VERSION ""

NS_ :

BS_:

BU_: EMS EAS

BO_ 2566764542 DM25: 13 Vector__XXX
 SG_ OccurenceCount1 : 32|7@1+ (1,0) [0|126] "" Vector__XXX
 SG_ SPNConversionMethod1 : 39|1@1+ (1,0) [0|1] "" Vector__XXX
 SG_ FailureModeIdentifier1 : 24|5@1+ (1,0) [0|0] "" Vector__XXX
 SG_ SPN1 : 8|16@1+ (1,0) [0|65536] "" Vector__XXX
 SG_ ExpandedFreezeFrameLength : 0|8@1+ (1,0) [0|255] "byte" Vector__XXX
 SG_ SPN1High : 29|3@1+ (1,0) [0|7] "" Vector__XXX

BO_ 2566764286 DM24: 12 Vector__XXX
 SG_ SPNSupported1High : 21|3@1+ (1,0) [0|7] "" Vector__XXX
 SG_ SPNSupportTypeSTR3 : 82|1@1+ (1,0) [0|1] "" Vector__XXX
 SG_ SPNSupportTypeSTR2 : 50|1@1+ (1,0) [0|1] "" Vector__XXX
 SG_ SPNSupportTypeEFF3 : 80|1@1+ (1,0) [0|1] "" Vector__XXX
 SG_ SPNSupportTypeEFF2 : 48|1@1+ (1,0) [0|1] "" Vector__XXX
 SG_ SPNSupportTypeDS3 : 81|1@1+ (1,0) [0|1] "" Vector__XXX
 SG_ SPNSupportTypeDS2 : 49|1@1+ (1,0) [0|1] "" Vector__XXX
 SG_ SPNSupported3High : 85|3@1+ (1,0) [0|7] "" Vector__XXX
 SG_ SPNSupported2High : 53|3@1+ (1,0) [0|7] "" Vector__XXX
 SG_ SPNSupported3 : 64|16@1+ (1,0) [0|65535] "" Vector__XXX
 SG_ SPNSupported2 : 32|16@1+ (1,0) [0|65535] "" Vector__XXX
 SG_ SPNDataLength3 : 88|8@1+ (1,0) [0|240] "" Vector__XXX
 SG_ SPNSupportTypeSTR1 : 18|1@1+ (1,0) [0|1] "" Vector__XXX
 SG_ SPNSupportTypeDS1 : 17|1@1+ (1,0) [0|1] "" Vector__XXX
 SG_ SPNSupportTypeEFF1 : 16|1@1+ (1,0) [0|1] "" Vector__XXX
 SG_ SPNDataLength2 : 56|8@1+ (1,0) [0|240] "" Vector__XXX
 SG_ SPNDataLength1 : 24|8@1+ (1,0) [0|240] "" Vector__XXX
 SG_ SPNSupported1 : 0|16@1+ (1,0) [0|65535] "" Vector__XXX

BO_ 2555576062 DM23: 22 Vector__XXX
 SG_ FlashRedStopLamp : 12|2@1+ (1,0) [0|3] "" Vector__XXX
 SG_ FlashProtectLamp : 8|2@1+ (1,0) [0|3] "" Vector__XXX
 SG_ FlashMalfuncIndicatorLamp : 14|2@1+ (1,0) [0|3] "" Vector__XXX
 SG_ SPN5 : 144|16@1+ (1,0) [0|65536] "" Vector__XXX
 SG_ SPN4 : 112|16@1+ (1,0) [0|65536] "" Vector__XXX
 SG_ SPN3 : 80|16@1+ (1,0) [0|65536] "" Vector__XXX
 SG_ SPN2 : 48|16@1+ (1,0) [0|65536] "" Vector__XXX
 SG_ FlashAmberWarningLamp : 10|2@1+ (1,0) [0|3] "" Vector__XXX
 SG_ FailureModeIdentifier5 : 160|5@1+ (1,0) [0|0] "" Vector__XXX
 SG_ FailureModeIdentifier4 : 128|5@1+ (1,0) [0|0] "" Vector__XXX
 SG_ OccurenceCount1 : 40|7@1+ (1,0) [0|126] "" Vector__XXX
 SG_ SPNConversionMethod1 : 47|1@1+ (1,0) [0|1] "" Vector__XXX
 SG_ FailureModeIdentifier1 : 32|5@1+ (1,0) [0|0] "" Vector__XXX
 SG_ SPN1 : 16|16@1+ (1,0) [0|65536] "" Vector__XXX
 SG_ MalfunctionIndicatorLampStatus : 6|2@1+ (1,0) [0|3] "" Vector__XXX
 SG_ RedStopLampState : 4|2@1+ (1,0) [0|3] "" Vector__XXX
 SG_ AmberWarningLampStatus : 2|2@1+ (1,0) [0|3] "" Vector__XXX
 SG_ ProtectLampStatus : 0|2@1+ (1,0) [0|3] "" Vector__XXX
 SG_ FailureModeIdentifier3 : 96|5@1+ (1,0) [0|0] "" Vector__XXX
 SG_ FailureModeIdentifier2 : 64|5@1+ (1,0) [0|0] "" Vector__XXX
 SG_ SPNConversionMethod5 : 175|1@1+ (1,0) [0|1] "" Vector__XXX
 SG_ SPNConversionMethod4 : 143|1@1+ (1,0) [0|1] "" Vector__XXX
 SG_ SPNConversionMethod3 : 111|1@1+ (1,0) [0|1] "" Vector__XXX
 SG_ SPNConversionMethod2 : 79|1@1+ (1,0) [0|1] "" Vector__XXX
 SG_ OccurenceCount5 : 168|7@1+ (1,0) [0|126] "" Vector__XXX
 SG_ OccurenceCount4 : 136|7@1+ (1,0) [0|126] "" Vector__XXX
 SG_ OccurenceCount3 : 104|7@1+ (1,0) [0|126] "" Vector__XXX
 SG_ OccurenceCount2 : 72|7@1+ (1,0) [0|126] "" Vector__XXX
 SG_ SPN5High : 165|3@1+ (1,0) [0|7] "" Vector__XXX
 SG_ SPN4High : 133|3@1+ (1,0) [0|7] "" Vector__XXX
 SG_ SPN3High : 101|3@1+ (1,0) [0|7] "" Vector__XXX
 SG_ SPN2High : 69|3@1+ (1,0) [0|7] "" Vector__XXX
 SG_ SPN1High : 37|3@1+ (1,0) [0|7] "" Vector__XXX

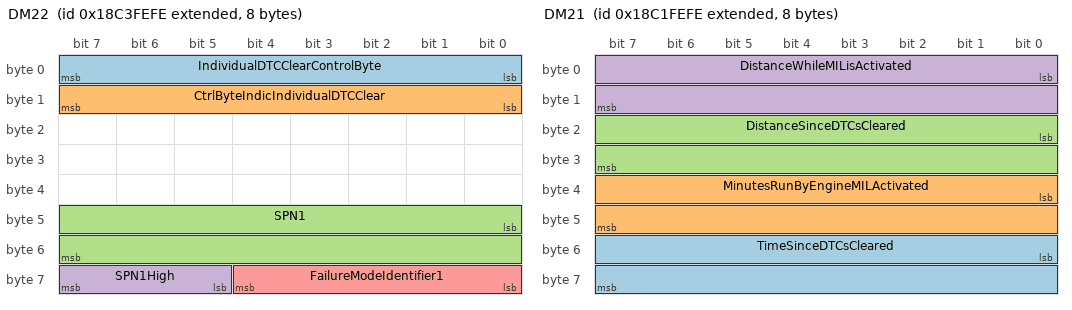
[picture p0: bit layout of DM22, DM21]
BO_ 2562981630 DM22: 8 Vector__XXX
 SG_ IndividualDTCClearControlByte : 0|8@1+ (1,0) [0|255] "" Vector__XXX
 SG_ CtrlByteIndicIndividualDTCClear : 8|8@1+ (1,0) [0|255] "" Vector__XXX
 SG_ SPN1 : 40|16@1+ (1,0) [0|65536] "" Vector__XXX
 SG_ SPN1High : 61|3@1+ (1,0) [0|7] "" Vector__XXX
 SG_ FailureModeIdentifier1 : 56|5@1+ (1,0) [0|0] "" Vector__XXX

BO_ 2562850558 DM21: 8 Vector__XXX
 SG_ TimeSinceDTCsCleared : 48|16@1+ (1,0) [0|64255] "min" Vector__XXX
 SG_ MinutesRunByEngineMILActivated : 32|16@1+ (1,0) [0|64255] "min" Vector__XXX
 SG_ DistanceSinceDTCsCleared : 16|16@1+ (1,0) [0|64255] "km" Vector__XXX
 SG_ DistanceWhileMILisActivated : 0|16@1+ (1,0) [0|64255] "km" Vector__XXX

BO_ 2562916094 DM20: 11 Vector__XXX
 SG_ ApplSysMonitorDenominator : 72|16@1+ (1,0) [0|65535] "" Vector__XXX
 SG_ ApplSysMonitorNumerator : 56|16@1+ (1,0) [0|65535] "" Vector__XXX
 SG_ SPNofApplSysMonitor : 32|24@1+ (1,0) [0|524287] "" Vector__XXX
 SG_ OBDMonitoringCondEncountered : 16|16@1+ (1,0) [0|65535] "" Vector__XXX
 SG_ IgnitionCycleCounter : 0|16@1+ (1,0) [0|65535] "" Vector__XXX

BO_ 2566835198 DM2: 22 Vector__XXX
 SG_ SPN5 : 144|16@1+ (1,0) [0|65536] "" Vector__XXX
 SG_ SPN4 : 112|16@1+ (1,0) [0|65536] "" Vector__XXX
 SG_ SPN3 : 80|16@1+ (1,0) [0|65536] "" Vector__XXX
 SG_ SPN2 : 48|16@1+ (1,0) [0|65536] "" Vector__XXX
 SG_ FailureModeIdentifier5 : 160|5@1+ (1,0) [0|0] "" Vector__XXX
 SG_ FailureModeIdentifier4 : 128|5@1+ (1,0) [0|0] "" Vector__XXX
 SG_ OccurenceCount1 : 40|7@1+ (1,0) [0|126] "" Vector__XXX
 SG_ SPNConversionMethod1 : 47|1@1+ (1,0) [0|1] "" Vector__XXX
 SG_ FailureModeIdentifier1 : 32|5@1+ (1,0) [0|0] "" Vector__XXX
 SG_ SPN1 : 16|16@1+ (1,0) [0|65536] "" Vector__XXX
 SG_ MalfunctionIndicatorLampStatus : 6|2@1+ (1,0) [0|3] "" Vector__XXX
 SG_ RedStopLampState : 4|2@1+ (1,0) [0|3] "" Vector__XXX
 SG_ AmberWarningLampStatus : 2|2@1+ (1,0) [0|3] "" Vector__XXX
 SG_ ProtectLampStatus : 0|2@1+ (1,0) [0|3] "" Vector__XXX
 SG_ FailureModeIdentifier3 : 96|5@1+ (1,0) [0|0] "" Vector__XXX
 SG_ FlashRedStopLamp : 12|2@1+ (1,0) [0|3] "" Vector__XXX
 SG_ FlashProtectLamp : 8|2@1+ (1,0) [0|3] "" Vector__XXX
 SG_ FlashMalfuncIndicatorLamp : 14|2@1+ (1,0) [0|3] "" Vector__XXX
 SG_ FlashAmberWarningLamp : 10|2@1+ (1,0) [0|3] "" Vector__XXX
 SG_ FailureModeIdentifier2 : 64|5@1+ (1,0) [0|0] "" Vector__XXX
 SG_ SPNConversionMethod5 : 175|1@1+ (1,0) [0|1] "" Vector__XXX
 SG_ SPNConversionMethod4 : 143|1@1+ (1,0) [0|1] "" Vector__XXX
 SG_ SPNConversionMethod3 : 111|1@1+ (1,0) [0|1] "" Vector__XXX
 SG_ SPNConversionMethod2 : 79|1@1+ (1,0) [0|1] "" Vector__XXX
 SG_ OccurenceCount5 : 168|7@1+ (1,0) [0|126] "" Vector__XXX
 SG_ OccurenceCount4 : 136|7@1+ (1,0) [0|126] "" Vector__XXX
 SG_ OccurenceCount3 : 104|7@1+ (1,0) [0|126] "" Vector__XXX
 SG_ OccurenceCount2 : 72|7@1+ (1,0) [0|126] "" Vector__XXX
 SG_ SPN5High : 165|3@1+ (1,0) [0|7] "" Vector__XXX
 SG_ SPN4High : 133|3@1+ (1,0) [0|7] "" Vector__XXX
 SG_ SPN3High : 101|3@1+ (1,0) [0|7] "" Vector__XXX
 SG_ SPN2High : 69|3@1+ (1,0) [0|7] "" Vector__XXX
 SG_ SPN1High : 37|3@1+ (1,0) [0|7] "" Vector__XXX

BO_ 2564030206 DM19: 20 Vector__XXX
 SG_ CalibrationID4 : 128|32@1+ (1,0) [0|4294967295] "" Vector__XXX
 SG_ CalibrationID3 : 96|32@1+ (1,0) [0|4294967295] "" Vector__XXX
 SG_ CalibrationID2 : 64|32@1+ (1,0) [0|4294967295] "" Vector__XXX
 SG_ CalibrationID1 : 32|32@1+ (1,0) [0|4294967295] "" Vector__XXX
 SG_ CalibrationVerificationNumber : 0|32@1+ (1,0) [0|4294967295] "" Vector__XXX

BO_ 2564226814 DM17: 8 Vector__XXX

BO_ 2564292350 DM16: 8 Vector__XXX
 SG_ NumberOfOccurance : 0|8@1+ (1,0) [0|0] "" Vector__XXX

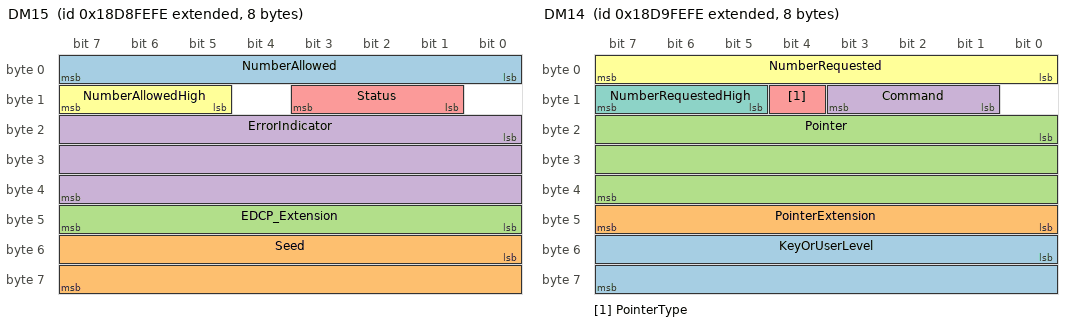
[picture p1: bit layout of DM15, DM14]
BO_ 2564357886 DM15: 8 Vector__XXX
 SG_ NumberAllowed : 0|8@1+ (1,0) [0|2047] "" Vector__XXX
 SG_ Seed : 48|16@1+ (1,0) [0|65535] "" Vector__XXX
 SG_ EDCP_Extension : 40|8@1+ (1,0) [0|255] "" Vector__XXX
 SG_ ErrorIndicator : 16|24@1+ (1,0) [0|16777215] "" Vector__XXX
 SG_ Status : 9|3@1+ (1,0) [0|7] "" Vector__XXX
 SG_ NumberAllowedHigh : 13|3@1+ (1,0) [0|7] "" Vector__XXX

BO_ 2564423422 DM14: 8 Vector__XXX
 SG_ KeyOrUserLevel : 48|16@1+ (1,0) [0|65535] "" Vector__XXX
 SG_ PointerExtension : 40|8@1+ (1,0) [0|255] "" Vector__XXX
 SG_ Pointer : 16|24@1+ (1,0) [0|16777215] "" Vector__XXX
 SG_ Command : 9|3@1+ (1,0) [0|7] "" Vector__XXX
 SG_ PointerType : 12|1@1+ (1,0) [0|1] "" Vector__XXX
 SG_ NumberRequested : 0|8@1+ (1,0) [0|2047] "" Vector__XXX
 SG_ NumberRequestedHigh : 13|3@1+ (1,0) [0|7] "" Vector__XXX

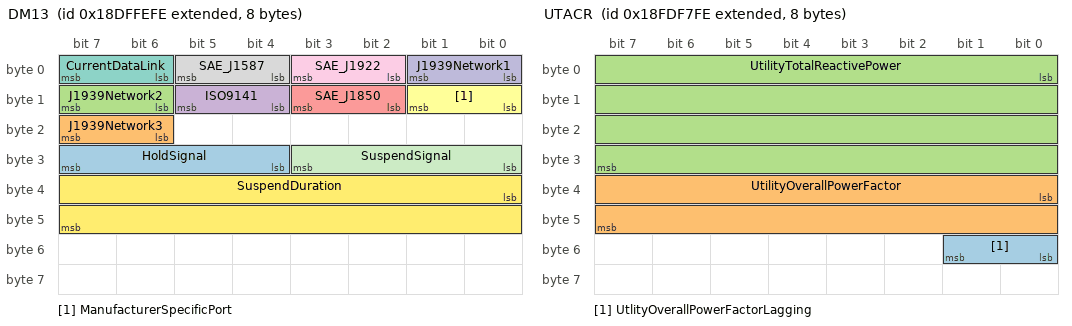
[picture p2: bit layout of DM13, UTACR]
BO_ 2564816638 DM13: 8 Vector__XXX
 SG_ HoldSignal : 28|4@1+ (1,0) [0|15] "" Vector__XXX
 SG_ J1939Network3 : 22|2@1+ (1,0) [0|3] "" Vector__XXX
 SG_ J1939Network2 : 14|2@1+ (1,0) [0|3] "" Vector__XXX
 SG_ ISO9141 : 12|2@1+ (1,0) [0|3] "" Vector__XXX
 SG_ SAE_J1850 : 10|2@1+ (1,0) [0|3] "" Vector__XXX
 SG_ ManufacturerSpecificPort : 8|2@1+ (1,0) [0|3] "" Vector__XXX
 SG_ CurrentDataLink : 6|2@1+ (1,0) [0|3] "" Vector__XXX
 SG_ SAE_J1587 : 4|2@1+ (1,0) [0|3] "" Vector__XXX
 SG_ SAE_J1922 : 2|2@1+ (1,0) [0|3] "" Vector__XXX
 SG_ J1939Network1 : 0|2@1+ (1,0) [0|3] "" Vector__XXX
 SG_ SuspendSignal : 24|4@1+ (1,0) [0|15] "" Vector__XXX
 SG_ SuspendDuration : 32|16@1+ (1,0) [0|64255] "seconds" Vector__XXX

BO_ 2566837502 DM12: 22 Vector__XXX
 SG_ SPN5 : 144|16@1+ (1,0) [0|65536] "" Vector__XXX
 SG_ SPN4 : 112|16@1+ (1,0) [0|65536] "" Vector__XXX
 SG_ SPN3 : 80|16@1+ (1,0) [0|65536] "" Vector__XXX
 SG_ SPN2 : 48|16@1+ (1,0) [0|65536] "" Vector__XXX
 SG_ FlashRedStopLamp : 12|2@1+ (1,0) [0|3] "" Vector__XXX
 SG_ FlashProtectLamp : 8|2@1+ (1,0) [0|3] "" Vector__XXX
 SG_ FailureModeIdentifier5 : 160|5@1+ (1,0) [0|0] "" Vector__XXX
 SG_ FailureModeIdentifier4 : 128|5@1+ (1,0) [0|0] "" Vector__XXX
 SG_ FailureModeIdentifier3 : 96|5@1+ (1,0) [0|0] "" Vector__XXX
 SG_ OccurenceCount1 : 40|7@1+ (1,0) [0|126] "" Vector__XXX
 SG_ SPNConversionMethod1 : 47|1@1+ (1,0) [0|1] "" Vector__XXX
 SG_ FailureModeIdentifier1 : 32|5@1+ (1,0) [0|0] "" Vector__XXX
 SG_ SPN1 : 16|16@1+ (1,0) [0|65536] "" Vector__XXX
 SG_ MalfunctionIndicatorLampStatus : 6|2@1+ (1,0) [0|3] "" Vector__XXX
 SG_ RedStopLampState : 4|2@1+ (1,0) [0|3] "" Vector__XXX
 SG_ AmberWarningLampStatus : 2|2@1+ (1,0) [0|3] "" Vector__XXX
 SG_ ProtectLampStatus : 0|2@1+ (1,0) [0|3] "" Vector__XXX
 SG_ FlashMalfuncIndicatorLamp : 14|2@1+ (1,0) [0|3] "" Vector__XXX
 SG_ FlashAmberWarningLamp : 10|2@1+ (1,0) [0|3] "" Vector__XXX
 SG_ FailureModeIdentifier2 : 64|5@1+ (1,0) [0|0] "" Vector__XXX
 SG_ SPNConversionMethod5 : 175|1@1+ (1,0) [0|1] "" Vector__XXX
 SG_ SPNConversionMethod4 : 143|1@1+ (1,0) [0|1] "" Vector__XXX
 SG_ SPNConversionMethod3 : 111|1@1+ (1,0) [0|1] "" Vector__XXX
 SG_ SPNConversionMethod2 : 79|1@1+ (1,0) [0|1] "" Vector__XXX
 SG_ OccurenceCount5 : 168|7@1+ (1,0) [0|126] "" Vector__XXX
 SG_ OccurenceCount4 : 136|7@1+ (1,0) [0|126] "" Vector__XXX
 SG_ OccurenceCount3 : 104|7@1+ (1,0) [0|126] "" Vector__XXX
 SG_ OccurenceCount2 : 72|7@1+ (1,0) [0|126] "" Vector__XXX
 SG_ SPN5High : 165|3@1+ (1,0) [0|7] "" Vector__XXX
 SG_ SPN4High : 133|3@1+ (1,0) [0|7] "" Vector__XXX
 SG_ SPN3High : 101|3@1+ (1,0) [0|7] "" Vector__XXX
 SG_ SPN2High : 69|3@1+ (1,0) [0|7] "" Vector__XXX
 SG_ SPN1High : 37|3@1+ (1,0) [0|7] "" Vector__XXX

BO_ 2566837246 DM11: 0 Vector__XXX

BO_ 2566836990 DM10: 8 Vector__XXX
 SG_ TestIdentifierSupported : 0|64@1+ (1,0) [1|1.8446744074E+019] "" Vector__XXX

BO_ 2566834942 DM1: 22 Vector__XXX
 SG_ SPN5 : 144|16@1+ (1,0) [0|65536] "" Vector__XXX
 SG_ SPN4 : 112|16@1+ (1,0) [0|65536] "" Vector__XXX
 SG_ SPN3 : 80|16@1+ (1,0) [0|65536] "" Vector__XXX
 SG_ SPN2 : 48|16@1+ (1,0) [0|65536] "" Vector__XXX
 SG_ FailureModeIdentifier5 : 160|5@1+ (1,0) [0|0] "" Vector__XXX
 SG_ FailureModeIdentifier4 : 128|5@1+ (1,0) [0|0] "" Vector__XXX
 SG_ FailureModeIdentifier3 : 96|5@1+ (1,0) [0|0] "" Vector__XXX
 SG_ FlashRedStopLamp : 12|2@1+ (1,0) [0|3] "" Vector__XXX
 SG_ FlashProtectLamp : 8|2@1+ (1,0) [0|3] "" Vector__XXX
 SG_ FlashMalfuncIndicatorLamp : 14|2@1+ (1,0) [0|3] "" Vector__XXX
 SG_ FlashAmberWarningLamp : 10|2@1+ (1,0) [0|3] "" Vector__XXX
 SG_ MalfunctionIndicatorLampStatus : 6|2@1+ (1,0) [0|3] "" Vector__XXX
 SG_ AmberWarningLampStatus : 2|2@1+ (1,0) [0|3] "" Vector__XXX
 SG_ OccurenceCount1 : 40|7@1+ (1,0) [0|126] "" Vector__XXX
 SG_ SPNConversionMethod1 : 47|1@1+ (1,0) [0|1] "" Vector__XXX
 SG_ FailureModeIdentifier1 : 32|5@1+ (1,0) [0|0] "" Vector__XXX
 SG_ SPN1 : 16|16@1+ (1,0) [0|65536] "" Vector__XXX
 SG_ RedStopLampState : 4|2@1+ (1,0) [0|3] "" Vector__XXX
 SG_ ProtectLampStatus : 0|2@1+ (1,0) [0|3] "" Vector__XXX
 SG_ FailureModeIdentifier2 : 64|5@1+ (1,0) [0|0] "" Vector__XXX
 SG_ SPNConversionMethod5 : 175|1@1+ (1,0) [0|1] "" Vector__XXX
 SG_ SPNConversionMethod4 : 143|1@1+ (1,0) [0|1] "" Vector__XXX
 SG_ SPNConversionMethod3 : 111|1@1+ (1,0) [0|1] "" Vector__XXX
 SG_ SPNConversionMethod2 : 79|1@1+ (1,0) [0|1] "" Vector__XXX
 SG_ OccurenceCount5 : 168|7@1+ (1,0) [0|126] "" Vector__XXX
 SG_ OccurenceCount4 : 136|7@1+ (1,0) [0|126] "" Vector__XXX
 SG_ OccurenceCount3 : 104|7@1+ (1,0) [0|126] "" Vector__XXX
 SG_ OccurenceCount2 : 72|7@1+ (1,0) [0|126] "" Vector__XXX
 SG_ SPN5High : 165|3@1+ (1,0) [0|7] "" Vector__XXX
 SG_ SPN4High : 133|3@1+ (1,0) [0|7] "" Vector__XXX
 SG_ SPN3High : 101|3@1+ (1,0) [0|7] "" Vector__XXX
 SG_ SPN2High : 69|3@1+ (1,0) [0|7] "" Vector__XXX
 SG_ SPN1High : 37|3@1+ (1,0) [0|7] "" Vector__XXX

BO_ 2566780926 UTACR: 8 Vector__XXX
 SG_ UtlityOverallPowerFactorLagging : 48|2@1+ (1,0) [0|3] "" Vector__XXX
 SG_ UtilityOverallPowerFactor : 32|16@1+ (1,-1) [-1|2.92181] "" Vector__XXX
 SG_ UtilityTotalReactivePower : 0|32@1+ (1,-2000000000) [-2000000000|2211081215] "VA" Vector__XXX

BO_ 2566781182 UTACP: 8 Vector__XXX
 SG_ UtilityTotalApparentPower : 32|32@1+ (1,-2000000000) [-2000000000|2211081215] "VA" Vector__XXX
 SG_ UtilityTotalRealPower : 0|32@1+ (1,-2000000000) [-2000000000|2211081215] "VA" Vector__XXX

BO_ 2566778366 UTACE: 8 Vector__XXX
 SG_ UtilityTotalKWHoursImport : 32|32@1+ (1,0) [0|4211081215] "kWh" Vector__XXX
 SG_ UtilityTotalKWHoursExport : 0|32@1+ (1,0) [0|4211081215] "kWh" Vector__XXX

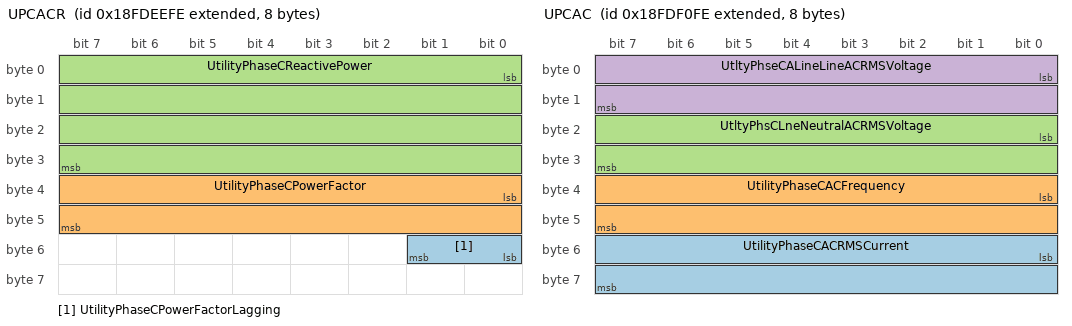
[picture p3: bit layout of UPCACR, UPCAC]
BO_ 2566778622 UPCACR: 8 Vector__XXX
 SG_ UtilityPhaseCPowerFactorLagging : 48|2@1+ (1,0) [0|3] "" Vector__XXX
 SG_ UtilityPhaseCPowerFactor : 32|16@1+ (1,-1) [-1|2.92181] "" Vector__XXX
 SG_ UtilityPhaseCReactivePower : 0|32@1+ (1,-2000000000) [-2000000000|2211081215] "VA" Vector__XXX

BO_ 2566778878 UPCACP: 8 Vector__XXX
 SG_ UtilityPhaseCApparentPower : 32|32@1+ (1,-2000000000) [-2000000000|2211081215] "VA" Vector__XXX
 SG_ UtilityPhaseCRealPower : 0|32@1+ (1,-2000000000) [-2000000000|2211081215] "VA" Vector__XXX

BO_ 2566779134 UPCAC: 8 Vector__XXX
 SG_ UtilityPhaseCACRMSCurrent : 48|16@1+ (1,0) [0|64255] "A" Vector__XXX
 SG_ UtilityPhaseCACFrequency : 32|16@1+ (1,0) [0|501.9921875] "Hz" Vector__XXX
 SG_ UtltyPhsCLneNeutralACRMSVoltage : 16|16@1+ (1,0) [0|64255] "V" Vector__XXX
 SG_ UtltyPhseCALineLineACRMSVoltage : 0|16@1+ (1,0) [0|64255] "V" Vector__XXX

BO_ 2566779390 UPBACR: 8 Vector__XXX
 SG_ UtilityPhaseBPowerFactorLagging : 48|2@1+ (1,0) [0|3] "" Vector__XXX
 SG_ UtilityPhaseBPowerFactor : 32|16@1+ (1,-1) [-1|2.92181] "" Vector__XXX
 SG_ UtilityPhaseBReactivePower : 0|32@1+ (1,-2000000000) [-2000000000|2211081215] "VA" Vector__XXX

BO_ 2566779646 UPBACP: 8 Vector__XXX
 SG_ UtilityPhaseBApparentPower : 32|32@1+ (1,-2000000000) [-2000000000|2211081215] "VA" Vector__XXX
 SG_ UtilityPhaseBRealPower : 0|32@1+ (1,-2000000000) [-2000000000|2211081215] "VA" Vector__XXX

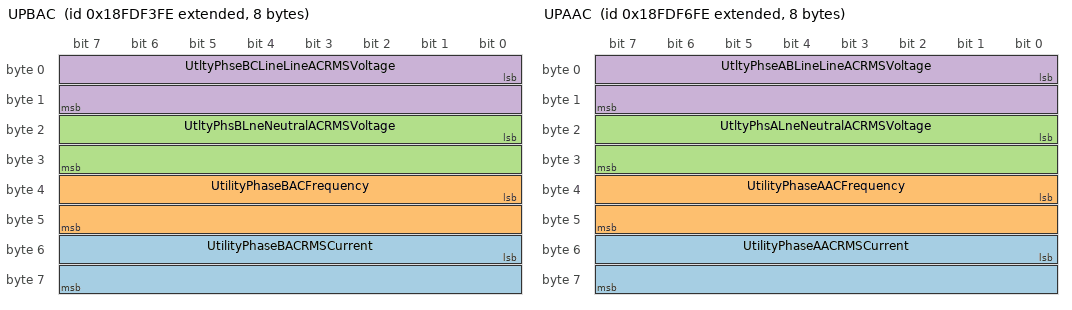
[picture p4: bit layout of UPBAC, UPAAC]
BO_ 2566779902 UPBAC: 8 Vector__XXX
 SG_ UtilityPhaseBACRMSCurrent : 48|16@1+ (1,0) [0|64255] "A" Vector__XXX
 SG_ UtilityPhaseBACFrequency : 32|16@1+ (1,0) [0|501.9921875] "Hz" Vector__XXX
 SG_ UtltyPhsBLneNeutralACRMSVoltage : 16|16@1+ (1,0) [0|64255] "V" Vector__XXX
 SG_ UtltyPhseBCLineLineACRMSVoltage : 0|16@1+ (1,0) [0|64255] "V" Vector__XXX

BO_ 2566780158 UPACCR: 8 Vector__XXX
 SG_ UtilityPhaseAPowerFactorLagging : 48|2@1+ (1,0) [0|3] "" Vector__XXX
 SG_ UtilityPhaseAPowerFactor : 32|16@1+ (1,-1) [-1|2.92181] "" Vector__XXX
 SG_ UtilityPhaseAReactivePower : 0|32@1+ (1,-2000000000) [-2000000000|2211081215] "VA" Vector__XXX

BO_ 2566780414 UPAACP: 8 Vector__XXX
 SG_ UtilityPhaseAApparentPower : 32|32@1+ (1,-2000000000) [-2000000000|2211081215] "VA" Vector__XXX
 SG_ UtilityPhaseARealPower : 0|32@1+ (1,-2000000000) [-2000000000|2211081215] "VA" Vector__XXX

BO_ 2566780670 UPAAC: 8 Vector__XXX
 SG_ UtilityPhaseAACRMSCurrent : 48|16@1+ (1,0) [0|64255] "A" Vector__XXX
 SG_ UtilityPhaseAACFrequency : 32|16@1+ (1,0) [0|501.9921875] "Hz" Vector__XXX
 SG_ UtltyPhsALneNeutralACRMSVoltage : 16|16@1+ (1,0) [0|64255] "V" Vector__XXX
 SG_ UtltyPhseABLineLineACRMSVoltage : 0|16@1+ (1,0) [0|64255] "V" Vector__XXX

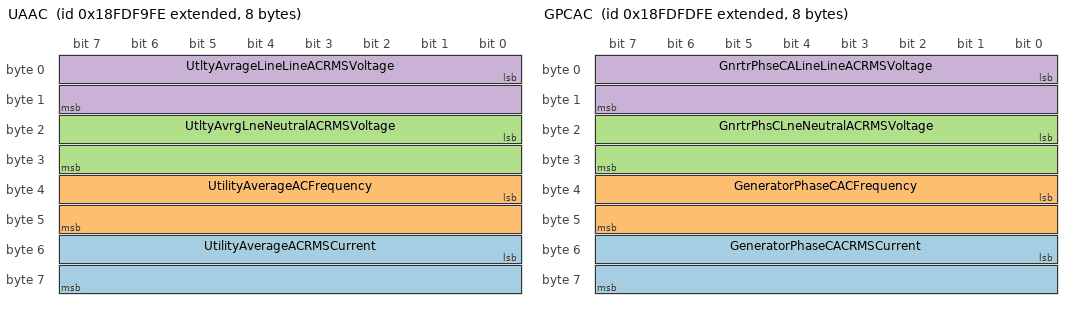
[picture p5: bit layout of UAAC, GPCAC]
BO_ 2566781438 UAAC: 8 Vector__XXX
 SG_ UtilityAverageACRMSCurrent : 48|16@1+ (1,0) [0|64255] "A" Vector__XXX
 SG_ UtilityAverageACFrequency : 32|16@1+ (1,0) [0|501.9921875] "Hz" Vector__XXX
 SG_ UtltyAvrgLneNeutralACRMSVoltage : 16|16@1+ (1,0) [0|64255] "V" Vector__XXX
 SG_ UtltyAvrageLineLineACRMSVoltage : 0|16@1+ (1,0) [0|64255] "V" Vector__XXX

BO_ 2566784254 GTACR: 8 Vector__XXX
 SG_ GnrtorOverallPowerFactorLagging : 48|2@1+ (1,0) [0|3] "" Vector__XXX
 SG_ GeneratorOverallPowerFactor : 32|16@1+ (1,-1) [-1|2.92181] "" Vector__XXX
 SG_ GeneratorTotalReactivePower : 0|32@1+ (1,-2000000000) [-2000000000|2211081215] "VA" Vector__XXX

BO_ 2566784510 GTACP: 8 Vector__XXX
 SG_ GeneratorTotalApparentPower : 32|32@1+ (1,-2000000000) [-2000000000|2211081215] "VA" Vector__XXX
 SG_ GeneratorTotalRealPower : 0|32@1+ (1,-2000000000) [-2000000000|2211081215] "VA" Vector__XXX

BO_ 2566781694 GTACE: 8 Vector__XXX
 SG_ GeneratorTotalKWHoursImport : 32|32@1+ (1,0) [0|4211081215] "kWh" Vector__XXX
 SG_ GeneratorTotalKWHoursExport : 0|32@1+ (1,0) [0|4211081215] "kWh" Vector__XXX

BO_ 2566781950 GPCACR: 8 Vector__XXX
 SG_ GnratorPhaseCPowerFactorLagging : 48|2@1+ (1,0) [0|3] "" Vector__XXX
 SG_ GeneratorPhaseCPowerFactor : 32|16@1+ (1,-1) [-1|2.92181] "" Vector__XXX
 SG_ GeneratorPhaseCReactivePower : 0|32@1+ (1,-2000000000) [-2000000000|2211081215] "VA" Vector__XXX

BO_ 2566782206 GPCACP: 8 Vector__XXX
 SG_ GeneratorPhaseCApparentPower : 32|32@1+ (1,-2000000000) [-2000000000|2211081215] "VA" Vector__XXX
 SG_ GeneratorPhaseCRealPower : 0|32@1+ (1,-2000000000) [-2000000000|2211081215] "VA" Vector__XXX

BO_ 2566782462 GPCAC: 8 Vector__XXX
 SG_ GeneratorPhaseCACRMSCurrent : 48|16@1+ (1,0) [0|64255] "A" Vector__XXX
 SG_ GeneratorPhaseCACFrequency : 32|16@1+ (1,0) [0|501.9921875] "Hz" Vector__XXX
 SG_ GnrtrPhsCLneNeutralACRMSVoltage : 16|16@1+ (1,0) [0|64255] "V" Vector__XXX
 SG_ GnrtrPhseCALineLineACRMSVoltage : 0|16@1+ (1,0) [0|64255] "V" Vector__XXX

BO_ 2566782718 GPBACRP: 8 Vector__XXX
 SG_ GnratorPhaseBPowerFactorLagging : 48|2@1+ (1,0) [0|3] "" Vector__XXX
 SG_ GeneratorPhaseBPowerFactor : 32|16@1+ (1,-1) [-1|2.92181] "" Vector__XXX
 SG_ GeneratorPhaseBReactivePower : 0|32@1+ (1,-2000000000) [-2000000000|2211081215] "VA" Vector__XXX

BO_ 2566782974 GPBACP: 8 Vector__XXX
 SG_ GeneratorPhaseBApparentPower : 32|32@1+ (1,-2000000000) [-2000000000|2211081215] "VA" Vector__XXX
 SG_ GeneratorPhaseBRealPower : 0|32@1+ (1,-2000000000) [-2000000000|2211081215] "VA" Vector__XXX

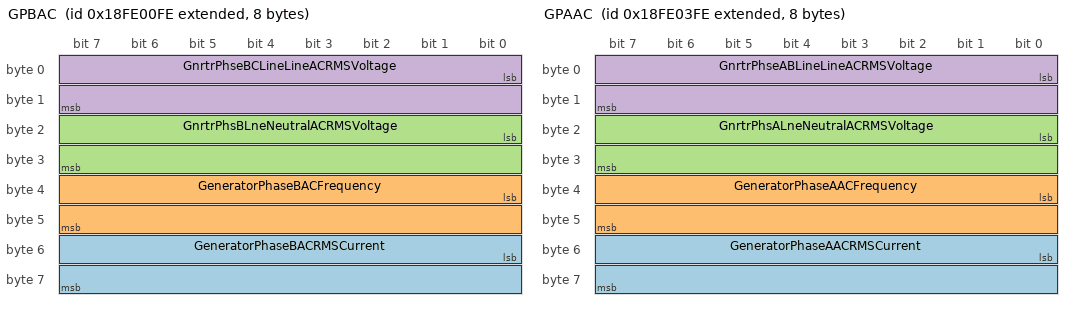
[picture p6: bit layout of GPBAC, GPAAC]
BO_ 2566783230 GPBAC: 8 Vector__XXX
 SG_ GeneratorPhaseBACRMSCurrent : 48|16@1+ (1,0) [0|64255] "A" Vector__XXX
 SG_ GeneratorPhaseBACFrequency : 32|16@1+ (1,0) [0|501.9921875] "Hz" Vector__XXX
 SG_ GnrtrPhsBLneNeutralACRMSVoltage : 16|16@1+ (1,0) [0|64255] "V" Vector__XXX
 SG_ GnrtrPhseBCLineLineACRMSVoltage : 0|16@1+ (1,0) [0|64255] "V" Vector__XXX

BO_ 2566783486 GPAACR: 8 Vector__XXX
 SG_ GnratorPhaseAPowerFactorLagging : 48|2@1+ (1,0) [0|3] "" Vector__XXX
 SG_ GeneratorPhaseAPowerFactor : 32|16@1+ (1,-1) [-1|2.92181] "" Vector__XXX
 SG_ GeneratorPhaseAReactivePower : 0|32@1+ (1,-2000000000) [-2000000000|2211081215] "VA" Vector__XXX

BO_ 2566783742 GPAACP: 8 Vector__XXX
 SG_ GeneratorPhaseAApparentPower : 32|32@1+ (1,-2000000000) [-2000000000|2211081215] "VA" Vector__XXX
 SG_ GeneratorPhaseARealPower : 0|32@1+ (1,-2000000000) [-2000000000|2211081215] "VA" Vector__XXX

BO_ 2566783998 GPAAC: 8 Vector__XXX
 SG_ GeneratorPhaseAACRMSCurrent : 48|16@1+ (1,0) [0|64255] "A" Vector__XXX
 SG_ GeneratorPhaseAACFrequency : 32|16@1+ (1,0) [0|501.9921875] "Hz" Vector__XXX
 SG_ GnrtrPhsALneNeutralACRMSVoltage : 16|16@1+ (1,0) [0|64255] "V" Vector__XXX
 SG_ GnrtrPhseABLineLineACRMSVoltage : 0|16@1+ (1,0) [0|64255] "V" Vector__XXX

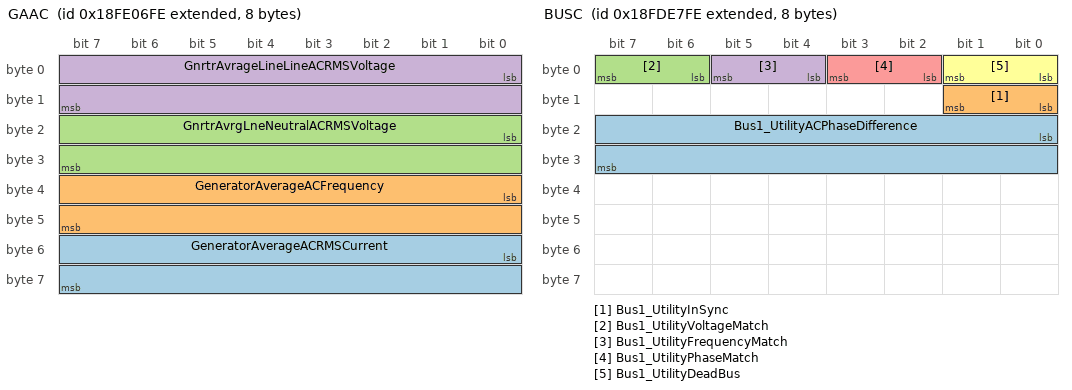
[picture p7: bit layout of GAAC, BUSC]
BO_ 2566784766 GAAC: 8 Vector__XXX
 SG_ GeneratorAverageACRMSCurrent : 48|16@1+ (1,0) [0|64255] "A" Vector__XXX
 SG_ GeneratorAverageACFrequency : 32|16@1+ (1,0) [0|501.9921875] "Hz" Vector__XXX
 SG_ GnrtrAvrgLneNeutralACRMSVoltage : 16|16@1+ (1,0) [0|64255] "V" Vector__XXX
 SG_ GnrtrAvrageLineLineACRMSVoltage : 0|16@1+ (1,0) [0|64255] "V" Vector__XXX

BO_ 2566776830 BUSC: 8 Vector__XXX
 SG_ Bus1_UtilityACPhaseDifference : 16|16@1+ (1,-200) [-200|301.99] "deg" Vector__XXX
 SG_ Bus1_UtilityInSync : 8|2@1+ (1,0) [0|3] "" Vector__XXX
 SG_ Bus1_UtilityVoltageMatch : 6|2@1+ (1,0) [0|3] "" Vector__XXX
 SG_ Bus1_UtilityFrequencyMatch : 4|2@1+ (1,0) [0|3] "" Vector__XXX
 SG_ Bus1_UtilityPhaseMatch : 2|2@1+ (1,0) [0|3] "" Vector__XXX
 SG_ Bus1_UtilityDeadBus : 0|2@1+ (1,0) [0|3] "" Vector__XXX

BO_ 2566777342 BPCAC: 8 Vector__XXX
 SG_ Bus1PhaseCACFrequency : 32|16@1+ (1,0) [0|501.9921875] "Hz" Vector__XXX
 SG_ Bs1PhseCLineNeutralACRMSVoltage : 16|16@1+ (1,0) [0|64255] "V" Vector__XXX
 SG_ Bus1PhaseCALineLineACRMSVoltage : 0|16@1+ (1,0) [0|64255] "V" Vector__XXX

BO_ 2566777598 BPBAC: 8 Vector__XXX
 SG_ Bus1PhaseBACFrequency : 32|16@1+ (1,0) [0|501.9921875] "Hz" Vector__XXX
 SG_ Bs1PhseBLineNeutralACRMSVoltage : 16|16@1+ (1,0) [0|64255] "V" Vector__XXX
 SG_ Bus1PhaseBCLineLineACRMSVoltage : 0|16@1+ (1,0) [0|64255] "V" Vector__XXX

BO_ 2566777854 BPAAC: 8 Vector__XXX
 SG_ Bus1PhaseAACFrequency : 32|16@1+ (1,0) [0|501.9921875] "Hz" Vector__XXX
 SG_ Bs1PhseALineNeutralACRMSVoltage : 16|16@1+ (1,0) [0|64255] "V" Vector__XXX
 SG_ Bus1PhaseABLineLineACRMSVoltage : 0|16@1+ (1,0) [0|64255] "V" Vector__XXX

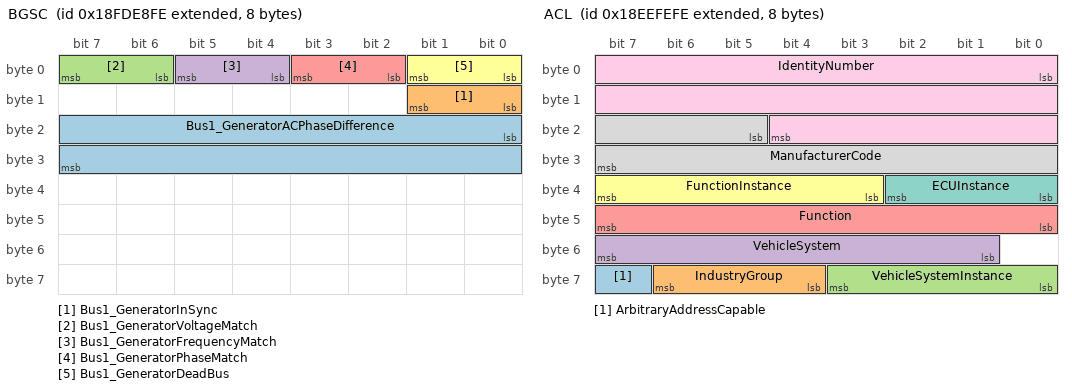
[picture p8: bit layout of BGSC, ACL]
BO_ 2566777086 BGSC: 8 Vector__XXX
 SG_ Bus1_GeneratorACPhaseDifference : 16|16@1+ (1,-200) [-200|301.99] "deg" Vector__XXX
 SG_ Bus1_GeneratorInSync : 8|2@1+ (1,0) [0|3] "" Vector__XXX
 SG_ Bus1_GeneratorVoltageMatch : 6|2@1+ (1,0) [0|3] "" Vector__XXX
 SG_ Bus1_GeneratorFrequencyMatch : 4|2@1+ (1,0) [0|3] "" Vector__XXX
 SG_ Bus1_GeneratorPhaseMatch : 2|2@1+ (1,0) [0|3] "" Vector__XXX
 SG_ Bus1_GeneratorDeadBus : 0|2@1+ (1,0) [0|3] "" Vector__XXX

BO_ 2566778110 BAAC: 8 Vector__XXX
 SG_ Bus1AverageACFrequency : 32|16@1+ (1,0) [0|501.9921875] "Hz" Vector__XXX
 SG_ Bs1AvrgeLineNeutralACRMSVoltage : 16|16@1+ (1,0) [0|64255] "V" Vector__XXX
 SG_ Bus1AverageLineLineACRMSVoltage : 0|16@1+ (1,0) [0|64255] "V" Vector__XXX

BO_ 2633895422 WSMSTR: 8 Vector__XXX
 SG_ NameOfWorkingSetMember : 0|64@1+ (1,0) [0|0] "" Vector__XXX

BO_ 2566838526 CA: 9 Vector__XXX
 SG_ ArbitraryAddressCapable : 63|1@1+ (1,0) [0|1] "" Vector__XXX
 SG_ IndustryGroup : 60|3@1+ (1,0) [0|7] "" Vector__XXX
 SG_ VehicleSystemInstance : 56|4@1+ (1,0) [0|15] "" Vector__XXX
 SG_ VehicleSystem : 49|7@1+ (1,0) [0|127] "" Vector__XXX
 SG_ Function : 40|8@1+ (1,0) [0|255] "" Vector__XXX
 SG_ FunctionInstance : 35|5@1+ (1,0) [0|31] "" Vector__XXX
 SG_ ECUInstance : 32|3@1+ (1,0) [0|7] "" Vector__XXX
 SG_ ManufacturerCode : 21|11@1+ (1,0) [0|2047] "" Vector__XXX
 SG_ IdentityNumber : 0|21@1+ (1,0) [0|2097152] "" Vector__XXX
 SG_ AddressAssignment : 64|8@1+ (1,0) [0|255] "" Vector__XXX

BO_ 2565799678 ACL: 8 Vector__XXX
 SG_ ArbitraryAddressCapable : 63|1@1+ (1,0) [0|1] "" Vector__XXX
 SG_ IndustryGroup : 60|3@1+ (1,0) [0|7] "" Vector__XXX
 SG_ VehicleSystemInstance : 56|4@1+ (1,0) [0|15] "" Vector__XXX
 SG_ VehicleSystem : 49|7@1+ (1,0) [0|127] "" Vector__XXX
 SG_ Function : 40|8@1+ (1,0) [0|255] "" Vector__XXX
 SG_ FunctionInstance : 35|5@1+ (1,0) [0|31] "" Vector__XXX
 SG_ ECUInstance : 32|3@1+ (1,0) [0|7] "" Vector__XXX
 SG_ ManufacturerCode : 21|11@1+ (1,0) [0|2047] "" Vector__XXX
 SG_ IdentityNumber : 0|21@1+ (1,0) [0|2097152] "" Vector__XXX

BO_ 2563440382 XFER: 8 Vector__XXX
 SG_ ShrtNameOfActualReportingDevice : 32|32@1+ (1,0) [0|0] "(2^32 - 1)" Vector__XXX
 SG_ LengthOfDataForTheReportedPGN : 24|8@1+ (1,0) [0|255] "" Vector__XXX
 SG_ PGNofRequstedInformation : 0|24@1+ (1,0) [0|16777215] "" Vector__XXX

BO_ 2565603070 TPDT: 8 Vector__XXX
 SG_ SequenceNumber : 0|8@1+ (1,0) [0|252] "" Vector__XXX

BO_ 2565668606 TPCM: 8 Vector__XXX
 SG_ TotalNumberOfPacketsEoMA m19 : 24|8@1+ (1,0) [0|255] "" Vector__XXX
 SG_ TotalMessageSizeEoMA m19 : 8|16@1+ (1,0) [0|64255] "counts" Vector__XXX
 SG_ TotalMessageSizeBAM m32 : 8|16@1+ (1,0) [0|64255] "counts" Vector__XXX
 SG_ TotalNumberOfPacketsBAM m32 : 24|8@1+ (1,0) [0|255] "" Vector__XXX
 SG_ ConnectionAbortReason m255 : 8|8@1+ (1,0) [0|255] "" Vector__XXX
 SG_ NextPacketNumberToBeSent m17 : 16|8@1+ (1,0) [0|255] "" Vector__XXX
 SG_ NumberOfPacketsThatCanBeSent m17 : 8|8@1+ (1,0) [0|255] "" Vector__XXX
 SG_ PGNumber : 40|24@1+ (1,0) [0|16777200] "" Vector__XXX
 SG_ MaximumNumberOfPackets m16 : 32|8@1+ (1,0) [0|255] "" Vector__XXX
 SG_ TotalNumberOfPackets m16 : 24|8@1+ (1,0) [0|255] "" Vector__XXX
 SG_ TotalMessageSize m16 : 8|16@1+ (1,0) [0|64255] "counts" Vector__XXX
 SG_ ControlByte M : 0|8@1+ (1,0) [0|255] "" Vector__XXX

BO_ 2563374846 RQST2: 8 Vector__XXX
 SG_ UseTransferMode : 24|2@1+ (1,0) [0|3] "" Vector__XXX
 SG_ ParameterGroupNumber : 0|24@1+ (1,0) [0|16777215] "" Vector__XXX

BO_ 2565537534 RQST: 3 Vector__XXX
 SG_ ParameterGroupNumber : 0|24@1+ (1,0) [0|16777215] "" Vector__XXX

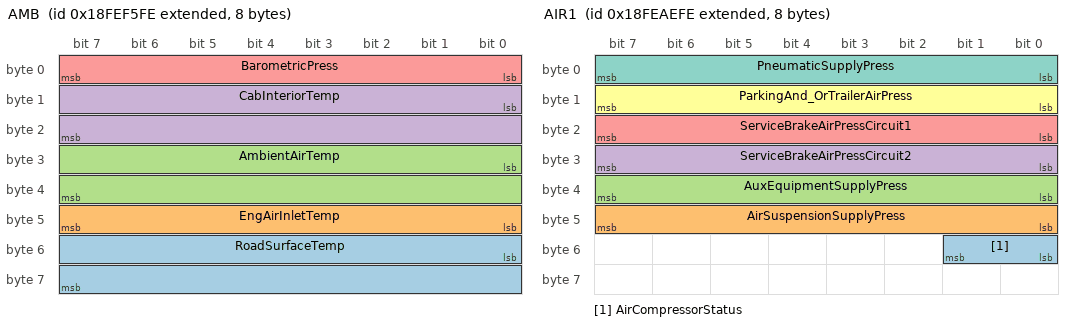
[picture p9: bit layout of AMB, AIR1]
BO_ 2566845950 AMB: 8 Vector__XXX
 SG_ RoadSurfaceTemp : 48|16@1+ (0.03125,-273) [-273|1735] "deg" Vector__XXX
 SG_ EngAirInletTemp : 40|8@1+ (1,-40) [-40|210] "deg" Vector__XXX
 SG_ AmbientAirTemp : 24|16@1+ (0.03125,-273) [-273|1735] "deg" Vector__XXX
 SG_ CabInteriorTemp : 8|16@1+ (0.03125,-273) [-273|1735] "deg" Vector__XXX
 SG_ BarometricPress : 0|8@1+ (0.5,0) [0|125] "kPa" Vector__XXX

BO_ 2566840062 AIR2: 8 Vector__XXX
 SG_ EngAirStartPress : 0|8@1+ (4,0) [0|1000] "kPa" Vector__XXX

BO_ 2566827774 AIR1: 8 Vector__XXX
 SG_ AirCompressorStatus : 48|2@1+ (1,0) [0|3] "" Vector__XXX
 SG_ AirSuspensionSupplyPress : 40|8@1+ (8,0) [0|2000] "kPa" Vector__XXX
 SG_ AuxEquipmentSupplyPress : 32|8@1+ (8,0) [0|2000] "kPa" Vector__XXX
 SG_ ServiceBrakeAirPressCircuit2 : 24|8@1+ (8,0) [0|2000] "kPa" Vector__XXX
 SG_ ServiceBrakeAirPressCircuit1 : 16|8@1+ (8,0) [0|2000] "kPa" Vector__XXX
 SG_ ParkingAnd_OrTrailerAirPress : 8|8@1+ (8,0) [0|2000] "kPa" Vector__XXX
 SG_ PneumaticSupplyPress : 0|8@1+ (8,0) [0|2000] "kPa" Vector__XXX

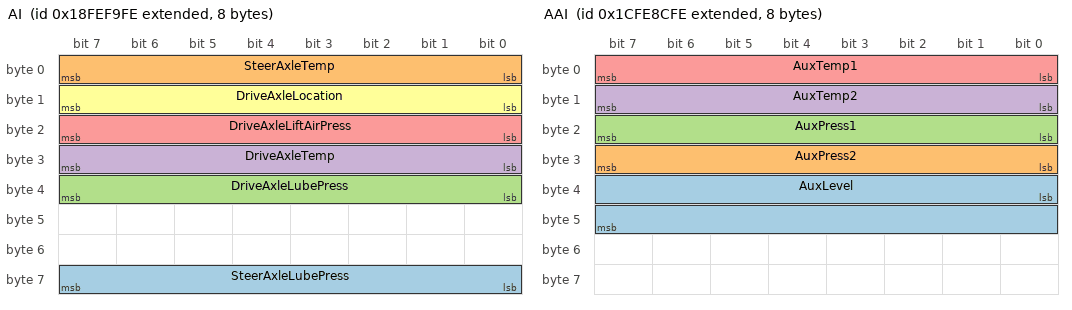
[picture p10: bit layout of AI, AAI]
BO_ 2566846974 AI: 8 Vector__XXX
 SG_ SteerAxleLubePress : 56|8@1+ (4,0) [0|1000] "kPa" Vector__XXX
 SG_ SteerAxleTemp : 0|8@1+ (1,-40) [-40|210] "deg" Vector__XXX
 SG_ DriveAxleLubePress : 32|8@1+ (4,0) [0|1000] "kPa" Vector__XXX
 SG_ DriveAxleTemp : 24|8@1+ (1,-40) [-40|210] "deg" Vector__XXX
 SG_ DriveAxleLiftAirPress : 16|8@1+ (4,0) [0|1000] "kPa" Vector__XXX
 SG_ DriveAxleLocation : 8|8@1+ (1,0) [0|255] "" Vector__XXX

BO_ 2633935614 AF2: 8 Vector__XXX
 SG_ EngTurboWastegateValvePos : 24|8@1+ (0.4,0) [0|100] "%" Vector__XXX
 SG_ EngGsMssFlwSnsrFelingCorrection : 32|8@1+ (1,-125) [-125|125] "%" Vector__XXX
 SG_ EngDsiredAbsIntakeManifoldPress : 8|16@1+ (0.1,0) [0|6425.5] "kPa" Vector__XXX
 SG_ EngGasFuelCorrectionFactor : 0|8@1+ (1,0) [0|250] "%" Vector__XXX

BO_ 2566803966 ACC2: 8 Vector__XXX
 SG_ RqedACCDistanceMode : 5|3@1+ (1,0) [0|7] "" Vector__XXX

BO_ 2432593918 ACC1: 8 Vector__XXX
 SG_ ACCDistanceAlertSignal : 52|2@1+ (1,0) [0|3] "" Vector__XXX
 SG_ ACCSystemShutoffWarning : 50|2@1+ (1,0) [0|3] "" Vector__XXX
 SG_ ACCTargetDetected : 48|2@1+ (1,0) [0|3] "" Vector__XXX
 SG_ RoadCurvature : 32|16@1+ (0.0078125,-250) [-250|251.992] "1/km" Vector__XXX
 SG_ AdptveCruiseCtrlSetDistanceMode : 27|3@1+ (1,0) [0|7] "" Vector__XXX
 SG_ AdaptiveCruiseCtrlMode : 24|3@1+ (1,0) [0|7] "" Vector__XXX
 SG_ AdaptiveCruiseCtrlSetSpeed : 16|8@1+ (1,0) [0|250] "km/h" Vector__XXX
 SG_ DistanceToForwardVehicle : 8|8@1+ (1,0) [0|250] "m" Vector__XXX
 SG_ SpeedOfForwardVehicle : 0|8@1+ (1,0) [0|250] "km/h" Vector__XXX

BO_ 2633935102 AC: 8 Vector__XXX
 SG_ ArticulationAngle : 0|8@1+ (1,-125) [-125|125] "deg" Vector__XXX

BO_ 2633927934 AAI: 8 Vector__XXX
 SG_ AuxLevel : 32|16@1+ (0.1,0) [0|6425.5] "mm" Vector__XXX
 SG_ AuxPress2 : 24|8@1+ (16,0) [0|4000] "kPa" Vector__XXX
 SG_ AuxPress1 : 16|8@1+ (16,0) [0|4000] "kPa" Vector__XXX
 SG_ AuxTemp2 : 8|8@1+ (1,-40) [-40|210] "deg" Vector__XXX
 SG_ AuxTemp1 : 0|8@1+ (1,-40) [-40|210] "deg" Vector__XXX

BO_ 2566847998 A1: 8 Vector__XXX
 SG_ EngBlowerBypassValvePos : 0|8@1+ (0.4,0) [0|100] "%" Vector__XXX
 SG_ EngGasSupplyPress : 8|16@1+ (0.5,0) [0|32127.5] "kPa" Vector__XXX

BO_ 2565406462 ACKM: 8 Vector__XXX
 SG_ AddressBusy m3 : 32|8@1+ (1,0) [0|255] "" Vector__XXX
 SG_ ParameterGroupNumber : 40|24@1+ (1,0) [0|16777215] "" Vector__XXX
 SG_ GroupFunctionValue : 8|8@1+ (1,0) [0|255] "" Vector__XXX
 SG_ ControlByte M : 0|8@1+ (1,0) [0|255] "" Vector__XXX
 SG_ AddressAccessDenied m2 : 32|8@1+ (1,0) [0|255] "" Vector__XXX
 SG_ AddressNegativeAcknowledgement m1 : 32|8@1+ (1,0) [0|255] "" Vector__XXX
 SG_ AddressAcknowledged m0 : 32|8@1+ (1,0) [0|255] "" Vector__XXX

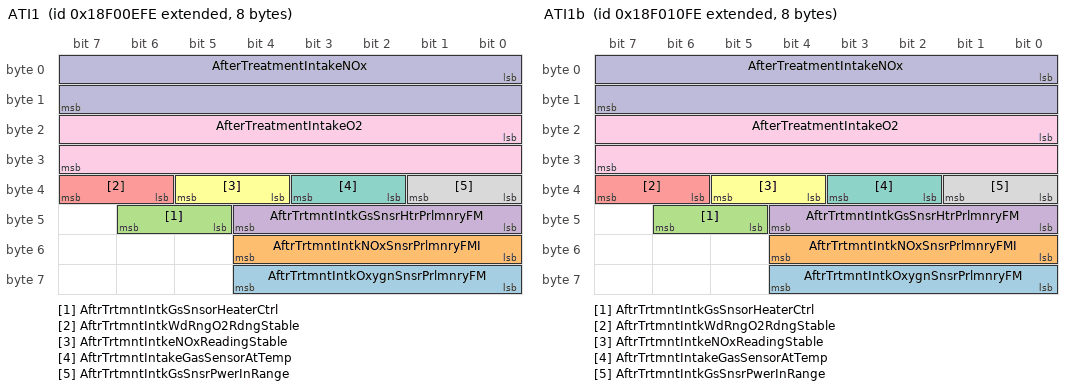
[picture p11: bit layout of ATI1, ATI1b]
BO_ 2565869310 ATI1: 8 Vector__XXX
 SG_ AftrTrtmntIntkOxygnSnsrPrlmnryFM : 56|5@1+ (1,0) [0|31] "" Vector__XXX
 SG_ AftrTrtmntIntkNOxSnsrPrlmnryFMI : 48|5@1+ (1,0) [0|31] "" Vector__XXX
 SG_ AftrTrtmntIntkGsSnsorHeaterCtrl : 45|2@1+ (1,0) [0|3] "" Vector__XXX
 SG_ AftrTrtmntIntkGsSnsrHtrPrlmnryFM : 40|5@1+ (1,0) [0|31] "" Vector__XXX
 SG_ AftrTrtmntIntkWdRngO2RdngStable : 38|2@1+ (1,0) [0|3] "" Vector__XXX
 SG_ AftrTrtmntIntkeNOxReadingStable : 36|2@1+ (1,0) [0|3] "" Vector__XXX
 SG_ AftrTrtmntIntakeGasSensorAtTemp : 34|2@1+ (1,0) [0|3] "" Vector__XXX
 SG_ AftrTrtmntIntkGsSnsrPwerInRange : 32|2@1+ (1,0) [0|3] "" Vector__XXX
 SG_ AfterTreatmentIntakeO2 : 16|16@1+ (0.000514,-12) [-12|21] "%" Vector__XXX
 SG_ AfterTreatmentIntakeNOx : 0|16@1+ (0.05,-200) [-200|3012.75] "ppm" Vector__XXX

BO_ 2565869822 ATI1b: 8 Vector__XXX
 SG_ AftrTrtmntIntkOxygnSnsrPrlmnryFM : 56|5@1+ (1,0) [0|31] "" Vector__XXX
 SG_ AftrTrtmntIntkNOxSnsrPrlmnryFMI : 48|5@1+ (1,0) [0|31] "" Vector__XXX
 SG_ AftrTrtmntIntkGsSnsorHeaterCtrl : 45|2@1+ (1,0) [0|3] "" Vector__XXX
 SG_ AftrTrtmntIntkGsSnsrHtrPrlmnryFM : 40|5@1+ (1,0) [0|31] "" Vector__XXX
 SG_ AftrTrtmntIntkWdRngO2RdngStable : 38|2@1+ (1,0) [0|3] "" Vector__XXX
 SG_ AftrTrtmntIntkeNOxReadingStable : 36|2@1+ (1,0) [0|3] "" Vector__XXX
 SG_ AftrTrtmntIntakeGasSensorAtTemp : 34|2@1+ (1,0) [0|3] "" Vector__XXX
 SG_ AftrTrtmntIntkGsSnsrPwerInRange : 32|2@1+ (1,0) [0|3] "" Vector__XXX
 SG_ AfterTreatmentIntakeO2 : 16|16@1+ (0.000514,-12) [-12|21] "%" Vector__XXX
 SG_ AfterTreatmentIntakeNOx : 0|16@1+ (0.05,-200) [-200|3012.75] "ppm" Vector__XXX

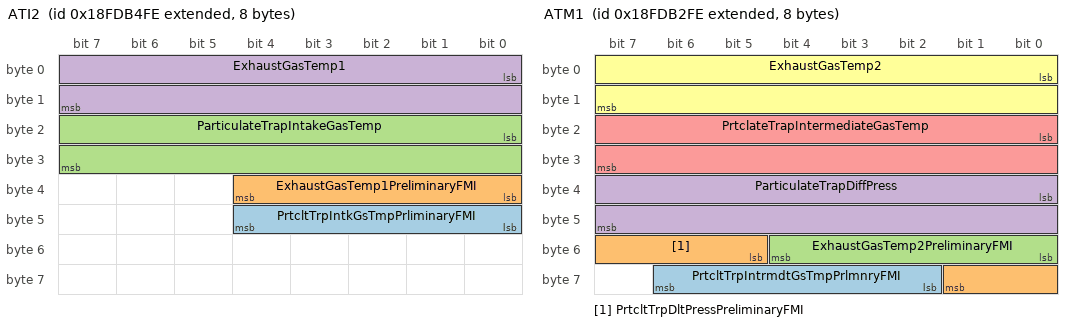
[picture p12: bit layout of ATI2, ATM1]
BO_ 2566763774 ATI2: 8 Vector__XXX
 SG_ PrtcltTrpIntkGsTmpPrliminaryFMI : 40|5@1+ (1,0) [0|31] "" Vector__XXX
 SG_ ExhaustGasTemp1PreliminaryFMI : 32|5@1+ (1,0) [0|31] "" Vector__XXX
 SG_ ParticulateTrapIntakeGasTemp : 16|16@1+ (0.03125,-273) [-273|1735] "deg" Vector__XXX
 SG_ ExhaustGasTemp1 : 0|16@1+ (0.03125,-273) [-273|1735] "deg" Vector__XXX

BO_ 2566763262 ATM1: 8 Vector__XXX
 SG_ PrtcltTrpIntrmdtGsTmpPrlmnryFMI : 58|5@1+ (1,0) [0|31] "" Vector__XXX
 SG_ PrtcltTrpDltPressPreliminaryFMI : 53|5@1+ (1,0) [0|31] "" Vector__XXX
 SG_ ExhaustGasTemp2PreliminaryFMI : 48|5@1+ (1,0) [0|31] "" Vector__XXX
 SG_ ParticulateTrapDiffPress : 32|16@1+ (0.1,0) [0|6425.5] "kPa" Vector__XXX
 SG_ PrtclateTrapIntermediateGasTemp : 16|16@1+ (0.03125,-273) [-273|1735] "deg" Vector__XXX
 SG_ ExhaustGasTemp2 : 0|16@1+ (0.03125,-273) [-273|1735] "deg" Vector__XXX

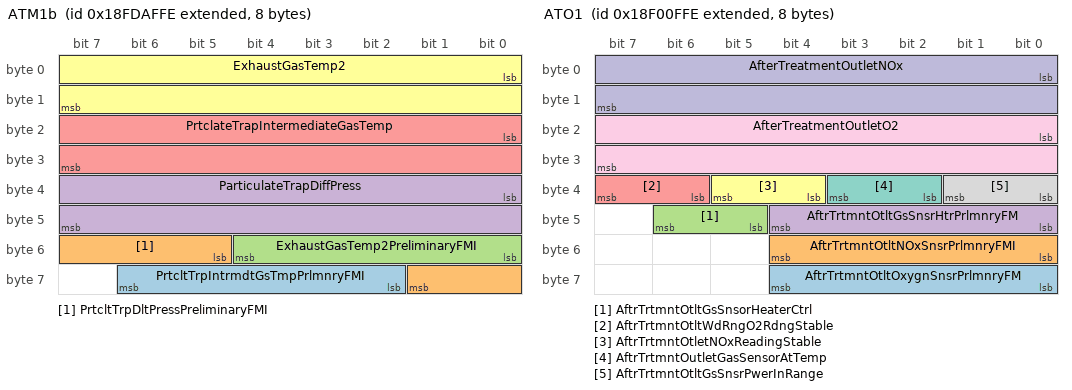
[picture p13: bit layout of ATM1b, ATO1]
BO_ 2566762494 ATM1b: 8 Vector__XXX
 SG_ PrtcltTrpIntrmdtGsTmpPrlmnryFMI : 58|5@1+ (1,0) [0|31] "" Vector__XXX
 SG_ PrtcltTrpDltPressPreliminaryFMI : 53|5@1+ (1,0) [0|31] "" Vector__XXX
 SG_ ExhaustGasTemp2PreliminaryFMI : 48|5@1+ (1,0) [0|31] "" Vector__XXX
 SG_ ParticulateTrapDiffPress : 32|16@1+ (0.1,0) [0|6425.5] "kPa" Vector__XXX
 SG_ PrtclateTrapIntermediateGasTemp : 16|16@1+ (0.03125,-273) [-273|1735] "deg" Vector__XXX
 SG_ ExhaustGasTemp2 : 0|16@1+ (0.03125,-273) [-273|1735] "deg" Vector__XXX

BO_ 2565869566 ATO1: 8 Vector__XXX
 SG_ AftrTrtmntOtltOxygnSnsrPrlmnryFM : 56|5@1+ (1,0) [0|31] "" Vector__XXX
 SG_ AftrTrtmntOtltNOxSnsrPrlmnryFMI : 48|5@1+ (1,0) [0|31] "" Vector__XXX
 SG_ AftrTrtmntOtltGsSnsorHeaterCtrl : 45|2@1+ (1,0) [0|3] "" Vector__XXX
 SG_ AftrTrtmntOtltGsSnsrHtrPrlmnryFM : 40|5@1+ (1,0) [0|31] "" Vector__XXX
 SG_ AftrTrtmntOtltWdRngO2RdngStable : 38|2@1+ (1,0) [0|3] "" Vector__XXX
 SG_ AftrTrtmntOtletNOxReadingStable : 36|2@1+ (1,0) [0|3] "" Vector__XXX
 SG_ AftrTrtmntOutletGasSensorAtTemp : 34|2@1+ (1,0) [0|3] "" Vector__XXX
 SG_ AftrTrtmntOtltGsSnsrPwerInRange : 32|2@1+ (1,0) [0|3] "" Vector__XXX
 SG_ AfterTreatmentOutletO2 : 16|16@1+ (0.000514,-12) [-12|21] "%" Vector__XXX
 SG_ AfterTreatmentOutletNOx : 0|16@1+ (0.05,-200) [-200|3012.75] "ppm" Vector__XXX

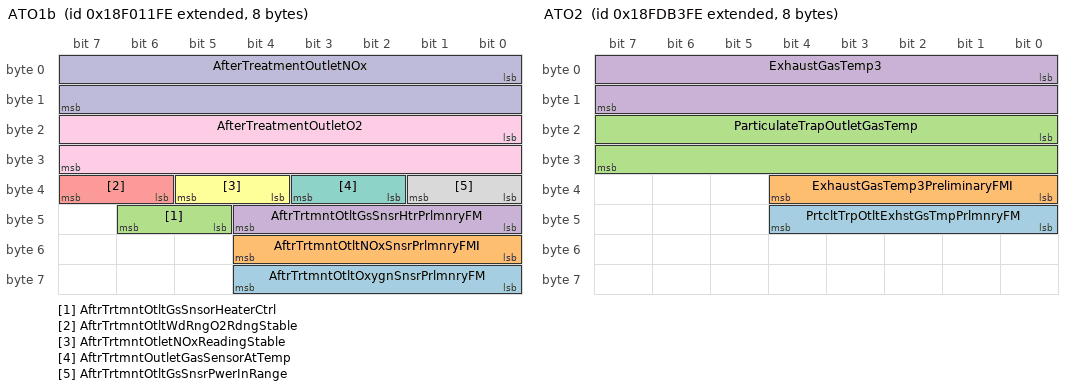
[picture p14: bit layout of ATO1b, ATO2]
BO_ 2565870078 ATO1b: 8 Vector__XXX
 SG_ AftrTrtmntOtltOxygnSnsrPrlmnryFM : 56|5@1+ (1,0) [0|31] "" Vector__XXX
 SG_ AftrTrtmntOtltNOxSnsrPrlmnryFMI : 48|5@1+ (1,0) [0|31] "" Vector__XXX
 SG_ AftrTrtmntOtltGsSnsorHeaterCtrl : 45|2@1+ (1,0) [0|3] "" Vector__XXX
 SG_ AftrTrtmntOtltGsSnsrHtrPrlmnryFM : 40|5@1+ (1,0) [0|31] "" Vector__XXX
 SG_ AftrTrtmntOtltWdRngO2RdngStable : 38|2@1+ (1,0) [0|3] "" Vector__XXX
 SG_ AftrTrtmntOtletNOxReadingStable : 36|2@1+ (1,0) [0|3] "" Vector__XXX
 SG_ AftrTrtmntOutletGasSensorAtTemp : 34|2@1+ (1,0) [0|3] "" Vector__XXX
 SG_ AftrTrtmntOtltGsSnsrPwerInRange : 32|2@1+ (1,0) [0|3] "" Vector__XXX
 SG_ AfterTreatmentOutletO2 : 16|16@1+ (0.000514,-12) [-12|21] "%" Vector__XXX
 SG_ AfterTreatmentOutletNOx : 0|16@1+ (0.05,-200) [-200|3012.75] "ppm" Vector__XXX

BO_ 2566763518 ATO2: 8 Vector__XXX
 SG_ PrtcltTrpOtltExhstGsTmpPrlmnryFM : 40|5@1+ (1,0) [0|31] "" Vector__XXX
 SG_ ExhaustGasTemp3PreliminaryFMI : 32|5@1+ (1,0) [0|31] "" Vector__XXX
 SG_ ParticulateTrapOutletGasTemp : 16|16@1+ (0.03125,-273) [-273|1735] "deg" Vector__XXX
 SG_ ExhaustGasTemp3 : 0|16@1+ (0.03125,-273) [-273|1735] "deg" Vector__XXX

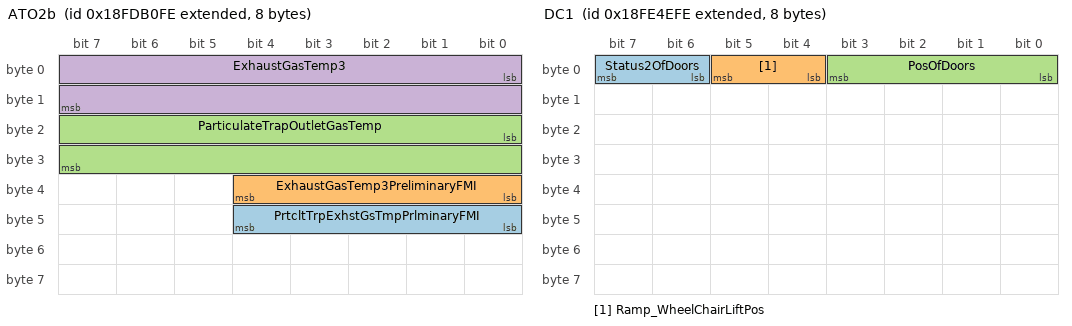
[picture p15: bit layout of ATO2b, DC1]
BO_ 2566762750 ATO2b: 8 Vector__XXX
 SG_ PrtcltTrpExhstGsTmpPrlminaryFMI : 40|5@1+ (1,0) [0|31] "" Vector__XXX
 SG_ ExhaustGasTemp3PreliminaryFMI : 32|5@1+ (1,0) [0|31] "" Vector__XXX
 SG_ ParticulateTrapOutletGasTemp : 16|16@1+ (0.03125,-273) [-273|1735] "deg" Vector__XXX
 SG_ ExhaustGasTemp3 : 0|16@1+ (0.03125,-273) [-273|1735] "deg" Vector__XXX

BO_ 2566803198 DC1: 8 Vector__XXX
 SG_ Status2OfDoors : 6|2@1+ (1,0) [0|3] "" Vector__XXX
 SG_ Ramp_WheelChairLiftPos : 4|2@1+ (1,0) [0|3] "" Vector__XXX
 SG_ PosOfDoors : 0|4@1+ (1,0) [0|15] "" Vector__XXX

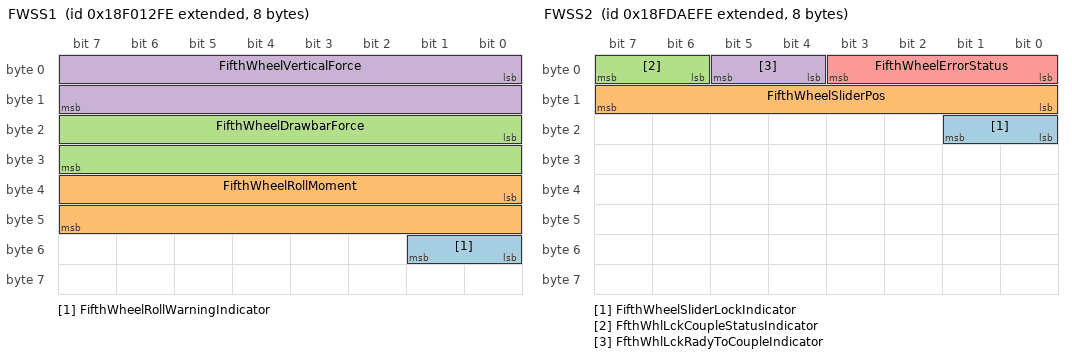
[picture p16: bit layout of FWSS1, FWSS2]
BO_ 2565870334 FWSS1: 8 Vector__XXX
 SG_ FifthWheelRollWarningIndicator : 48|2@1+ (1,0) [0|3] "" Vector__XXX
 SG_ FifthWheelRollMoment : 32|16@1+ (10,-320000) [-320000|322550] "N" Vector__XXX
 SG_ FifthWheelDrawbarForce : 16|16@1+ (10,-320000) [-320000|322550] "N" Vector__XXX
 SG_ FifthWheelVerticalForce : 0|16@1+ (5,0) [0|321275] "N" Vector__XXX

BO_ 2566762238 FWSS2: 8 Vector__XXX
 SG_ FifthWheelSliderLockIndicator : 16|2@1+ (1,0) [0|3] "" Vector__XXX
 SG_ FifthWheelSliderPos : 8|8@1+ (10,0) [0|2500] "mm" Vector__XXX
 SG_ FfthWhlLckCoupleStatusIndicator : 6|2@1+ (1,0) [0|3] "" Vector__XXX
 SG_ FfthWhlLckRadyToCoupleIndicator : 4|2@1+ (1,0) [0|3] "" Vector__XXX
 SG_ FifthWheelErrorStatus : 0|4@1+ (1,0) [0|15] "" Vector__XXX

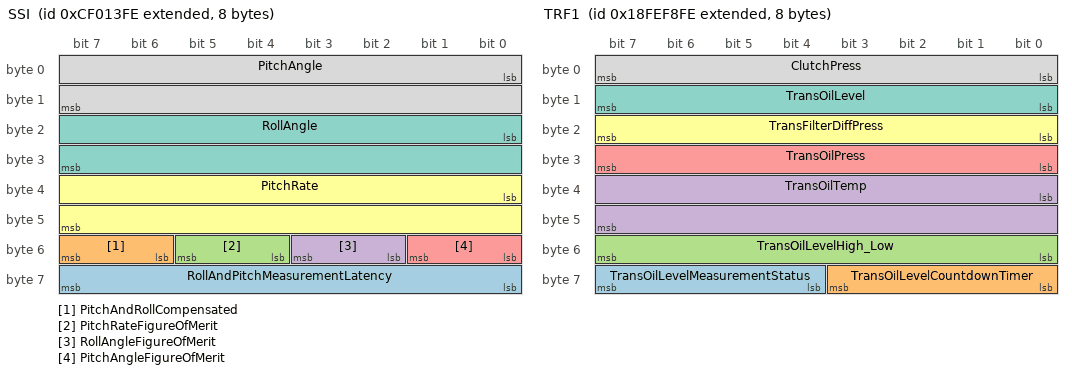
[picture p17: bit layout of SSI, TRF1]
BO_ 2364543998 SSI: 8 Vector__XXX
 SG_ RollAndPitchMeasurementLatency : 56|8@1+ (0.5,0) [0|125] "ms" Vector__XXX
 SG_ PitchAndRollCompensated : 54|2@1+ (1,0) [0|3] "" Vector__XXX
 SG_ PitchRateFigureOfMerit : 52|2@1+ (1,0) [0|3] "" Vector__XXX
 SG_ RollAngleFigureOfMerit : 50|2@1+ (1,0) [0|3] "" Vector__XXX
 SG_ PitchAngleFigureOfMerit : 48|2@1+ (1,0) [0|3] "" Vector__XXX
 SG_ PitchRate : 32|16@1+ (0.002,-64) [-64|64.51] "deg/sec" Vector__XXX
 SG_ RollAngle : 16|16@1+ (0.002,-64) [-64|64.51] "deg" Vector__XXX
 SG_ PitchAngle : 0|16@1+ (0.002,-64) [-64|64.51] "deg" Vector__XXX

BO_ 2566846718 TRF1: 8 Vector__XXX
 SG_ TransOilLevelMeasurementStatus : 60|4@1+ (1,0) [0|15] "" Vector__XXX
 SG_ TransOilLevelCountdownTimer : 56|4@1+ (1,0) [0|15] "" Vector__XXX
 SG_ TransOilLevelHigh_Low : 48|8@1+ (0.5,-62.5) [-62.5|62.5] "L" Vector__XXX
 SG_ TransOilTemp : 32|16@1+ (0.03125,-273) [-273|1735] "deg" Vector__XXX
 SG_ TransOilPress : 24|8@1+ (16,0) [0|4000] "kPa" Vector__XXX
 SG_ TransFilterDiffPress : 16|8@1+ (2,0) [0|500] "kPa" Vector__XXX
 SG_ TransOilLevel : 8|8@1+ (0.4,0) [0|100] "%" Vector__XXX
 SG_ ClutchPress : 0|8@1+ (16,0) [0|4000] "kPa" Vector__XXX

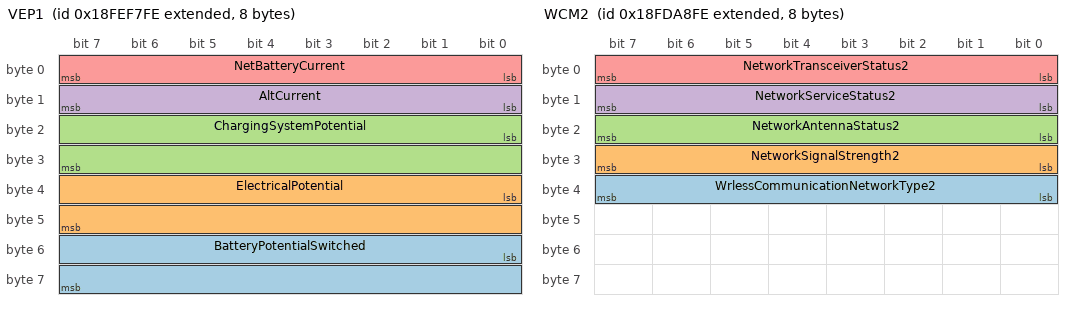
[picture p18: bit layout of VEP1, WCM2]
BO_ 2566846462 VEP1: 8 Vector__XXX
 SG_ BatteryPotentialSwitched : 48|16@1+ (0.05,0) [0|3212.75] "V" Vector__XXX
 SG_ ElectricalPotential : 32|16@1+ (0.05,0) [0|3212.75] "V" Vector__XXX
 SG_ ChargingSystemPotential : 16|16@1+ (0.05,0) [0|3212.75] "V" Vector__XXX
 SG_ AltCurrent : 8|8@1+ (1,0) [0|250] "A" Vector__XXX
 SG_ NetBatteryCurrent : 0|8@1+ (1,-125) [-125|125] "A" Vector__XXX

BO_ 2566760702 WCM2: 8 Vector__XXX
 SG_ WrlessCommunicationNetworkType2 : 32|8@1+ (1,0) [0|255] "" Vector__XXX
 SG_ NetworkSignalStrength2 : 24|8@1+ (0.4,0) [0|100] "%" Vector__XXX
 SG_ NetworkAntennaStatus2 : 16|8@1+ (1,0) [0|255] "" Vector__XXX
 SG_ NetworkServiceStatus2 : 8|8@1+ (1,0) [0|255] "" Vector__XXX
 SG_ NetworkTransceiverStatus2 : 0|8@1+ (1,0) [0|255] "" Vector__XXX

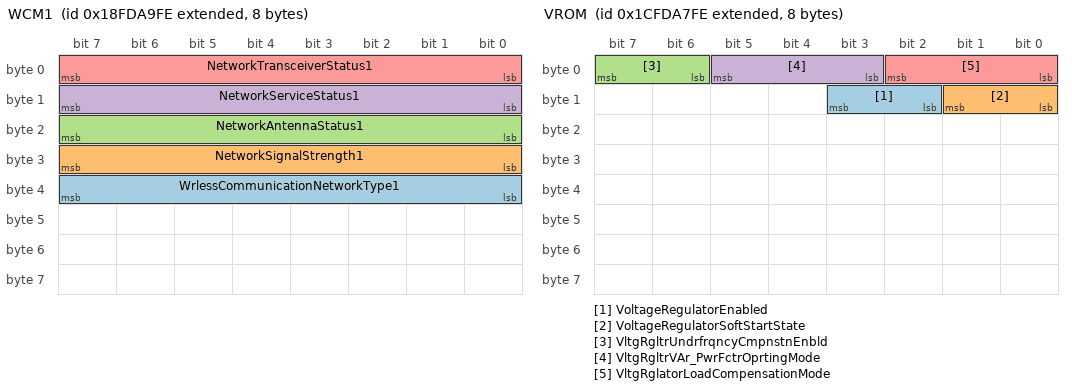
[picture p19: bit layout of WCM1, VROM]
BO_ 2566760958 WCM1: 8 Vector__XXX
 SG_ WrlessCommunicationNetworkType1 : 32|8@1+ (1,0) [0|255] "" Vector__XXX
 SG_ NetworkSignalStrength1 : 24|8@1+ (0.4,0) [0|100] "%" Vector__XXX
 SG_ NetworkAntennaStatus1 : 16|8@1+ (1,0) [0|255] "" Vector__XXX
 SG_ NetworkServiceStatus1 : 8|8@1+ (1,0) [0|255] "" Vector__XXX
 SG_ NetworkTransceiverStatus1 : 0|8@1+ (1,0) [0|255] "" Vector__XXX

BO_ 2633869310 VROM: 8 Vector__XXX
 SG_ VoltageRegulatorEnabled : 10|2@1+ (1,0) [0|3] "" Vector__XXX
 SG_ VoltageRegulatorSoftStartState : 8|2@1+ (1,0) [0|3] "" Vector__XXX
 SG_ VltgRgltrUndrfrqncyCmpnstnEnbld : 6|2@1+ (1,0) [0|3] "" Vector__XXX
 SG_ VltgRgltrVAr_PwrFctrOprtingMode : 3|3@1+ (1,0) [0|7] "" Vector__XXX
 SG_ VltgRglatorLoadCompensationMode : 0|3@1+ (1,0) [0|7] "" Vector__XXX

BO_ 2365433598 VREP: 8 Vector__XXX
 SG_ GnrtrOtputVoltageBiasPercentage : 32|16@1+ (0.1,-100) [-100|100] "%" Vector__XXX
 SG_ GeneratorExcitationFieldCurrent : 16|16@1+ (0.05,0) [0|3217.5] "A" Vector__XXX
 SG_ GeneratorExcitationFieldVoltage : 0|16@1+ (0.05,-1605.625) [-1605.625|1606.375] "V" Vector__XXX

CM_ BO_ 2566764542 "Expanded freeze frame.";
CM_ SG_ 2566764542 OccurenceCount1 "The 7 bit occurence count field contains the number of times a fault has gone from active to previously active.";
CM_ SG_ 2566764542 FailureModeIdentifier1 "The FMI defines the type of failure detected in the subsystem identified by an SPN.";
CM_ SG_ 2566764542 SPN1 "SPN #1 (Conversion Version 4)";
CM_ SG_ 2566764542 ExpandedFreezeFrameLength "The freeze frame length shall be equal to the number of bytes in the required parameters plus the number of bytes in the
manufacturer specific parameters.";
CM_ SG_ 2566764542 SPN1High "SPN #1 (Conversion Version 4)";
CM_ BO_ 2566764286 "SPN Support. This message is used to identify those SPNs supported by the product for freeze frames and data stream messages.";
CM_ SG_ 2566764286 SPNSupported1High "This parameter defines the SPN(s) that is/are supported for the freeze frame and/or data stream information.";
CM_ SG_ 2566764286 SPNSupportTypeSTR3 "This parameter defines whether the applicable parameter (that is the SPN) is supported in the freeze frame, the data stream or both the freeze frame and data stream.";
CM_ SG_ 2566764286 SPNSupportTypeSTR2 "This parameter defines whether the applicable parameter (that is the SPN) is supported in the freeze frame, the data stream or both the freeze frame and data stream.";
CM_ SG_ 2566764286 SPNSupportTypeEFF3 "This parameter defines whether the applicable parameter (that is the SPN) is supported in the freeze frame, the data stream or both the freeze frame and data stream.";
CM_ SG_ 2566764286 SPNSupportTypeEFF2 "This parameter defines whether the applicable parameter (that is the SPN) is supported in the freeze frame, the data stream or both the freeze frame and data stream.";
CM_ SG_ 2566764286 SPNSupportTypeDS3 "This parameter defines whether the applicable parameter (that is the SPN) is supported in the freeze frame, the data stream or both the freeze frame and data stream.";
CM_ SG_ 2566764286 SPNSupportTypeDS2 "This parameter defines whether the applicable parameter (that is the SPN) is supported in the freeze frame, the data stream or both the freeze frame and data stream.";
CM_ SG_ 2566764286 SPNSupported3High "This parameter defines the SPN(s) that is/are supported for the freeze frame and/or data stream information.";
CM_ SG_ 2566764286 SPNSupported2High "This parameter defines the SPN(s) that is/are supported for the freeze frame and/or data stream information.";
CM_ SG_ 2566764286 SPNSupported3 "This parameter defines the SPN(s) that is/are supported for the freeze frame and/or data stream information.";
CM_ SG_ 2566764286 SPNSupported2 "This parameter defines the SPN(s) that is/are supported for the freeze frame and/or data stream information.";
CM_ SG_ 2566764286 SPNDataLength3 "The number of data bytes associated with the SPN in the Freeze Frame.";
CM_ SG_ 2566764286 SPNSupportTypeSTR1 "This parameter defines whether the applicable parameter (that is the SPN) is supported in the freeze frame, the data stream or both the freeze frame and data stream.";
CM_ SG_ 2566764286 SPNSupportTypeDS1 "This parameter defines whether the applicable parameter (that is the SPN) is supported in the freeze frame, the data stream or both the freeze frame and data stream.";
CM_ SG_ 2566764286 SPNSupportTypeEFF1 "This parameter defines whether the applicable parameter (that is the SPN) is supported in the freeze frame, the data stream or both the freeze frame and data stream.";
CM_ SG_ 2566764286 SPNDataLength2 "The number of data bytes associated with the SPN in the Freeze Frame.";
CM_ SG_ 2566764286 SPNDataLength1 "The number of data bytes associated with the SPN in the Freeze Frame.";
CM_ SG_ 2566764286 SPNSupported1 "This parameter defines the SPN(s) that is/are supported for the freeze frame and/or data stream information.";
CM_ BO_ 2555576062 "Previously active emission related faults.";
CM_ SG_ 2555576062 FlashRedStopLamp "This parameter provides the capability to flash the RSL (SPN 3039).";
CM_ SG_ 2555576062 FlashProtectLamp "This parameter provides the capability to flash the engine protect lamp (SPN 3041).";
CM_ SG_ 2555576062 FlashMalfuncIndicatorLamp "This parameter provides the capability to flash the MIL (SPN 3038).";
CM_ SG_ 2555576062 SPN5 "SPN #5 (Conversion Version 4)";
CM_ SG_ 2555576062 SPN4 "SPN #4 (Conversion Version 4)";
CM_ SG_ 2555576062 SPN3 "SPN #3 (Conversion Version 4)";
CM_ SG_ 2555576062 SPN2 "SPN #2 (Conversion Version 4)";
CM_ SG_ 2555576062 FlashAmberWarningLamp "This parameter provides the capability to flash the AWL (SPN 3040). ";
CM_ SG_ 2555576062 FailureModeIdentifier5 "The FMI defines the type of failure detected in the subsystem identified by an SPN.";
CM_ SG_ 2555576062 FailureModeIdentifier4 "The FMI defines the type of failure detected in the subsystem identified by an SPN.";
CM_ SG_ 2555576062 OccurenceCount1 "The 7 bit occurence count field contains the number of times a fault has gone from active to previously active.";
CM_ SG_ 2555576062 FailureModeIdentifier1 "The FMI defines the type of failure detected in the subsystem identified by an SPN.";
CM_ SG_ 2555576062 SPN1 "SPN #1 (Conversion Version 4)";
CM_ SG_ 2555576062 MalfunctionIndicatorLampStatus "A lamp used to relay only emissions-related trouble code information.";
CM_ SG_ 2555576062 RedStopLampState "This lamp is uesed to relay trouble code information that is of a severe enought condition that it warrants stopping the vehicle.";
CM_ SG_ 2555576062 AmberWarningLampStatus "This lamp is used to relay trouble code information that is reporting a problem with the vehicle system but the vehicle need
not be immediately stopped.";
CM_ SG_ 2555576062 ProtectLampStatus "This lamp is used to relay trouble code informatio that is reporting a problem with a vehicle system that is most
probably not electronic subsystem related.";
CM_ SG_ 2555576062 FailureModeIdentifier3 "The FMI defines the type of failure detected in the subsystem identified by an SPN.";
CM_ SG_ 2555576062 FailureModeIdentifier2 "The FMI defines the type of failure detected in the subsystem identified by an SPN.";
CM_ SG_ 2555576062 OccurenceCount5 "The 7 bit occurence count field contains the number of times a fault has gone from active to previously active.";
CM_ SG_ 2555576062 OccurenceCount4 "The 7 bit occurence count field contains the number of times a fault has gone from active to previously active.";
CM_ SG_ 2555576062 OccurenceCount3 "The 7 bit occurence count field contains the number of times a fault has gone from active to previously active.";
CM_ SG_ 2555576062 OccurenceCount2 "The 7 bit occurence count field contains the number of times a fault has gone from active to previously active.";
CM_ SG_ 2555576062 SPN5High "SPN #5 (Conversion Version 4)";
CM_ SG_ 2555576062 SPN4High "SPN #4 (Conversion Version 4)";
CM_ SG_ 2555576062 SPN3High "SPN #3 (Conversion Version 4)";
CM_ SG_ 2555576062 SPN2High "SPN #2 (Conversion Version 4)";
CM_ SG_ 2555576062 SPN1High "SPN #1 (Conversion Version 4)";
CM_ BO_ 2562981630 "Individual Clear/Reset of active and previously active DTC.";
CM_ SG_ 2562981630 SPN1 "SPN #1 (Conversion Version 4)";
CM_ SG_ 2562981630 SPN1High "SPN #1 (Conversion Version 4)";
CM_ SG_ 2562981630 FailureModeIdentifier1 "The FMI defines the type of failure detected in the subsystem identified by an SPN.";
CM_ BO_ 2562850558 "Diagnostic readiness 2";
CM_ SG_ 2562850558 TimeSinceDTCsCleared "Time accumulated since DTCs were cleared (via an external test equipment or possibly, a battery disconnect) (SPN=?).";
CM_ SG_ 2562850558 MinutesRunByEngineMILActivated "Accumulated count (in minutes) while the MIL is activated (on) (SPN=?).";
CM_ SG_ 2562850558 DistanceSinceDTCsCleared "Distance accumulated since DTCs were cleared (SPN=?).";
CM_ SG_ 2562850558 DistanceWhileMILisActivated "The kilometers accumulated while the MIL is activated (SPN 3060).";
CM_ BO_ 2562916094 "Monitor Performance Ratio";
CM_ SG_ 2562916094 ApplSysMonitorDenominator "The number of times a vehicle has been operated that constitutes a driving cycle where this Applicable System Monitor could be operated per regulatory requirements (SPN 3068).";
CM_ SG_ 2562916094 ApplSysMonitorNumerator "The number of times a vehicle has been operated such that all conditions necessary for the Applicable System Monitor to detect a malfunction have been encountered (SPN 3067).";
CM_ SG_ 2562916094 SPNofApplSysMonitor "Contain the SPN of the system monitor for which Monitor ratio is being reported (SPN 3066).";
CM_ SG_ 2562916094 OBDMonitoringCondEncountered "Displays the number of times that the vehicle has been operated in the specified OBD monitoring conditions (SPN 3049).";
CM_ SG_ 2562916094 IgnitionCycleCounter "A single counter that defines the number of ignition cycles (SPN 3048).";
CM_ BO_ 2566835198 "Previously active diagnostic trouble codes";
CM_ SG_ 2566835198 SPN5 "SPN #5 (Conversion Version 4)";
CM_ SG_ 2566835198 SPN4 "SPN #4 (Conversion Version 4)";
CM_ SG_ 2566835198 SPN3 "SPN #3 (Conversion Version 4)";
CM_ SG_ 2566835198 SPN2 "SPN #2 (Conversion Version 4)";
CM_ SG_ 2566835198 FailureModeIdentifier5 "The FMI defines the type of failure detected in the subsystem identified by an SPN.";
CM_ SG_ 2566835198 FailureModeIdentifier4 "The FMI defines the type of failure detected in the subsystem identified by an SPN.";
CM_ SG_ 2566835198 OccurenceCount1 "The 7 bit occurence count field contains the number of times a fault has gone from active to previously active.";
CM_ SG_ 2566835198 FailureModeIdentifier1 "The FMI defines the type of failure detected in the subsystem identified by an SPN.";
CM_ SG_ 2566835198 SPN1 "SPN #1 (Conversion Version 4)";
CM_ SG_ 2566835198 MalfunctionIndicatorLampStatus "A lamp used to relay only emissions-related trouble code information.";
CM_ SG_ 2566835198 RedStopLampState "This lamp is uesed to relay trouble code information that is of a severe enought condition that it warrants stopping the vehicle.";
CM_ SG_ 2566835198 AmberWarningLampStatus "This lamp is used to relay trouble code information that is reporting a problem with the vehicle system but the vehicle need
not be immediately stopped.";
CM_ SG_ 2566835198 ProtectLampStatus "This lamp is used to relay trouble code informatio that is reporting a problem with a vehicle system that is most
probably not electronic subsystem related.";
CM_ SG_ 2566835198 FailureModeIdentifier3 "The FMI defines the type of failure detected in the subsystem identified by an SPN.";
CM_ SG_ 2566835198 FlashRedStopLamp "This parameter provides the capability to flash the RSL (SPN 3039).";
CM_ SG_ 2566835198 FlashProtectLamp "This parameter provides the capability to flash the engine protect lamp (SPN 3041).";
CM_ SG_ 2566835198 FlashMalfuncIndicatorLamp "This parameter provides the capability to flash the MIL (SPN 3038).";
CM_ SG_ 2566835198 FlashAmberWarningLamp "This parameter provides the capability to flash the AWL (SPN 3040). ";
CM_ SG_ 2566835198 FailureModeIdentifier2 "The FMI defines the type of failure detected in the subsystem identified by an SPN.";
CM_ SG_ 2566835198 OccurenceCount5 "The 7 bit occurence count field contains the number of times a fault has gone from active to previously active.";
CM_ SG_ 2566835198 OccurenceCount4 "The 7 bit occurence count field contains the number of times a fault has gone from active to previously active.";
CM_ SG_ 2566835198 OccurenceCount3 "The 7 bit occurence count field contains the number of times a fault has gone from active to previously active.";
CM_ SG_ 2566835198 OccurenceCount2 "The 7 bit occurence count field contains the number of times a fault has gone from active to previously active.";
CM_ SG_ 2566835198 SPN5High "SPN #5 (Conversion Version 4)";
CM_ SG_ 2566835198 SPN4High "SPN #4 (Conversion Version 4)";
CM_ SG_ 2566835198 SPN3High "SPN #3 (Conversion Version 4)";
CM_ SG_ 2566835198 SPN2High "SPN #2 (Conversion Version 4)";
CM_ SG_ 2566835198 SPN1High "SPN #1 (Conversion Version 4)";
CM_ BO_ 2564030206 "Calibration Information";
CM_ BO_ 2564226814 "Boot Load Data";
CM_ BO_ 2564292350 "Binary Data Transfer";
CM_ SG_ 2564292350 NumberOfOccurance "Number of occurance of raw binary data";
CM_ BO_ 2564357886 "Memory Access Response";
CM_ SG_ 2564357886 ErrorIndicator "Error Indicator/EDC Parameter";
CM_ BO_ 2564423422 "Memory Access Request";
CM_ SG_ 2564423422 KeyOrUserLevel "Key/User Level";
CM_ SG_ 2564423422 NumberRequested "Length/Number Requested";
CM_ SG_ 2564423422 NumberRequestedHigh "Length/Number Requested";
CM_ BO_ 2564816638 "Stop start broadcast";
CM_ SG_ 2564816638 HoldSignal "Indicator to all nodes that the communication ports that have been acted upon by the 'Stop start broadcast'
PGN are remaining in the modified state.";
CM_ SG_ 2564816638 J1939Network3 "Identifies the action to be performed on the SAE J1939 Network #3.";
CM_ SG_ 2564816638 J1939Network2 "Identifies the action to be performed on the SAE J1939 Network #2.";
CM_ SG_ 2564816638 ISO9141 "Identifies the action to be performed on the ISO9141 communications port.";
CM_ SG_ 2564816638 SAE_J1850 "Identifies the action to be performed on the SAE J1850 communications port.";
CM_ SG_ 2564816638 ManufacturerSpecificPort "Identifies the action to be performed on 'Other, manufacturer specific port' communications port.";
CM_ SG_ 2564816638 CurrentDataLink "Identifies the action to be performed on the communications port that this parameter was received.";
CM_ SG_ 2564816638 SAE_J1587 "Identifies the action to be performed on the SAE J1587 communications port.";
CM_ SG_ 2564816638 SAE_J1922 "Identifies the action to be performed on the SAE J1922 communications port.";
CM_ SG_ 2564816638 J1939Network1 "Identifies the action to be performed on the SAE J1939 Network #1, Primary vehicle communications port.";
CM_ BO_ 2566837502 "Emissions-related active diagnostic trouble codes.";
CM_ SG_ 2566837502 SPN5 "SPN #5 (Conversion Version 4)";
CM_ SG_ 2566837502 SPN4 "SPN #4 (Conversion Version 4)";
CM_ SG_ 2566837502 SPN3 "SPN #3 (Conversion Version 4)";
CM_ SG_ 2566837502 SPN2 "SPN #2 (Conversion Version 4)";
CM_ SG_ 2566837502 FlashRedStopLamp "This parameter provides the capability to flash the RSL (SPN 3039).";
CM_ SG_ 2566837502 FlashProtectLamp "This parameter provides the capability to flash the engine protect lamp (SPN 3041).";
CM_ SG_ 2566837502 FailureModeIdentifier5 "The FMI defines the type of failure detected in the subsystem identified by an SPN.";
CM_ SG_ 2566837502 FailureModeIdentifier4 "The FMI defines the type of failure detected in the subsystem identified by an SPN.";
CM_ SG_ 2566837502 FailureModeIdentifier3 "The FMI defines the type of failure detected in the subsystem identified by an SPN.";
CM_ SG_ 2566837502 OccurenceCount1 "The 7 bit occurence count field contains the number of times a fault has gone from active to previously active.";
CM_ SG_ 2566837502 FailureModeIdentifier1 "The FMI defines the type of failure detected in the subsystem identified by an SPN.";
CM_ SG_ 2566837502 SPN1 "SPN #1 (Conversion Version 4)";
CM_ SG_ 2566837502 MalfunctionIndicatorLampStatus "A lamp used to relay only emissions-related trouble code information.";
CM_ SG_ 2566837502 RedStopLampState "This lamp is uesed to relay trouble code information that is of a severe enought condition that it warrants stopping the vehicle.";
CM_ SG_ 2566837502 AmberWarningLampStatus "This lamp is used to relay trouble code information that is reporting a problem with the vehicle system but the vehicle need
not be immediately stopped.";
CM_ SG_ 2566837502 ProtectLampStatus "This lamp is used to relay trouble code informatio that is reporting a problem with a vehicle system that is most
probably not electronic subsystem related.";
CM_ SG_ 2566837502 FlashMalfuncIndicatorLamp "This parameter provides the capability to flash the MIL (SPN 3038).";
CM_ SG_ 2566837502 FlashAmberWarningLamp "This parameter provides the capability to flash the AWL (SPN 3040). ";
CM_ SG_ 2566837502 FailureModeIdentifier2 "The FMI defines the type of failure detected in the subsystem identified by an SPN.";
CM_ SG_ 2566837502 OccurenceCount5 "The 7 bit occurence count field contains the number of times a fault has gone from active to previously active.";
CM_ SG_ 2566837502 OccurenceCount4 "The 7 bit occurence count field contains the number of times a fault has gone from active to previously active.";
CM_ SG_ 2566837502 OccurenceCount3 "The 7 bit occurence count field contains the number of times a fault has gone from active to previously active.";
CM_ SG_ 2566837502 OccurenceCount2 "The 7 bit occurence count field contains the number of times a fault has gone from active to previously active.";
CM_ SG_ 2566837502 SPN5High "SPN #5 (Conversion Version 4)";
CM_ SG_ 2566837502 SPN4High "SPN #4 (Conversion Version 4)";
CM_ SG_ 2566837502 SPN3High "SPN #3 (Conversion Version 4)";
CM_ SG_ 2566837502 SPN2High "SPN #2 (Conversion Version 4)";
CM_ SG_ 2566837502 SPN1High "SPN #1 (Conversion Version 4)";
CM_ BO_ 2566837246 "Diagnostic data clear/Reset for active DTCs";
CM_ BO_ 2566836990 "Non-continously monitored systems test identifiers support";
CM_ SG_ 2566836990 TestIdentifierSupported "Indicates the test identifiers that the controller supports.";
CM_ BO_ 2566834942 "Active diagnostic trouble codes";
CM_ SG_ 2566834942 SPN5 "SPN #5 (Conversion Version 4)";
CM_ SG_ 2566834942 SPN4 "SPN #4 (Conversion Version 4)";
CM_ SG_ 2566834942 SPN3 "SPN #3 (Conversion Version 4)";
CM_ SG_ 2566834942 SPN2 "SPN #2 (Conversion Version 4)";
CM_ SG_ 2566834942 FailureModeIdentifier5 "The FMI defines the type of failure detected in the subsystem identified by an SPN.";
CM_ SG_ 2566834942 FailureModeIdentifier4 "The FMI defines the type of failure detected in the subsystem identified by an SPN.";
CM_ SG_ 2566834942 FailureModeIdentifier3 "The FMI defines the type of failure detected in the subsystem identified by an SPN.";
CM_ SG_ 2566834942 FlashRedStopLamp "This parameter provides the capability to flash the RSL (SPN 3039).";
CM_ SG_ 2566834942 FlashProtectLamp "This parameter provides the capability to flash the engine protect lamp (SPN 3041).";
CM_ SG_ 2566834942 FlashMalfuncIndicatorLamp "This parameter provides the capability to flash the MIL (SPN 3038).";
CM_ SG_ 2566834942 FlashAmberWarningLamp "This parameter provides the capability to flash the AWL (SPN 3040). ";
CM_ SG_ 2566834942 MalfunctionIndicatorLampStatus "A lamp used to relay only emissions-related trouble code information.";
CM_ SG_ 2566834942 AmberWarningLampStatus "This lamp is used to relay trouble code information that is reporting a problem with the vehicle system but the vehicle need
not be immediately stopped.";
CM_ SG_ 2566834942 OccurenceCount1 "The 7 bit occurence count field contains the number of times a fault has gone from active to previously active.";
CM_ SG_ 2566834942 FailureModeIdentifier1 "The FMI defines the type of failure detected in the subsystem identified by an SPN.";
CM_ SG_ 2566834942 SPN1 "SPN #1 (Conversion Version 4)";
CM_ SG_ 2566834942 RedStopLampState "This lamp is uesed to relay trouble code information that is of a severe enought condition that it warrants stopping the vehicle.";
CM_ SG_ 2566834942 ProtectLampStatus "This lamp is used to relay trouble code informatio that is reporting a problem with a vehicle system that is most
probably not electronic subsystem related.";
CM_ SG_ 2566834942 FailureModeIdentifier2 "The FMI defines the type of failure detected in the subsystem identified by an SPN.";
CM_ SG_ 2566834942 OccurenceCount5 "The 7 bit occurence count field contains the number of times a fault has gone from active to previously active.";
CM_ SG_ 2566834942 OccurenceCount4 "The 7 bit occurence count field contains the number of times a fault has gone from active to previously active.";
CM_ SG_ 2566834942 OccurenceCount3 "The 7 bit occurence count field contains the number of times a fault has gone from active to previously active.";
CM_ SG_ 2566834942 OccurenceCount2 "The 7 bit occurence count field contains the number of times a fault has gone from active to previously active.";
CM_ SG_ 2566834942 SPN5High "SPN #5 (Conversion Version 4)";
CM_ SG_ 2566834942 SPN4High "SPN #4 (Conversion Version 4)";
CM_ SG_ 2566834942 SPN3High "SPN #3 (Conversion Version 4)";
CM_ SG_ 2566834942 SPN2High "SPN #2 (Conversion Version 4)";
CM_ SG_ 2566834942 SPN1High "SPN #1 (Conversion Version 4)";
CM_ BO_ 2566780926 "Utility Total AC Reactive Power";
CM_ SG_ 2566780926 UtlityOverallPowerFactorLagging "Lead/lag status for utility incomer average power factor.";
CM_ SG_ 2566780926 UtilityOverallPowerFactor "The average power factor of the utility incomer.";
CM_ SG_ 2566780926 UtilityTotalReactivePower "The total reactive power delivered by the utility incomer";
CM_ BO_ 2566781182 "Utility Total AC Power";
CM_ SG_ 2566781182 UtilityTotalApparentPower "The total apparent power delivered by the utility incomer.";
CM_ SG_ 2566781182 UtilityTotalRealPower "Total real power delivered by the utility incomer.";
CM_ BO_ 2566778366 "Utility Total AC Energy";
CM_ SG_ 2566778366 UtilityTotalKWHoursImport "The total kilowatt-hours that have been imported by the utility incomer.";
CM_ SG_ 2566778366 UtilityTotalKWHoursExport "The total kilowatt-hours that have been exported by the utility incomer.";
CM_ BO_ 2566778622 "Utility Phase C AC Reactive Power";
CM_ SG_ 2566778622 UtilityPhaseCPowerFactorLagging "Lead/lag status for utility incomer phase C power factor.";
CM_ SG_ 2566778622 UtilityPhaseCPowerFactor "The power factor of phases C of the utility incomer.";
CM_ SG_ 2566778622 UtilityPhaseCReactivePower "The reactive power delivered by phase C of the utility incomer";
CM_ BO_ 2566778878 "Utility Phase C AC Power";
CM_ SG_ 2566778878 UtilityPhaseCApparentPower "The apparent power delivered by phase C of the utility incomer.";
CM_ SG_ 2566778878 UtilityPhaseCRealPower "The real power delivered by phase C of the utility incomer.";
CM_ BO_ 2566779134 "Utility Phase C AC Basic Quantities";
CM_ SG_ 2566779134 UtilityPhaseCACRMSCurrent "RMS current measured at the utility incomer phase C.";
CM_ SG_ 2566779134 UtilityPhaseCACFrequency "AC frequency measured at the utility incomer phase C.";
CM_ SG_ 2566779134 UtltyPhsCLneNeutralACRMSVoltage "Line to Neutral RMS voltage measured at the utility incomer phase C.";
CM_ SG_ 2566779134 UtltyPhseCALineLineACRMSVoltage "Line to Line RMS voltage measured at the utility incomer phase CA.";
CM_ BO_ 2566779390 "Utility Phase B AC Reactive Power";
CM_ SG_ 2566779390 UtilityPhaseBPowerFactorLagging "Lead/lag status for utility incomer phase B power factor.";
CM_ SG_ 2566779390 UtilityPhaseBPowerFactor "The power factor of phases B of the utility incomer.";
CM_ SG_ 2566779390 UtilityPhaseBReactivePower "The reactive power delivered by phase B of the utility incomer";
CM_ BO_ 2566779646 "Utility Phase B AC Power";
CM_ SG_ 2566779646 UtilityPhaseBApparentPower "The apparent power delivered by phase B of the utility incomer.";
CM_ SG_ 2566779646 UtilityPhaseBRealPower "The real power delivered by phase B of the utility incomer.";
CM_ BO_ 2566779902 "Utility Phase B AC Basic Quantities";
CM_ SG_ 2566779902 UtilityPhaseBACRMSCurrent "RMS current measured at the utility incomer phase B.";
CM_ SG_ 2566779902 UtilityPhaseBACFrequency "AC frequency measured at the utility incomer phase B.";
CM_ SG_ 2566779902 UtltyPhsBLneNeutralACRMSVoltage "Line to Neutral RMS voltage measured at the utility incomer phase B.";
CM_ SG_ 2566779902 UtltyPhseBCLineLineACRMSVoltage "Line to Line RMS voltage measured at the utility incomer phase BC.";
CM_ BO_ 2566780158 "Utility Phase A  AC Reactive Power";
CM_ SG_ 2566780158 UtilityPhaseAPowerFactorLagging "Lead/lag status for utility incomer phase A power factor.";
CM_ SG_ 2566780158 UtilityPhaseAPowerFactor "The power factor of phase A of the utility incomer.";
CM_ SG_ 2566780158 UtilityPhaseAReactivePower "The reactive power delivered by phase A of the utility incomer";
CM_ BO_ 2566780414 "Utility Phase A  AC Power";
CM_ SG_ 2566780414 UtilityPhaseAApparentPower "The apparent power delivered by phase A of the utility incomer.";
CM_ SG_ 2566780414 UtilityPhaseARealPower "The real power delivered by phase A of the utility incomer.";
CM_ BO_ 2566780670 "Utility Phase A Basic AC Quantities";
CM_ SG_ 2566780670 UtilityPhaseAACRMSCurrent "RMS current measured at the utility incomer phase A.";
CM_ SG_ 2566780670 UtilityPhaseAACFrequency "AC frequency measured at the utility incomer phase A.";
CM_ SG_ 2566780670 UtltyPhsALneNeutralACRMSVoltage "Line to Neutral RMS voltage measured at the utility incomer phase A.";
CM_ SG_ 2566780670 UtltyPhseABLineLineACRMSVoltage "Line to Line RMS voltage measured at the utility incomer phase AB.";
CM_ BO_ 2566781438 "Utility Average Basic AC Quantities";
CM_ SG_ 2566781438 UtilityAverageACRMSCurrent "Average RMS current measured at the utility incomer.";
CM_ SG_ 2566781438 UtilityAverageACFrequency "Average AC frequency measured at the utility incomer.";
CM_ SG_ 2566781438 UtltyAvrgLneNeutralACRMSVoltage "The average Line to Neutral AC RMS voltage measured at the utility incomer .";
CM_ SG_ 2566781438 UtltyAvrageLineLineACRMSVoltage "Average Line to Line RMS voltage measured at the utility incomer .";
CM_ BO_ 2566784254 "Generator Total AC Reactive Power";
CM_ SG_ 2566784254 GnrtorOverallPowerFactorLagging "Lead/lag status for generator average power factor.";
CM_ SG_ 2566784254 GeneratorOverallPowerFactor "The average power factor of the generator.";
CM_ SG_ 2566784254 GeneratorTotalReactivePower "The total reactive power delivered by the generator";
CM_ BO_ 2566784510 "Generator Total AC Power";
CM_ SG_ 2566784510 GeneratorTotalApparentPower "The total apparent power delivered by the generator.";
CM_ SG_ 2566784510 GeneratorTotalRealPower "Total real power delivered by the generator.";
CM_ BO_ 2566781694 "Generator Total AC Energy";
CM_ SG_ 2566781694 GeneratorTotalKWHoursImport "The total kilowatt-hours that have been imported by the generator.";
CM_ SG_ 2566781694 GeneratorTotalKWHoursExport "The total kilowatt-hours that have been exported by the generator.";
CM_ BO_ 2566781950 "Generator Phase C AC Reactive Power";
CM_ SG_ 2566781950 GnratorPhaseCPowerFactorLagging "Lead/lag status for generator phase C power factor.";
CM_ SG_ 2566781950 GeneratorPhaseCPowerFactor "The power factor of phases C of the generator.";
CM_ SG_ 2566781950 GeneratorPhaseCReactivePower "The reactive power delivered by phase C of the generator";
CM_ BO_ 2566782206 "Generator Phase C AC Power";
CM_ SG_ 2566782206 GeneratorPhaseCApparentPower "The apparent power delivered by phase C of the generator.";
CM_ SG_ 2566782206 GeneratorPhaseCRealPower "The real power delivered by phase C of the generator.";
CM_ BO_ 2566782462 "Generator Phase C Basic AC Quantities";
CM_ SG_ 2566782462 GeneratorPhaseCACRMSCurrent "RMS current measured at the generator phase C output.";
CM_ SG_ 2566782462 GeneratorPhaseCACFrequency "AC frequency measured at the generator phase C output.";
CM_ SG_ 2566782462 GnrtrPhsCLneNeutralACRMSVoltage "Line to Neutral RMS voltage measured at the generator phase C output.";
CM_ SG_ 2566782462 GnrtrPhseCALineLineACRMSVoltage "Line to Line RMS voltage measured at the generator phase CA output.";
CM_ BO_ 2566782718 "Generator Phase B AC Reactive Power";
CM_ SG_ 2566782718 GnratorPhaseBPowerFactorLagging "Lead/lag status for generator phase B power factor.";
CM_ SG_ 2566782718 GeneratorPhaseBPowerFactor "The power factor of phases B of the generator.";
CM_ SG_ 2566782718 GeneratorPhaseBReactivePower "The reactive power delivered by phase B of the generator";
CM_ BO_ 2566782974 "Generator Phase B AC Power";
CM_ SG_ 2566782974 GeneratorPhaseBApparentPower "The apparent power delivered by phase B of the generator.";
CM_ SG_ 2566782974 GeneratorPhaseBRealPower "The real power delivered by phase B of the generator.";
CM_ BO_ 2566783230 "Generator Phase B Basic AC Quantities";
CM_ SG_ 2566783230 GeneratorPhaseBACRMSCurrent "RMS current measured at the generator phase B output.";
CM_ SG_ 2566783230 GeneratorPhaseBACFrequency "AC frequency measured at the generator phase B output.";
CM_ SG_ 2566783230 GnrtrPhsBLneNeutralACRMSVoltage "Line to Neutral RMS voltage measured at the generator phase B output.";
CM_ SG_ 2566783230 GnrtrPhseBCLineLineACRMSVoltage "Line to Line RMS voltage measured at the generator phase BC output.";
CM_ BO_ 2566783486 "Generator Phase A AC Reactive Power";
CM_ SG_ 2566783486 GnratorPhaseAPowerFactorLagging "Lead/lag status for generator phase A power factor.";
CM_ SG_ 2566783486 GeneratorPhaseAPowerFactor "The power factor of phase A of the generator.";
CM_ SG_ 2566783486 GeneratorPhaseAReactivePower "The reactive power delivered by phase A of the generator";
CM_ BO_ 2566783742 "Generator Phase A AC Power";
CM_ SG_ 2566783742 GeneratorPhaseAApparentPower "The apparent power delivered by phase A of the generator.";
CM_ SG_ 2566783742 GeneratorPhaseARealPower "The real power delivered by phase A of the generator.";
CM_ BO_ 2566783998 "Generator Phase A Basic AC Quantities";
CM_ SG_ 2566783998 GeneratorPhaseAACRMSCurrent "RMS current measured at the generator phase A output.";
CM_ SG_ 2566783998 GeneratorPhaseAACFrequency "AC frequency measured at the generator phase A output.";
CM_ SG_ 2566783998 GnrtrPhsALneNeutralACRMSVoltage "Line to Neutral RMS voltage measured at the generator phase A output.";
CM_ SG_ 2566783998 GnrtrPhseABLineLineACRMSVoltage "Line to Line RMS voltage measured at the generator phase AB output.";
CM_ BO_ 2566784766 "Generator Average Basic AC Quantities";
CM_ SG_ 2566784766 GeneratorAverageACRMSCurrent "Average RMS current measured at the generator output.";
CM_ SG_ 2566784766 GeneratorAverageACFrequency "Average AC frequency measured at the generator output.";
CM_ SG_ 2566784766 GnrtrAvrgLneNeutralACRMSVoltage "The average Line to Neutral AC RMS voltage measured at the Generator output.";
CM_ SG_ 2566784766 GnrtrAvrageLineLineACRMSVoltage "Average Line to Line RMS voltage measured at the generator output.";
CM_ BO_ 2566776830 "Bus #1/Utility Sync Check Status";
CM_ SG_ 2566776830 Bus1_UtilityACPhaseDifference "The phase difference between the Bus #1 voltage and Utility voltage.";
CM_ SG_ 2566776830 Bus1_UtilityInSync "Indicator of whether Bus #1 and Utility are properly synchronized for paralleling. This indicator will be based on parameters such as Voltage Match, Frequency Match, and Phase Match.";
CM_ SG_ 2566776830 Bus1_UtilityVoltageMatch "Indicator of whether voltage difference between Bus #1 and Utility is adequate for paralleling. This indicator will be based on the measured AC voltages qualified using parameters such as Voltage Tolerance.";
CM_ SG_ 2566776830 Bus1_UtilityFrequencyMatch "Indicator of whether frequency difference between Bus #1 and Utility is adequate for paralleling. This indicator will be based on the measured AC frequencies qualified using parameters such as Frequency Tolerance, Phase Tolerance, and Dwell Time.";
CM_ SG_ 2566776830 Bus1_UtilityPhaseMatch "Indicator of whether phase difference between Bus #1 and Utility is adequate for paralleling. This indicator will be based on the measured AC phase difference qualified using parameters such as Phase Tolerance and Dwell Time.";
CM_ SG_ 2566776830 Bus1_UtilityDeadBus "Indicator of whether Bus #1 is considered dead for closing to the utility. This indicator will be based on parameters such as Bus #1 Voltage and dead bus threshold values.";
CM_ BO_ 2566777342 "Bus #1 Phase C  Basic AC Quantities";
CM_ SG_ 2566777342 Bus1PhaseCACFrequency "AC frequency measured at bus #1 phase C.";
CM_ SG_ 2566777342 Bs1PhseCLineNeutralACRMSVoltage "Line to Neutral RMS voltage measured at bus #1 phase C.";
CM_ SG_ 2566777342 Bus1PhaseCALineLineACRMSVoltage "Line to Line RMS voltage measured at bus #1 phase CA.";
CM_ BO_ 2566777598 "Bus #1 Phase B  Basic AC Quantities";
CM_ SG_ 2566777598 Bus1PhaseBACFrequency "AC frequency measured at bus #1 phase B.";
CM_ SG_ 2566777598 Bs1PhseBLineNeutralACRMSVoltage "Line to Neutral RMS voltage measured at bus #1 phase B.";
CM_ SG_ 2566777598 Bus1PhaseBCLineLineACRMSVoltage "Line to Line RMS voltage measured at bus #1 phase BC.";
CM_ BO_ 2566777854 "Bus #1 Phase A  Basic AC Quantities";
CM_ SG_ 2566777854 Bus1PhaseAACFrequency "AC frequency measured at bus #1 phase A.";
CM_ SG_ 2566777854 Bs1PhseALineNeutralACRMSVoltage "Line to Neutral RMS voltage measured at bus #1 phase A.";
CM_ SG_ 2566777854 Bus1PhaseABLineLineACRMSVoltage "Line to Line RMS voltage measured at bus #1 phase AB.";
CM_ BO_ 2566777086 "Bus #1/Generator Sync Check Status";
CM_ SG_ 2566777086 Bus1_GeneratorACPhaseDifference "The phase difference between the Bus #1 voltage and Generator voltage.";
CM_ SG_ 2566777086 Bus1_GeneratorInSync "Indicator of whether Bus #1 and Generator are properly synchronized for paralleling. This indicator will be based on parameters such as Voltage Match, Frequency Match, and Phase Match.";
CM_ SG_ 2566777086 Bus1_GeneratorVoltageMatch "Indicator of whether voltage difference between Bus #1 and Generator is adequate for paralleling. This indicator will be based on the measured AC voltages qualified using parameters such as Voltage Tolerance.";
CM_ SG_ 2566777086 Bus1_GeneratorFrequencyMatch "Indicator of whether frequency difference between Bus #1 and Generator is adequate for paralleling. This indicator will be based on the measured AC frequencies qualified using parameters such as Frequency Tolerance, Phase Tolerance, and Dwell Time.";
CM_ SG_ 2566777086 Bus1_GeneratorPhaseMatch "Indicator of whether phase difference between Bus #1 and Generator is adequate for paralleling. This indicator will be based on the measured AC phase difference qualified using parameters such as Phase Tolerance and Dwell Time.";
CM_ SG_ 2566777086 Bus1_GeneratorDeadBus "Indicator of whether Bus #1 is considered dead for closing to the generator. This indicator will be based on parameters such as Bus #1 Voltage and dead bus threshold values.";
CM_ BO_ 2566778110 "Bus #1 Average Basic AC Quantities";
CM_ SG_ 2566778110 Bus1AverageACFrequency "Average AC frequency measured at bus #1.";
CM_ SG_ 2566778110 Bs1AvrgeLineNeutralACRMSVoltage "The average Line to Neutral AC RMS voltage measured at bus #1 .";
CM_ SG_ 2566778110 Bus1AverageLineLineACRMSVoltage "Average Line to Line RMS voltage measured at bus #1 .";
CM_ BO_ 2633895422 "Working Set Master";
CM_ BO_ 2566838526 "Commanded Address";
CM_ SG_ 2566838526 AddressAssignment "The source address that is to be assigned to the CA that has the NAME corresponding to the one conveyed in the first eight bytes of this Commanded Address message.";
CM_ BO_ 2565799678 "Address Claimed";
CM_ BO_ 2563440382 "Transfer";
CM_ SG_ 2563440382 ShrtNameOfActualReportingDevice "Short name of reporting device of the requested PGN via the Transfer PGN.";
CM_ SG_ 2563440382 LengthOfDataForTheReportedPGN "Length of data reported with the associated PGN via the Transfer PGN.";
CM_ SG_ 2563440382 PGNofRequstedInformation "PGN associated with this transfer message";
CM_ BO_ 2565603070 "Transport Protocol - Data Transfer";
CM_ BO_ 2565668606 "Transport Protocol - Connection Management";
CM_ SG_ 2565668606 TotalNumberOfPacketsEoMA "Total number of packets for BAM message.Total number of packets received for RTS/CTS message.Total number of packets for RTS/CTS message.";
CM_ SG_ 2565668606 TotalMessageSizeEoMA "Total message size (in bytes) for BAM message.Total message size (in bytes) for RTS/CTS message.Total message size (in bytes) for RTS/CTS message.";
CM_ SG_ 2565668606 TotalMessageSizeBAM "Total message size (in bytes) for BAM message.Total message size (in bytes) for RTS/CTS message.Total message size (in bytes) for RTS/CTS message.";
CM_ SG_ 2565668606 TotalNumberOfPacketsBAM "Total number of packets for BAM message.Total number of packets received for RTS/CTS message.Total number of packets for RTS/CTS message.";
CM_ SG_ 2565668606 ConnectionAbortReason "Reason for connection abort message.";
CM_ SG_ 2565668606 NextPacketNumberToBeSent "Next Packet Number to be sent (TP.CM_CTS)";
CM_ SG_ 2565668606 NumberOfPacketsThatCanBeSent "Number of Packets that can be sent (TP.CM_CTS)";
CM_ SG_ 2565668606 MaximumNumberOfPackets "Maximum number of packets for RTS/CTS message.";
CM_ SG_ 2565668606 TotalNumberOfPackets "Total number of packets for BAM message.Total number of packets received for RTS/CTS message.Total number of packets for RTS/CTS message.";
CM_ SG_ 2565668606 TotalMessageSize "Total message size (in bytes) for BAM message.Total message size (in bytes) for RTS/CTS message.Total message size (in bytes) for RTS/CTS message.";
CM_ BO_ 2563374846 "Request 2";
CM_ SG_ 2563374846 UseTransferMode "Requester is to respond via the Transfer PGN";
CM_ SG_ 2563374846 ParameterGroupNumber "PGN which is requested by Request2 message";
CM_ BO_ 2565537534 "Request";
CM_ SG_ 2565537534 ParameterGroupNumber "PGN which is requested by Request2 message";
CM_ BO_ 2566845950 "Ambient Conditions";
CM_ SG_ 2566845950 RoadSurfaceTemp "Indicated temperature of road surface over which vehicle is operating.";
CM_ SG_ 2566845950 EngAirInletTemp "Temperature of air entering vehicle air induction system.";
CM_ SG_ 2566845950 AmbientAirTemp "Temperature of air surrounding vehicle.";
CM_ SG_ 2566845950 CabInteriorTemp "Temperature of air inside the part of the vehicle that encloses the driver and vehicle operating controls.";
CM_ SG_ 2566845950 BarometricPress "Absolute air pressure of the atmosphere.";
CM_ BO_ 2566840062 "Air Start Pressure";
CM_ BO_ 2566827774 "Air Supply Pressure";
CM_ SG_ 2566827774 AirCompressorStatus "Indicates whether the air compressor is actively compressing air.";
CM_ SG_ 2566827774 AirSuspensionSupplyPress "The pneumatic pressure in the circuit for the electronically controlled air suspension system.";
CM_ SG_ 2566827774 AuxEquipmentSupplyPress "The pneumatic pressure in the auxiliary circuit.";
CM_ SG_ 2566827774 ServiceBrakeAirPressCircuit2 "The pneumatic pressure in the service brake circuit or reservoir #2.";
CM_ SG_ 2566827774 ServiceBrakeAirPressCircuit1 "The pneumatic pressure in the service brake circuit or reservoir #1.";
CM_ SG_ 2566827774 ParkingAnd_OrTrailerAirPress "The pneumatic pressure in the circuit or reservoir for the parking brake and/or the trailer supply.";
CM_ SG_ 2566827774 PneumaticSupplyPress "The pneumatic pressure in the main reservoir, sometimes referred to as the wet tank.";
CM_ BO_ 2566846974 "Axle Information";
CM_ SG_ 2566846974 SteerAxleLubePress "The steering axle lubricant pressure.";
CM_ SG_ 2566846974 SteerAxleTemp "Temperature of lubricant in steering axle.";
CM_ SG_ 2566846974 DriveAxleLubePress "The drive axle lubricant pressure with location determined by Drive Axle Location (SPN 930).";
CM_ SG_ 2566846974 DriveAxleTemp "Temperature of axle lubricant in drive axle.";
CM_ SG_ 2566846974 DriveAxleLiftAirPress "Gage pressure of air in system that utilizes compressed air to provide force between axle and frame.";
CM_ SG_ 2566846974 DriveAxleLocation "To identify to which of several similar devices (such as tires or fuel tanks) the information applies.";
CM_ BO_ 2633935614 "Alternate Fuel 2";
CM_ SG_ 2633935614 EngTurboWastegateValvePos "The position of the turbocharger wastegate valve (not the electronic wastegate control valve).";
CM_ SG_ 2633935614 EngDsiredAbsIntakeManifoldPress "The desired absolute intake manifold pressure of the engine.";
CM_ SG_ 2633935614 EngGasFuelCorrectionFactor "A correction to a predefined gaseous fuel energy (expressed in energy per unit volume) represented as a percentage.";
CM_ BO_ 2566803966 "Adaptive Cruise Control, Operator Input";
CM_ SG_ 2566803966 RqedACCDistanceMode "The Requested Distance Control Mode to the ACC system from the operators interface.";
CM_ BO_ 2432593918 "Adaptive Cruise Control";
CM_ SG_ 2432593918 ACCDistanceAlertSignal "Signal to indicate to the operator that the ACC system is not able to maintain the distance to the target.";
CM_ SG_ 2432593918 ACCSystemShutoffWarning "Signal to warn the driver of system deactivation due to non-driver actions.";
CM_ SG_ 2432593918 ACCTargetDetected "Signal to indicate to the driver that the ACC system has detected a target.";
CM_ SG_ 2432593918 RoadCurvature "Estimated value of the current road curvature for use by the adaptive cruise control system.";
CM_ SG_ 2432593918 AdptveCruiseCtrlSetDistanceMode "Selected distance mode for adaptive cruise control.";
CM_ SG_ 2432593918 AdaptiveCruiseCtrlMode "This parameter is used to indicate the current state, or mode, of operation by the Adaptive Cruise Control (ACC) device.";
CM_ SG_ 2432593918 AdaptiveCruiseCtrlSetSpeed "Value of the desired (chosen) velocity of the adaptive cruise control system.";
CM_ SG_ 2432593918 DistanceToForwardVehicle "Distance to the preceding vehicle situated within 250 m in the same lane and moving in the same direction.";
CM_ SG_ 2432593918 SpeedOfForwardVehicle "Absolute velocity of the preceding vehicle situated within 250 m in the same lane and moving in the same direction.";
CM_ BO_ 2633935102 "Articulation Control";
CM_ SG_ 2633935102 ArticulationAngle "Angle of deflection of an articulated transit vehicle.";
CM_ BO_ 2633927934 "Auxiliary Analog Information";
CM_ SG_ 2633927934 AuxLevel "Level measured by a sensor.";
CM_ SG_ 2633927934 AuxPress2 "Pressure measured by auxiliary pressure sensor #2.";
CM_ SG_ 2633927934 AuxPress1 "Pressure measured by auxiliary pressure sensor #1.";
CM_ SG_ 2633927934 AuxTemp2 "Temperature measured by auxiliary temperature sensor #2.";
CM_ SG_ 2633927934 AuxTemp1 "Temperature measured by auxiliary temperature sensor #1.";
CM_ BO_ 2566847998 "Alternate Fuel 1";
CM_ SG_ 2566847998 EngBlowerBypassValvePos "Relative position of the blower bypass valve.";
CM_ SG_ 2566847998 EngGasSupplyPress "Gage pressure of gas supply to fuel metering device.";
CM_ BO_ 2565406462 "Acknowledgment Message";
CM_ SG_ 2565406462 ParameterGroupNumber "PGN which is requested by Request2 message";
CM_ SG_ 2565406462 GroupFunctionValue "Indicates the acknowledgement response.Indicates the acknowledgement response.Negative Acknowledgement Group Function valuePositive Acknowledgement Group Function value";
CM_ BO_ 2565869310 "After Treatment Intake Gas 1";
CM_ SG_ 2565869310 AftrTrtmntIntkGsSnsorHeaterCtrl "Status message indicating the heater status in the warm-up process.";
CM_ SG_ 2565869310 AfterTreatmentIntakeO2 "The actual oxidation factor (%O2) of the gas within the exhaust stream.";
CM_ BO_ 2565869822 "After Treatment Intake Gas 1-b";
CM_ SG_ 2565869822 AftrTrtmntIntkGsSnsorHeaterCtrl "Status message indicating the heater status in the warm-up process.";
CM_ SG_ 2565869822 AfterTreatmentIntakeO2 "The actual oxidation factor (%O2) of the gas within the exhaust stream.";
CM_ BO_ 2566763774 "After Treatment Intake Gas 2";
CM_ SG_ 2566763774 ParticulateTrapIntakeGasTemp "Temperature of engine combustion byproducts entering the particulate trap.";
CM_ SG_ 2566763774 ExhaustGasTemp1 "The reading from the exhaust gas temperature sensor located farthest upstream in the after-treatment system.";
CM_ BO_ 2566763262 "After Treatment Intermediate Gas 1";
CM_ SG_ 2566763262 ParticulateTrapDiffPress "Exhaust differential pressure measured between the intake and exhaust of a particulate trap.";
CM_ SG_ 2566763262 PrtclateTrapIntermediateGasTemp "Temperature of engine combustion byproducts at a mid-point in the particulate trap.";
CM_ BO_ 2566762494 "After Treatment Intermediate Gas 1-b";
CM_ SG_ 2566762494 ParticulateTrapDiffPress "Exhaust differential pressure measured between the intake and exhaust of a particulate trap.";
CM_ SG_ 2566762494 PrtclateTrapIntermediateGasTemp "Temperature of engine combustion byproducts at a mid-point in the particulate trap.";
CM_ BO_ 2565869566 "After Treatment Outlet Gas 1";
CM_ SG_ 2565869566 AftrTrtmntOtltGsSnsorHeaterCtrl "Status message indicating the heater status in the warm-up process.";
CM_ SG_ 2565869566 AfterTreatmentOutletO2 "The actual oxidation factor (%O2) of the gas within the exhaust stream.";
CM_ BO_ 2565870078 "After Treatment Outlet Gas 1-b";
CM_ SG_ 2565870078 AftrTrtmntOtltGsSnsorHeaterCtrl "Status message indicating the heater status in the warm-up process.";
CM_ SG_ 2565870078 AfterTreatmentOutletO2 "The actual oxidation factor (%O2) of the gas within the exhaust stream.";
CM_ BO_ 2566763518 "After Treatment Outlet Gas 2";
CM_ SG_ 2566763518 ParticulateTrapOutletGasTemp "Temperature of engine combustion byproducts leaving the particulate trap exhaust.";
CM_ SG_ 2566763518 ExhaustGasTemp3 "The reading from the exhaust gas temperature sensor located farthest downstream in the after-treatment system.";
CM_ BO_ 2566762750 "After Treatment Outlet Gas 2-b";
CM_ SG_ 2566762750 ParticulateTrapOutletGasTemp "Temperature of engine combustion byproducts leaving the particulate trap exhaust.";
CM_ SG_ 2566762750 ExhaustGasTemp3 "The reading from the exhaust gas temperature sensor located farthest downstream in the after-treatment system.";
CM_ BO_ 2566803198 "Door Control 1";
CM_ SG_ 2566803198 Status2OfDoors "Composite indication of all bus door statuses.";
CM_ SG_ 2566803198 Ramp_WheelChairLiftPos "Signal which indicates the actual position of the ramp / wheel chair lift.";
CM_ SG_ 2566803198 PosOfDoors "Signal which indicates the actual position of the doors.";
CM_ BO_ 2565870334 "Fifth Wheel Smart Systems 1";
CM_ SG_ 2565870334 FifthWheelRollWarningIndicator "Indicates to the vehicle operator that the roll moment has exceeded a preset limit.";
CM_ SG_ 2565870334 FifthWheelRollMoment "Fifth wheel roll moment force.";
CM_ SG_ 2565870334 FifthWheelDrawbarForce "Fifth wheel drawbar force.";
CM_ SG_ 2565870334 FifthWheelVerticalForce "Fifth wheel vertical force.";
CM_ BO_ 2566762238 "Fifth Wheel Smart Systems 2";
CM_ SG_ 2566762238 FifthWheelSliderLockIndicator "Indicates to vehicle operator that the fifth wheel slider is in position and locked.";
CM_ SG_ 2566762238 FifthWheelSliderPos "Slider position measurement.";
CM_ SG_ 2566762238 FfthWhlLckCoupleStatusIndicator "Indicates results of coupling operation to the vehicle operator.";
CM_ SG_ 2566762238 FfthWhlLckRadyToCoupleIndicator "Indicates to the vehicle operator that the fifth wheel lock is open and ready to couple.";
CM_ SG_ 2566762238 FifthWheelErrorStatus "Fifth wheel error state conveys information when coupling status is incomplete or bad.";
CM_ BO_ 2364543998 "Slope Sensor Information";
CM_ SG_ 2364543998 RollAndPitchMeasurementLatency "The estimated measurement latency of the measurement.";
CM_ SG_ 2364543998 PitchAndRollCompensated "Compensated mode for the pitch and roll measurements.";
CM_ SG_ 2364543998 PitchRateFigureOfMerit "Figure of merit for the pitch rate measurement.";
CM_ SG_ 2364543998 RollAngleFigureOfMerit "Figure of merit for roll angle measurement.";
CM_ SG_ 2364543998 PitchAngleFigureOfMerit "Figure of merit for pitch angle measurement.";
CM_ SG_ 2364543998 RollAngle "The angle between the vehicle y-axis and the ground plane.";
CM_ SG_ 2364543998 PitchAngle "The angle between the vehicle x-axis and the ground plane.";
CM_ BO_ 2566846718 "Transmission Fluids 1";
CM_ SG_ 2566846718 TransOilLevelHigh_Low "Amount of current volume of transmission sump oil compared to recommended volume.";
CM_ SG_ 2566846718 TransOilTemp "Temperature of the transmission lubricant.";
CM_ SG_ 2566846718 TransOilPress "Gage pressure of lubrication fluid in transmission, measured after pump.";
CM_ SG_ 2566846718 TransOilLevel "Ratio of volume of transmission sump oil to recommended volume.";
CM_ SG_ 2566846718 ClutchPress "Gage pressure of oil within a wet clutch.";
CM_ BO_ 2566846462 "Vehicle Electrical Power #1";
CM_ SG_ 2566846462 BatteryPotentialSwitched "Electrical potential measured at the input of the electronic control unit supplied through a switching device.";
CM_ SG_ 2566846462 ElectricalPotential "Measured electrical potential of the battery.";
CM_ SG_ 2566846462 ChargingSystemPotential "Electrical potential measured at the charging system output.";
CM_ SG_ 2566846462 AltCurrent "Measure of electrical current flow from the alternator.";
CM_ SG_ 2566846462 NetBatteryCurrent "Net flow of electrical current into/out of the battery or batteries.";
CM_ BO_ 2566760702 "Wireless Communications Message 2";
CM_ SG_ 2566760702 NetworkSignalStrength2 "Indicates the signal strength for the wireless communications network type.";
CM_ BO_ 2566760958 "Wireless Communications Message 1";
CM_ SG_ 2566760958 NetworkSignalStrength1 "Indicates the signal strength for the wireless communications network type.";
CM_ BO_ 2633869310 "Voltage Regulator Operating Mode";
CM_ SG_ 2633869310 VoltageRegulatorEnabled "State signal indicating the Voltage regulator enabled.";
CM_ SG_ 2633869310 VoltageRegulatorSoftStartState "State signal indicating the mode of the Voltage regulator soft start function.";
CM_ SG_ 2633869310 VltgRgltrUndrfrqncyCmpnstnEnbld "State signal indicating the operating mode for underfrequency compensation.";
CM_ SG_ 2633869310 VltgRglatorLoadCompensationMode "State signal indicating the voltage regulator load compensation mode.";
CM_ BO_ 2365433598 "Voltage regulator excitation status";
CM_ SG_ 2365433598 GeneratorExcitationFieldCurrent "Measured signal that represents the generator excitation field current.";
CM_ SG_ 2365433598 GeneratorExcitationFieldVoltage "Measured signal that represents the generator excitation field voltage.";
BA_DEF_ BO_  "FrameFormat" ENUM  "StandardCAN","ExtendedCAN","reserved","J1939PG";
BA_DEF_ SG_  "SigType" STRING ;
BA_DEF_ SG_  "SPN" INT 0 524287;
BA_DEF_ BO_  "GenMsgRequestable" INT 0 1;
BA_DEF_ BO_  "GenMsgSendType" ENUM  "cyclic","spontan","cyclicIfActive","spontanWithDelay","cyclicAndSpontan","cyclicAndSpontanWithDelay","spontanWithRepetition","cyclicIfActiveAndSpontanWD","noMsgSendType";
BA_DEF_ BO_  "VFrameFormat" ENUM  "StandardCAN","ExtendedCAN","reserved","J1939PG";
BA_DEF_ BO_  "GenMsgCycleTime" INT 0 3600000;
BA_DEF_DEF_  "FrameFormat" "J1939PG";
BA_DEF_DEF_  "SigType" "";
BA_DEF_DEF_  "SPN" 0;
BA_DEF_DEF_  "GenMsgRequestable" 1;
BA_DEF_DEF_  "GenMsgSendType" "noMsgSendType";
BA_DEF_DEF_  "VFrameFormat" "J1939PG";
BA_DEF_DEF_  "GenMsgCycleTime" 0;
BA_ "GenMsgSendType" BO_ 2566845950 0;
BA_ "GenMsgCycleTime" BO_ 2566845950 1000;
BA_ "GenMsgSendType" BO_ 2566827774 0;
BA_ "GenMsgCycleTime" BO_ 2566827774 1000;
BA_ "GenMsgSendType" BO_ 2566846974 0;
BA_ "GenMsgCycleTime" BO_ 2566846974 1000;
BA_ "GenMsgSendType" BO_ 2566803966 0;
BA_ "GenMsgCycleTime" BO_ 2566803966 250;
BA_ "GenMsgSendType" BO_ 2432593918 0;
BA_ "GenMsgCycleTime" BO_ 2432593918 100;
BA_ "GenMsgSendType" BO_ 2566847998 0;
BA_ "GenMsgCycleTime" BO_ 2566847998 500;
BA_ "GenMsgSendType" BO_ 2565869310 0;
BA_ "GenMsgCycleTime" BO_ 2565869310 50;
BA_ "GenMsgSendType" BO_ 2565869822 0;
BA_ "GenMsgCycleTime" BO_ 2565869822 50;
BA_ "GenMsgSendType" BO_ 2566763774 0;
BA_ "GenMsgCycleTime" BO_ 2566763774 500;
BA_ "GenMsgSendType" BO_ 2566763262 0;
BA_ "GenMsgCycleTime" BO_ 2566763262 500;
BA_ "GenMsgSendType" BO_ 2566762494 0;
BA_ "GenMsgCycleTime" BO_ 2566762494 500;
BA_ "GenMsgSendType" BO_ 2565869566 0;
BA_ "GenMsgCycleTime" BO_ 2565869566 50;
BA_ "GenMsgSendType" BO_ 2565870078 0;
BA_ "GenMsgCycleTime" BO_ 2565870078 50;
BA_ "GenMsgSendType" BO_ 2566763518 0;
BA_ "GenMsgCycleTime" BO_ 2566763518 500;
BA_ "GenMsgSendType" BO_ 2566762750 0;
BA_ "GenMsgCycleTime" BO_ 2566762750 500;
BA_ "GenMsgSendType" BO_ 2566803198 0;
BA_ "GenMsgCycleTime" BO_ 2566803198 100;
BA_ "GenMsgSendType" BO_ 2565870334 0;
BA_ "GenMsgCycleTime" BO_ 2565870334 50;
BA_ "GenMsgSendType" BO_ 2364543998 0;
BA_ "GenMsgCycleTime" BO_ 2364543998 10;
BA_ "GenMsgSendType" BO_ 2566846718 0;
BA_ "GenMsgCycleTime" BO_ 2566846718 1000;
BA_ "GenMsgSendType" BO_ 2566846462 0;
BA_ "GenMsgCycleTime" BO_ 2566846462 1000;
BA_ "GenMsgSendType" BO_ 2633869310 0;
BA_ "GenMsgCycleTime" BO_ 2633869310 1000;
BA_ "GenMsgSendType" BO_ 2365433598 0;
BA_ "GenMsgCycleTime" BO_ 2365433598 100;
BA_ "SigType" SG_ 2566764542 OccurenceCount1 "RANGE";
BA_ "SPN" SG_ 2566764542 OccurenceCount1 1216;
BA_ "SPN" SG_ 2566764542 SPNConversionMethod1 1706;
BA_ "SPN" SG_ 2566764542 FailureModeIdentifier1 1215;
BA_ "SPN" SG_ 2566764542 SPN1 1214;
BA_ "SPN" SG_ 2566764542 ExpandedFreezeFrameLength 3149;
BA_ "SPN" SG_ 2566764542 SPN1High 1214;
BA_ "SPN" SG_ 2566764286 SPNSupported1High 3146;
BA_ "SPN" SG_ 2566764286 SPNSupported3High 3146;
BA_ "SPN" SG_ 2566764286 SPNSupported2High 3146;
BA_ "SPN" SG_ 2566764286 SPNSupported3 3146;
BA_ "SPN" SG_ 2566764286 SPNSupported2 3146;
BA_ "SPN" SG_ 2566764286 SPNDataLength3 3148;
BA_ "SPN" SG_ 2566764286 SPNDataLength2 3148;
BA_ "SPN" SG_ 2566764286 SPNDataLength1 3148;
BA_ "SPN" SG_ 2566764286 SPNSupported1 3146;
BA_ "SPN" SG_ 2555576062 FlashRedStopLamp 3039;
BA_ "SPN" SG_ 2555576062 FlashProtectLamp 3041;
BA_ "SigType" SG_ 2555576062 FlashMalfuncIndicatorLamp "DISCRETE";
BA_ "SPN" SG_ 2555576062 FlashMalfuncIndicatorLamp 3038;
BA_ "SPN" SG_ 2555576062 FlashAmberWarningLamp 3040;
BA_ "SigType" SG_ 2555576062 OccurenceCount1 "RANGE";
BA_ "SPN" SG_ 2555576062 OccurenceCount1 1216;
BA_ "SPN" SG_ 2555576062 SPNConversionMethod1 1706;
BA_ "SPN" SG_ 2555576062 FailureModeIdentifier1 1215;
BA_ "SPN" SG_ 2555576062 SPN1 1214;
BA_ "SigType" SG_ 2555576062 MalfunctionIndicatorLampStatus "DISCRETE";
BA_ "SPN" SG_ 2555576062 MalfunctionIndicatorLampStatus 1213;
BA_ "SigType" SG_ 2555576062 RedStopLampState "DISCRETE";
BA_ "SPN" SG_ 2555576062 RedStopLampState 623;
BA_ "SigType" SG_ 2555576062 AmberWarningLampStatus "DISCRETE";
BA_ "SPN" SG_ 2555576062 AmberWarningLampStatus 624;
BA_ "SigType" SG_ 2555576062 ProtectLampStatus "DISCRETE";
BA_ "SPN" SG_ 2555576062 ProtectLampStatus 987;
BA_ "SigType" SG_ 2555576062 OccurenceCount5 "RANGE";
BA_ "SigType" SG_ 2555576062 OccurenceCount4 "RANGE";
BA_ "SigType" SG_ 2555576062 OccurenceCount3 "RANGE";
BA_ "SigType" SG_ 2555576062 OccurenceCount2 "RANGE";
BA_ "SPN" SG_ 2555576062 SPN1High 1214;
BA_ "SPN" SG_ 2562981630 IndividualDTCClearControlByte 3034;
BA_ "SPN" SG_ 2562981630 CtrlByteIndicIndividualDTCClear 3035;
BA_ "SPN" SG_ 2562981630 SPN1 1214;
BA_ "SPN" SG_ 2562981630 SPN1High 1214;
BA_ "SPN" SG_ 2562981630 FailureModeIdentifier1 1215;
BA_ "SigType" SG_ 2562850558 TimeSinceDTCsCleared "RANGE";
BA_ "SPN" SG_ 2562850558 TimeSinceDTCsCleared 3145;
BA_ "SigType" SG_ 2562850558 MinutesRunByEngineMILActivated "RANGE";
BA_ "SPN" SG_ 2562850558 MinutesRunByEngineMILActivated 3144;
BA_ "SigType" SG_ 2562850558 DistanceSinceDTCsCleared "RANGE";
BA_ "SPN" SG_ 2562850558 DistanceSinceDTCsCleared 3143;
BA_ "SigType" SG_ 2562850558 DistanceWhileMILisActivated "RANGE";
BA_ "SPN" SG_ 2562850558 DistanceWhileMILisActivated 3069;
BA_ "SigType" SG_ 2562916094 ApplSysMonitorDenominator "RANGE";
BA_ "SPN" SG_ 2562916094 ApplSysMonitorDenominator 3068;
BA_ "SigType" SG_ 2562916094 ApplSysMonitorNumerator "RANGE";
BA_ "SPN" SG_ 2562916094 ApplSysMonitorNumerator 3067;
BA_ "SigType" SG_ 2562916094 SPNofApplSysMonitor "RANGE";
BA_ "SPN" SG_ 2562916094 SPNofApplSysMonitor 3066;
BA_ "SigType" SG_ 2562916094 OBDMonitoringCondEncountered "RANGE";
BA_ "SPN" SG_ 2562916094 OBDMonitoringCondEncountered 3049;
BA_ "SigType" SG_ 2562916094 IgnitionCycleCounter "RANGE";
BA_ "SPN" SG_ 2562916094 IgnitionCycleCounter 3048;
BA_ "SigType" SG_ 2566835198 OccurenceCount1 "RANGE";
BA_ "SPN" SG_ 2566835198 OccurenceCount1 1216;
BA_ "SPN" SG_ 2566835198 SPNConversionMethod1 1706;
BA_ "SPN" SG_ 2566835198 FailureModeIdentifier1 1215;
BA_ "SPN" SG_ 2566835198 SPN1 1214;
BA_ "SigType" SG_ 2566835198 MalfunctionIndicatorLampStatus "DISCRETE";
BA_ "SPN" SG_ 2566835198 MalfunctionIndicatorLampStatus 1213;
BA_ "SigType" SG_ 2566835198 RedStopLampState "DISCRETE";
BA_ "SPN" SG_ 2566835198 RedStopLampState 623;
BA_ "SigType" SG_ 2566835198 AmberWarningLampStatus "DISCRETE";
BA_ "SPN" SG_ 2566835198 AmberWarningLampStatus 624;
BA_ "SigType" SG_ 2566835198 ProtectLampStatus "DISCRETE";
BA_ "SPN" SG_ 2566835198 ProtectLampStatus 987;
BA_ "SPN" SG_ 2566835198 FlashRedStopLamp 3039;
BA_ "SPN" SG_ 2566835198 FlashProtectLamp 3041;
BA_ "SigType" SG_ 2566835198 FlashMalfuncIndicatorLamp "DISCRETE";
BA_ "SPN" SG_ 2566835198 FlashMalfuncIndicatorLamp 3038;
BA_ "SPN" SG_ 2566835198 FlashAmberWarningLamp 3040;
BA_ "SigType" SG_ 2566835198 OccurenceCount5 "RANGE";
BA_ "SigType" SG_ 2566835198 OccurenceCount4 "RANGE";
BA_ "SigType" SG_ 2566835198 OccurenceCount3 "RANGE";
BA_ "SigType" SG_ 2566835198 OccurenceCount2 "RANGE";
BA_ "SPN" SG_ 2566835198 SPN1High 1214;
BA_ "SPN" SG_ 2564030206 CalibrationID4 1635;
BA_ "SPN" SG_ 2564030206 CalibrationID3 1635;
BA_ "SPN" SG_ 2564030206 CalibrationID2 1635;
BA_ "SPN" SG_ 2564030206 CalibrationID1 1635;
BA_ "SigType" SG_ 2564030206 CalibrationVerificationNumber "RANGE";
BA_ "SPN" SG_ 2564030206 CalibrationVerificationNumber 1634;
BA_ "SPN" SG_ 2564423422 KeyOrUserLevel 1645;
BA_ "SPN" SG_ 2564423422 PointerExtension 1643;
BA_ "SPN" SG_ 2564423422 Pointer 1644;
BA_ "SPN" SG_ 2564423422 Command 1642;
BA_ "SPN" SG_ 2564423422 PointerType 1641;
BA_ "SPN" SG_ 2564423422 NumberRequested 1640;
BA_ "SPN" SG_ 2564423422 NumberRequestedHigh 1640;
BA_ "SigType" SG_ 2564816638 HoldSignal "DISCRETE";
BA_ "SPN" SG_ 2564816638 HoldSignal 1236;
BA_ "SigType" SG_ 2564816638 J1939Network3 "DISCRETE";
BA_ "SPN" SG_ 2564816638 J1939Network3 1235;
BA_ "SigType" SG_ 2564816638 J1939Network2 "DISCRETE";
BA_ "SPN" SG_ 2564816638 J1939Network2 1231;
BA_ "SigType" SG_ 2564816638 ISO9141 "DISCRETE";
BA_ "SPN" SG_ 2564816638 ISO9141 1232;
BA_ "SigType" SG_ 2564816638 SAE_J1850 "DISCRETE";
BA_ "SPN" SG_ 2564816638 SAE_J1850 1233;
BA_ "SigType" SG_ 2564816638 ManufacturerSpecificPort "DISCRETE";
BA_ "SPN" SG_ 2564816638 ManufacturerSpecificPort 1234;
BA_ "SigType" SG_ 2564816638 CurrentDataLink "DISCRETE";
BA_ "SPN" SG_ 2564816638 CurrentDataLink 1230;
BA_ "SigType" SG_ 2564816638 SAE_J1587 "DISCRETE";
BA_ "SPN" SG_ 2564816638 SAE_J1587 608;
BA_ "SigType" SG_ 2564816638 SAE_J1922 "DISCRETE";
BA_ "SPN" SG_ 2564816638 SAE_J1922 622;
BA_ "SigType" SG_ 2564816638 J1939Network1 "DISCRETE";
BA_ "SPN" SG_ 2564816638 J1939Network1 639;
BA_ "SPN" SG_ 2564816638 SuspendSignal 2618;
BA_ "SPN" SG_ 2564816638 SuspendDuration 2619;
BA_ "SPN" SG_ 2566837502 FlashRedStopLamp 3039;
BA_ "SPN" SG_ 2566837502 FlashProtectLamp 3041;
BA_ "SigType" SG_ 2566837502 OccurenceCount1 "RANGE";
BA_ "SPN" SG_ 2566837502 OccurenceCount1 1216;
BA_ "SPN" SG_ 2566837502 SPNConversionMethod1 1706;
BA_ "SPN" SG_ 2566837502 FailureModeIdentifier1 1215;
BA_ "SPN" SG_ 2566837502 SPN1 1214;
BA_ "SigType" SG_ 2566837502 MalfunctionIndicatorLampStatus "DISCRETE";
BA_ "SPN" SG_ 2566837502 MalfunctionIndicatorLampStatus 1213;
BA_ "SigType" SG_ 2566837502 RedStopLampState "DISCRETE";
BA_ "SPN" SG_ 2566837502 RedStopLampState 623;
BA_ "SigType" SG_ 2566837502 AmberWarningLampStatus "DISCRETE";
BA_ "SPN" SG_ 2566837502 AmberWarningLampStatus 624;
BA_ "SigType" SG_ 2566837502 ProtectLampStatus "DISCRETE";
BA_ "SPN" SG_ 2566837502 ProtectLampStatus 987;
BA_ "SigType" SG_ 2566837502 FlashMalfuncIndicatorLamp "DISCRETE";
BA_ "SPN" SG_ 2566837502 FlashMalfuncIndicatorLamp 3038;
BA_ "SPN" SG_ 2566837502 FlashAmberWarningLamp 3040;
BA_ "SigType" SG_ 2566837502 OccurenceCount5 "RANGE";
BA_ "SigType" SG_ 2566837502 OccurenceCount4 "RANGE";
BA_ "SigType" SG_ 2566837502 OccurenceCount3 "RANGE";
BA_ "SigType" SG_ 2566837502 OccurenceCount2 "RANGE";
BA_ "SPN" SG_ 2566837502 SPN1High 1214;
BA_ "SigType" SG_ 2566836990 TestIdentifierSupported "RANGE";
BA_ "SPN" SG_ 2566836990 TestIdentifierSupported 1229;
BA_ "SPN" SG_ 2566834942 FlashRedStopLamp 3039;
BA_ "SPN" SG_ 2566834942 FlashProtectLamp 3041;
BA_ "SigType" SG_ 2566834942 FlashMalfuncIndicatorLamp "DISCRETE";
BA_ "SPN" SG_ 2566834942 FlashMalfuncIndicatorLamp 3038;
BA_ "SPN" SG_ 2566834942 FlashAmberWarningLamp 3040;
BA_ "SigType" SG_ 2566834942 MalfunctionIndicatorLampStatus "DISCRETE";
BA_ "SPN" SG_ 2566834942 MalfunctionIndicatorLampStatus 1213;
BA_ "SigType" SG_ 2566834942 AmberWarningLampStatus "DISCRETE";
BA_ "SPN" SG_ 2566834942 AmberWarningLampStatus 624;
BA_ "SigType" SG_ 2566834942 OccurenceCount1 "RANGE";
BA_ "SPN" SG_ 2566834942 OccurenceCount1 1216;
BA_ "SPN" SG_ 2566834942 SPNConversionMethod1 1706;
BA_ "SPN" SG_ 2566834942 FailureModeIdentifier1 1215;
BA_ "SPN" SG_ 2566834942 SPN1 1214;
BA_ "SigType" SG_ 2566834942 RedStopLampState "DISCRETE";
BA_ "SPN" SG_ 2566834942 RedStopLampState 623;
BA_ "SigType" SG_ 2566834942 ProtectLampStatus "DISCRETE";
BA_ "SPN" SG_ 2566834942 ProtectLampStatus 987;
BA_ "SigType" SG_ 2566834942 OccurenceCount5 "RANGE";
BA_ "SigType" SG_ 2566834942 OccurenceCount4 "RANGE";
BA_ "SigType" SG_ 2566834942 OccurenceCount3 "RANGE";
BA_ "SigType" SG_ 2566834942 OccurenceCount2 "RANGE";
BA_ "SPN" SG_ 2566834942 SPN1High 1214;
BA_ "SigType" SG_ 2566780926 UtlityOverallPowerFactorLagging "DISCRETE";
BA_ "SPN" SG_ 2566780926 UtlityOverallPowerFactorLagging 2522;
BA_ "SigType" SG_ 2566780926 UtilityOverallPowerFactor "RANGE";
BA_ "SPN" SG_ 2566780926 UtilityOverallPowerFactor 2498;
BA_ "SigType" SG_ 2566780926 UtilityTotalReactivePower "RANGE";
BA_ "SPN" SG_ 2566780926 UtilityTotalReactivePower 2490;
BA_ "SigType" SG_ 2566781182 UtilityTotalApparentPower "RANGE";
BA_ "SPN" SG_ 2566781182 UtilityTotalApparentPower 2494;
BA_ "SigType" SG_ 2566781182 UtilityTotalRealPower "RANGE";
BA_ "SPN" SG_ 2566781182 UtilityTotalRealPower 2486;
BA_ "SigType" SG_ 2566778366 UtilityTotalKWHoursImport "DISCRETE";
BA_ "SPN" SG_ 2566778366 UtilityTotalKWHoursImport 2503;
BA_ "SigType" SG_ 2566778366 UtilityTotalKWHoursExport "DISCRETE";
BA_ "SPN" SG_ 2566778366 UtilityTotalKWHoursExport 2502;
BA_ "SigType" SG_ 2566778622 UtilityPhaseCPowerFactorLagging "DISCRETE";
BA_ "SPN" SG_ 2566778622 UtilityPhaseCPowerFactorLagging 2525;
BA_ "SigType" SG_ 2566778622 UtilityPhaseCPowerFactor "RANGE";
BA_ "SPN" SG_ 2566778622 UtilityPhaseCPowerFactor 2501;
BA_ "SigType" SG_ 2566778622 UtilityPhaseCReactivePower "RANGE";
BA_ "SPN" SG_ 2566778622 UtilityPhaseCReactivePower 2493;
BA_ "SigType" SG_ 2566778878 UtilityPhaseCApparentPower "RANGE";
BA_ "SPN" SG_ 2566778878 UtilityPhaseCApparentPower 2497;
BA_ "SigType" SG_ 2566778878 UtilityPhaseCRealPower "RANGE";
BA_ "SPN" SG_ 2566778878 UtilityPhaseCRealPower 2489;
BA_ "SigType" SG_ 2566779134 UtilityPhaseCACRMSCurrent "RANGE";
BA_ "SPN" SG_ 2566779134 UtilityPhaseCACRMSCurrent 2485;
BA_ "SigType" SG_ 2566779134 UtilityPhaseCACFrequency "RANGE";
BA_ "SPN" SG_ 2566779134 UtilityPhaseCACFrequency 2473;
BA_ "SigType" SG_ 2566779134 UtltyPhsCLneNeutralACRMSVoltage "RANGE";
BA_ "SPN" SG_ 2566779134 UtltyPhsCLneNeutralACRMSVoltage 2481;
BA_ "SigType" SG_ 2566779134 UtltyPhseCALineLineACRMSVoltage "RANGE";
BA_ "SPN" SG_ 2566779134 UtltyPhseCALineLineACRMSVoltage 2477;
BA_ "SigType" SG_ 2566779390 UtilityPhaseBPowerFactorLagging "DISCRETE";
BA_ "SPN" SG_ 2566779390 UtilityPhaseBPowerFactorLagging 2524;
BA_ "SigType" SG_ 2566779390 UtilityPhaseBPowerFactor "RANGE";
BA_ "SPN" SG_ 2566779390 UtilityPhaseBPowerFactor 2500;
BA_ "SigType" SG_ 2566779390 UtilityPhaseBReactivePower "RANGE";
BA_ "SPN" SG_ 2566779390 UtilityPhaseBReactivePower 2492;
BA_ "SigType" SG_ 2566779646 UtilityPhaseBApparentPower "RANGE";
BA_ "SPN" SG_ 2566779646 UtilityPhaseBApparentPower 2496;
BA_ "SigType" SG_ 2566779646 UtilityPhaseBRealPower "RANGE";
BA_ "SPN" SG_ 2566779646 UtilityPhaseBRealPower 2488;
BA_ "SigType" SG_ 2566779902 UtilityPhaseBACRMSCurrent "RANGE";
BA_ "SPN" SG_ 2566779902 UtilityPhaseBACRMSCurrent 2484;
BA_ "SigType" SG_ 2566779902 UtilityPhaseBACFrequency "RANGE";
BA_ "SPN" SG_ 2566779902 UtilityPhaseBACFrequency 2472;
BA_ "SigType" SG_ 2566779902 UtltyPhsBLneNeutralACRMSVoltage "RANGE";
BA_ "SPN" SG_ 2566779902 UtltyPhsBLneNeutralACRMSVoltage 2480;
BA_ "SigType" SG_ 2566779902 UtltyPhseBCLineLineACRMSVoltage "RANGE";
BA_ "SPN" SG_ 2566779902 UtltyPhseBCLineLineACRMSVoltage 2476;
BA_ "SigType" SG_ 2566780158 UtilityPhaseAPowerFactorLagging "DISCRETE";
BA_ "SPN" SG_ 2566780158 UtilityPhaseAPowerFactorLagging 2523;
BA_ "SigType" SG_ 2566780158 UtilityPhaseAPowerFactor "RANGE";
BA_ "SPN" SG_ 2566780158 UtilityPhaseAPowerFactor 2499;
BA_ "SigType" SG_ 2566780158 UtilityPhaseAReactivePower "RANGE";
BA_ "SPN" SG_ 2566780158 UtilityPhaseAReactivePower 2491;
BA_ "SigType" SG_ 2566780414 UtilityPhaseAApparentPower "RANGE";
BA_ "SPN" SG_ 2566780414 UtilityPhaseAApparentPower 2495;
BA_ "SigType" SG_ 2566780414 UtilityPhaseARealPower "RANGE";
BA_ "SPN" SG_ 2566780414 UtilityPhaseARealPower 2487;
BA_ "SigType" SG_ 2566780670 UtilityPhaseAACRMSCurrent "RANGE";
BA_ "SPN" SG_ 2566780670 UtilityPhaseAACRMSCurrent 2483;
BA_ "SigType" SG_ 2566780670 UtilityPhaseAACFrequency "RANGE";
BA_ "SPN" SG_ 2566780670 UtilityPhaseAACFrequency 2471;
BA_ "SigType" SG_ 2566780670 UtltyPhsALneNeutralACRMSVoltage "RANGE";
BA_ "SPN" SG_ 2566780670 UtltyPhsALneNeutralACRMSVoltage 2479;
BA_ "SigType" SG_ 2566780670 UtltyPhseABLineLineACRMSVoltage "RANGE";
BA_ "SPN" SG_ 2566780670 UtltyPhseABLineLineACRMSVoltage 2475;
BA_ "SigType" SG_ 2566781438 UtilityAverageACRMSCurrent "RANGE";
BA_ "SPN" SG_ 2566781438 UtilityAverageACRMSCurrent 2482;
BA_ "SigType" SG_ 2566781438 UtilityAverageACFrequency "RANGE";
BA_ "SPN" SG_ 2566781438 UtilityAverageACFrequency 2470;
BA_ "SigType" SG_ 2566781438 UtltyAvrgLneNeutralACRMSVoltage "RANGE";
BA_ "SPN" SG_ 2566781438 UtltyAvrgLneNeutralACRMSVoltage 2478;
BA_ "SigType" SG_ 2566781438 UtltyAvrageLineLineACRMSVoltage "RANGE";
BA_ "SPN" SG_ 2566781438 UtltyAvrageLineLineACRMSVoltage 2474;
BA_ "SigType" SG_ 2566784254 GnrtorOverallPowerFactorLagging "DISCRETE";
BA_ "SPN" SG_ 2566784254 GnrtorOverallPowerFactorLagging 2518;
BA_ "SigType" SG_ 2566784254 GeneratorOverallPowerFactor "RANGE";
BA_ "SPN" SG_ 2566784254 GeneratorOverallPowerFactor 2464;
BA_ "SigType" SG_ 2566784254 GeneratorTotalReactivePower "RANGE";
BA_ "SPN" SG_ 2566784254 GeneratorTotalReactivePower 2456;
BA_ "SigType" SG_ 2566784510 GeneratorTotalApparentPower "RANGE";
BA_ "SPN" SG_ 2566784510 GeneratorTotalApparentPower 2460;
BA_ "SigType" SG_ 2566784510 GeneratorTotalRealPower "RANGE";
BA_ "SPN" SG_ 2566784510 GeneratorTotalRealPower 2452;
BA_ "SigType" SG_ 2566781694 GeneratorTotalKWHoursImport "DISCRETE";
BA_ "SPN" SG_ 2566781694 GeneratorTotalKWHoursImport 2469;
BA_ "SigType" SG_ 2566781694 GeneratorTotalKWHoursExport "DISCRETE";
BA_ "SPN" SG_ 2566781694 GeneratorTotalKWHoursExport 2468;
BA_ "SigType" SG_ 2566781950 GnratorPhaseCPowerFactorLagging "DISCRETE";
BA_ "SPN" SG_ 2566781950 GnratorPhaseCPowerFactorLagging 2521;
BA_ "SigType" SG_ 2566781950 GeneratorPhaseCPowerFactor "RANGE";
BA_ "SPN" SG_ 2566781950 GeneratorPhaseCPowerFactor 2467;
BA_ "SigType" SG_ 2566781950 GeneratorPhaseCReactivePower "RANGE";
BA_ "SPN" SG_ 2566781950 GeneratorPhaseCReactivePower 2459;
BA_ "SigType" SG_ 2566782206 GeneratorPhaseCApparentPower "RANGE";
BA_ "SPN" SG_ 2566782206 GeneratorPhaseCApparentPower 2463;
BA_ "SigType" SG_ 2566782206 GeneratorPhaseCRealPower "RANGE";
BA_ "SPN" SG_ 2566782206 GeneratorPhaseCRealPower 2455;
BA_ "SigType" SG_ 2566782462 GeneratorPhaseCACRMSCurrent "RANGE";
BA_ "SPN" SG_ 2566782462 GeneratorPhaseCACRMSCurrent 2451;
BA_ "SigType" SG_ 2566782462 GeneratorPhaseCACFrequency "RANGE";
BA_ "SPN" SG_ 2566782462 GeneratorPhaseCACFrequency 2439;
BA_ "SigType" SG_ 2566782462 GnrtrPhsCLneNeutralACRMSVoltage "RANGE";
BA_ "SPN" SG_ 2566782462 GnrtrPhsCLneNeutralACRMSVoltage 2447;
BA_ "SigType" SG_ 2566782462 GnrtrPhseCALineLineACRMSVoltage "RANGE";
BA_ "SPN" SG_ 2566782462 GnrtrPhseCALineLineACRMSVoltage 2443;
BA_ "SigType" SG_ 2566782718 GnratorPhaseBPowerFactorLagging "DISCRETE";
BA_ "SPN" SG_ 2566782718 GnratorPhaseBPowerFactorLagging 2520;
BA_ "SigType" SG_ 2566782718 GeneratorPhaseBPowerFactor "RANGE";
BA_ "SPN" SG_ 2566782718 GeneratorPhaseBPowerFactor 2466;
BA_ "SigType" SG_ 2566782718 GeneratorPhaseBReactivePower "RANGE";
BA_ "SPN" SG_ 2566782718 GeneratorPhaseBReactivePower 2458;
BA_ "SigType" SG_ 2566782974 GeneratorPhaseBApparentPower "RANGE";
BA_ "SPN" SG_ 2566782974 GeneratorPhaseBApparentPower 2462;
BA_ "SigType" SG_ 2566782974 GeneratorPhaseBRealPower "RANGE";
BA_ "SPN" SG_ 2566782974 GeneratorPhaseBRealPower 2454;
BA_ "SigType" SG_ 2566783230 GeneratorPhaseBACRMSCurrent "RANGE";
BA_ "SPN" SG_ 2566783230 GeneratorPhaseBACRMSCurrent 2450;
BA_ "SigType" SG_ 2566783230 GeneratorPhaseBACFrequency "RANGE";
BA_ "SPN" SG_ 2566783230 GeneratorPhaseBACFrequency 2438;
BA_ "SigType" SG_ 2566783230 GnrtrPhsBLneNeutralACRMSVoltage "RANGE";
BA_ "SPN" SG_ 2566783230 GnrtrPhsBLneNeutralACRMSVoltage 2446;
BA_ "SigType" SG_ 2566783230 GnrtrPhseBCLineLineACRMSVoltage "RANGE";
BA_ "SPN" SG_ 2566783230 GnrtrPhseBCLineLineACRMSVoltage 2442;
BA_ "SigType" SG_ 2566783486 GnratorPhaseAPowerFactorLagging "DISCRETE";
BA_ "SPN" SG_ 2566783486 GnratorPhaseAPowerFactorLagging 2519;
BA_ "SigType" SG_ 2566783486 GeneratorPhaseAPowerFactor "RANGE";
BA_ "SPN" SG_ 2566783486 GeneratorPhaseAPowerFactor 2465;
BA_ "SigType" SG_ 2566783486 GeneratorPhaseAReactivePower "RANGE";
BA_ "SPN" SG_ 2566783486 GeneratorPhaseAReactivePower 2457;
BA_ "SigType" SG_ 2566783742 GeneratorPhaseAApparentPower "RANGE";
BA_ "SPN" SG_ 2566783742 GeneratorPhaseAApparentPower 2461;
BA_ "SigType" SG_ 2566783742 GeneratorPhaseARealPower "RANGE";
BA_ "SPN" SG_ 2566783742 GeneratorPhaseARealPower 2453;
BA_ "SigType" SG_ 2566783998 GeneratorPhaseAACRMSCurrent "RANGE";
BA_ "SPN" SG_ 2566783998 GeneratorPhaseAACRMSCurrent 2449;
BA_ "SigType" SG_ 2566783998 GeneratorPhaseAACFrequency "RANGE";
BA_ "SPN" SG_ 2566783998 GeneratorPhaseAACFrequency 2437;
BA_ "SigType" SG_ 2566783998 GnrtrPhsALneNeutralACRMSVoltage "RANGE";
BA_ "SPN" SG_ 2566783998 GnrtrPhsALneNeutralACRMSVoltage 2445;
BA_ "SigType" SG_ 2566783998 GnrtrPhseABLineLineACRMSVoltage "RANGE";
BA_ "SPN" SG_ 2566783998 GnrtrPhseABLineLineACRMSVoltage 2441;
BA_ "SigType" SG_ 2566784766 GeneratorAverageACRMSCurrent "RANGE";
BA_ "SPN" SG_ 2566784766 GeneratorAverageACRMSCurrent 2448;
BA_ "SigType" SG_ 2566784766 GeneratorAverageACFrequency "RANGE";
BA_ "SPN" SG_ 2566784766 GeneratorAverageACFrequency 2436;
BA_ "SigType" SG_ 2566784766 GnrtrAvrgLneNeutralACRMSVoltage "RANGE";
BA_ "SPN" SG_ 2566784766 GnrtrAvrgLneNeutralACRMSVoltage 2444;
BA_ "SigType" SG_ 2566784766 GnrtrAvrageLineLineACRMSVoltage "RANGE";
BA_ "SPN" SG_ 2566784766 GnrtrAvrageLineLineACRMSVoltage 2440;
BA_ "SigType" SG_ 2566776830 Bus1_UtilityACPhaseDifference "RANGE";
BA_ "SPN" SG_ 2566776830 Bus1_UtilityACPhaseDifference 2517;
BA_ "SigType" SG_ 2566776830 Bus1_UtilityInSync "DISCRETE";
BA_ "SPN" SG_ 2566776830 Bus1_UtilityInSync 2534;
BA_ "SigType" SG_ 2566776830 Bus1_UtilityVoltageMatch "DISCRETE";
BA_ "SPN" SG_ 2566776830 Bus1_UtilityVoltageMatch 2532;
BA_ "SigType" SG_ 2566776830 Bus1_UtilityFrequencyMatch "DISCRETE";
BA_ "SPN" SG_ 2566776830 Bus1_UtilityFrequencyMatch 2533;
BA_ "SigType" SG_ 2566776830 Bus1_UtilityPhaseMatch "DISCRETE";
BA_ "SPN" SG_ 2566776830 Bus1_UtilityPhaseMatch 2531;
BA_ "SigType" SG_ 2566776830 Bus1_UtilityDeadBus "DISCRETE";
BA_ "SPN" SG_ 2566776830 Bus1_UtilityDeadBus 2535;
BA_ "SigType" SG_ 2566777342 Bus1PhaseCACFrequency "RANGE";
BA_ "SPN" SG_ 2566777342 Bus1PhaseCACFrequency 2507;
BA_ "SigType" SG_ 2566777342 Bs1PhseCLineNeutralACRMSVoltage "RANGE";
BA_ "SPN" SG_ 2566777342 Bs1PhseCLineNeutralACRMSVoltage 2515;
BA_ "SigType" SG_ 2566777342 Bus1PhaseCALineLineACRMSVoltage "RANGE";
BA_ "SPN" SG_ 2566777342 Bus1PhaseCALineLineACRMSVoltage 2511;
BA_ "SigType" SG_ 2566777598 Bus1PhaseBACFrequency "RANGE";
BA_ "SPN" SG_ 2566777598 Bus1PhaseBACFrequency 2506;
BA_ "SigType" SG_ 2566777598 Bs1PhseBLineNeutralACRMSVoltage "RANGE";
BA_ "SPN" SG_ 2566777598 Bs1PhseBLineNeutralACRMSVoltage 2514;
BA_ "SigType" SG_ 2566777598 Bus1PhaseBCLineLineACRMSVoltage "RANGE";
BA_ "SPN" SG_ 2566777598 Bus1PhaseBCLineLineACRMSVoltage 2510;
BA_ "SigType" SG_ 2566777854 Bus1PhaseAACFrequency "RANGE";
BA_ "SPN" SG_ 2566777854 Bus1PhaseAACFrequency 2505;
BA_ "SigType" SG_ 2566777854 Bs1PhseALineNeutralACRMSVoltage "RANGE";
BA_ "SPN" SG_ 2566777854 Bs1PhseALineNeutralACRMSVoltage 2513;
BA_ "SigType" SG_ 2566777854 Bus1PhaseABLineLineACRMSVoltage "RANGE";
BA_ "SPN" SG_ 2566777854 Bus1PhaseABLineLineACRMSVoltage 2509;
BA_ "SigType" SG_ 2566777086 Bus1_GeneratorACPhaseDifference "RANGE";
BA_ "SPN" SG_ 2566777086 Bus1_GeneratorACPhaseDifference 2516;
BA_ "SigType" SG_ 2566777086 Bus1_GeneratorInSync "DISCRETE";
BA_ "SPN" SG_ 2566777086 Bus1_GeneratorInSync 2529;
BA_ "SigType" SG_ 2566777086 Bus1_GeneratorVoltageMatch "DISCRETE";
BA_ "SPN" SG_ 2566777086 Bus1_GeneratorVoltageMatch 2527;
BA_ "SigType" SG_ 2566777086 Bus1_GeneratorFrequencyMatch "DISCRETE";
BA_ "SPN" SG_ 2566777086 Bus1_GeneratorFrequencyMatch 2528;
BA_ "SigType" SG_ 2566777086 Bus1_GeneratorPhaseMatch "DISCRETE";
BA_ "SPN" SG_ 2566777086 Bus1_GeneratorPhaseMatch 2526;
BA_ "SigType" SG_ 2566777086 Bus1_GeneratorDeadBus "DISCRETE";
BA_ "SPN" SG_ 2566777086 Bus1_GeneratorDeadBus 2530;
BA_ "SigType" SG_ 2566778110 Bus1AverageACFrequency "RANGE";
BA_ "SPN" SG_ 2566778110 Bus1AverageACFrequency 2504;
BA_ "SigType" SG_ 2566778110 Bs1AvrgeLineNeutralACRMSVoltage "RANGE";
BA_ "SPN" SG_ 2566778110 Bs1AvrgeLineNeutralACRMSVoltage 2512;
BA_ "SigType" SG_ 2566778110 Bus1AverageLineLineACRMSVoltage "RANGE";
BA_ "SPN" SG_ 2566778110 Bus1AverageLineLineACRMSVoltage 2508;
BA_ "SigType" SG_ 2633895422 NameOfWorkingSetMember "ASCII";
BA_ "SigType" SG_ 2566838526 AddressAssignment "RANGE";
BA_ "SPN" SG_ 2566838526 AddressAssignment 2847;
BA_ "SigType" SG_ 2563440382 ShrtNameOfActualReportingDevice "DISCRETE";
BA_ "SPN" SG_ 2563440382 ShrtNameOfActualReportingDevice 2554;
BA_ "SigType" SG_ 2563440382 LengthOfDataForTheReportedPGN "RANGE";
BA_ "SPN" SG_ 2563440382 LengthOfDataForTheReportedPGN 2553;
BA_ "SigType" SG_ 2563440382 PGNofRequstedInformation "RANGE";
BA_ "SPN" SG_ 2563440382 PGNofRequstedInformation 2552;
BA_ "SigType" SG_ 2565603070 SequenceNumber "RANGE";
BA_ "SPN" SG_ 2565603070 SequenceNumber 2572;
BA_ "SigType" SG_ 2565668606 TotalNumberOfPacketsEoMA "RANGE";
BA_ "SPN" SG_ 2565668606 TotalNumberOfPacketsEoMA 2558;
BA_ "SigType" SG_ 2565668606 TotalMessageSizeEoMA "RANGE";
BA_ "SPN" SG_ 2565668606 TotalMessageSizeEoMA 2557;
BA_ "SigType" SG_ 2565668606 TotalMessageSizeBAM "RANGE";
BA_ "SPN" SG_ 2565668606 TotalMessageSizeBAM 2557;
BA_ "SigType" SG_ 2565668606 TotalNumberOfPacketsBAM "RANGE";
BA_ "SPN" SG_ 2565668606 TotalNumberOfPacketsBAM 2558;
BA_ "SigType" SG_ 2565668606 ConnectionAbortReason "RANGE";
BA_ "SPN" SG_ 2565668606 ConnectionAbortReason 2570;
BA_ "SigType" SG_ 2565668606 NextPacketNumberToBeSent "RANGE";
BA_ "SPN" SG_ 2565668606 NextPacketNumberToBeSent 2562;
BA_ "SigType" SG_ 2565668606 NumberOfPacketsThatCanBeSent "RANGE";
BA_ "SPN" SG_ 2565668606 NumberOfPacketsThatCanBeSent 2561;
BA_ "SPN" SG_ 2565668606 PGNumber 2560;
BA_ "SigType" SG_ 2565668606 MaximumNumberOfPackets "RANGE";
BA_ "SPN" SG_ 2565668606 MaximumNumberOfPackets 2559;
BA_ "SigType" SG_ 2565668606 TotalNumberOfPackets "RANGE";
BA_ "SPN" SG_ 2565668606 TotalNumberOfPackets 2558;
BA_ "SigType" SG_ 2565668606 TotalMessageSize "RANGE";
BA_ "SPN" SG_ 2565668606 TotalMessageSize 2557;
BA_ "SPN" SG_ 2565668606 ControlByte 2556;
BA_ "SigType" SG_ 2563374846 UseTransferMode "DISCRETE";
BA_ "SPN" SG_ 2563374846 UseTransferMode 2575;
BA_ "SigType" SG_ 2563374846 ParameterGroupNumber "RANGE";
BA_ "SPN" SG_ 2563374846 ParameterGroupNumber 2574;
BA_ "SigType" SG_ 2565537534 ParameterGroupNumber "RANGE";
BA_ "SPN" SG_ 2565537534 ParameterGroupNumber 2574;
BA_ "SigType" SG_ 2566845950 RoadSurfaceTemp "RANGE";
BA_ "SPN" SG_ 2566845950 RoadSurfaceTemp 79;
BA_ "SigType" SG_ 2566845950 EngAirInletTemp "RANGE";
BA_ "SPN" SG_ 2566845950 EngAirInletTemp 172;
BA_ "SigType" SG_ 2566845950 AmbientAirTemp "RANGE";
BA_ "SPN" SG_ 2566845950 AmbientAirTemp 171;
BA_ "SigType" SG_ 2566845950 CabInteriorTemp "RANGE";
BA_ "SPN" SG_ 2566845950 CabInteriorTemp 170;
BA_ "SigType" SG_ 2566845950 BarometricPress "RANGE";
BA_ "SPN" SG_ 2566845950 BarometricPress 108;
BA_ "SigType" SG_ 2566840062 EngAirStartPress "RANGE";
BA_ "SPN" SG_ 2566840062 EngAirStartPress 82;
BA_ "SigType" SG_ 2566827774 AirCompressorStatus "DISCRETE";
BA_ "SPN" SG_ 2566827774 AirCompressorStatus 1351;
BA_ "SigType" SG_ 2566827774 AirSuspensionSupplyPress "RANGE";
BA_ "SPN" SG_ 2566827774 AirSuspensionSupplyPress 1090;
BA_ "SigType" SG_ 2566827774 AuxEquipmentSupplyPress "RANGE";
BA_ "SPN" SG_ 2566827774 AuxEquipmentSupplyPress 1089;
BA_ "SigType" SG_ 2566827774 ServiceBrakeAirPressCircuit2 "RANGE";
BA_ "SPN" SG_ 2566827774 ServiceBrakeAirPressCircuit2 1088;
BA_ "SigType" SG_ 2566827774 ServiceBrakeAirPressCircuit1 "RANGE";
BA_ "SPN" SG_ 2566827774 ServiceBrakeAirPressCircuit1 1087;
BA_ "SigType" SG_ 2566827774 ParkingAnd_OrTrailerAirPress "RANGE";
BA_ "SPN" SG_ 2566827774 ParkingAnd_OrTrailerAirPress 1086;
BA_ "SigType" SG_ 2566827774 PneumaticSupplyPress "RANGE";
BA_ "SPN" SG_ 2566827774 PneumaticSupplyPress 46;
BA_ "SigType" SG_ 2566846974 SteerAxleLubePress "RANGE";
BA_ "SPN" SG_ 2566846974 SteerAxleLubePress 2614;
BA_ "SigType" SG_ 2566846974 SteerAxleTemp "RANGE";
BA_ "SPN" SG_ 2566846974 SteerAxleTemp 75;
BA_ "SigType" SG_ 2566846974 DriveAxleLubePress "RANGE";
BA_ "SPN" SG_ 2566846974 DriveAxleLubePress 2613;
BA_ "SigType" SG_ 2566846974 DriveAxleTemp "RANGE";
BA_ "SPN" SG_ 2566846974 DriveAxleTemp 578;
BA_ "SigType" SG_ 2566846974 DriveAxleLiftAirPress "RANGE";
BA_ "SPN" SG_ 2566846974 DriveAxleLiftAirPress 579;
BA_ "SigType" SG_ 2566846974 DriveAxleLocation "RANGE";
BA_ "SPN" SG_ 2566846974 DriveAxleLocation 930;
BA_ "SigType" SG_ 2633935614 EngTurboWastegateValvePos "RANGE";
BA_ "SPN" SG_ 2633935614 EngTurboWastegateValvePos 1693;
BA_ "SigType" SG_ 2633935614 EngGsMssFlwSnsrFelingCorrection "RANGE";
BA_ "SPN" SG_ 2633935614 EngGsMssFlwSnsrFelingCorrection 1694;
BA_ "SigType" SG_ 2633935614 EngDsiredAbsIntakeManifoldPress "RANGE";
BA_ "SPN" SG_ 2633935614 EngDsiredAbsIntakeManifoldPress 1692;
BA_ "SigType" SG_ 2633935614 EngGasFuelCorrectionFactor "RANGE";
BA_ "SPN" SG_ 2633935614 EngGasFuelCorrectionFactor 1116;
BA_ "SigType" SG_ 2566803966 RqedACCDistanceMode "DISCRETE";
BA_ "SPN" SG_ 2566803966 RqedACCDistanceMode 1799;
BA_ "SigType" SG_ 2432593918 ACCDistanceAlertSignal "DISCRETE";
BA_ "SPN" SG_ 2432593918 ACCDistanceAlertSignal 1796;
BA_ "SigType" SG_ 2432593918 ACCSystemShutoffWarning "DISCRETE";
BA_ "SPN" SG_ 2432593918 ACCSystemShutoffWarning 1797;
BA_ "SigType" SG_ 2432593918 ACCTargetDetected "DISCRETE";
BA_ "SPN" SG_ 2432593918 ACCTargetDetected 1798;
BA_ "SigType" SG_ 2432593918 RoadCurvature "RANGE";
BA_ "SPN" SG_ 2432593918 RoadCurvature 1591;
BA_ "SigType" SG_ 2432593918 AdptveCruiseCtrlSetDistanceMode "DISCRETE";
BA_ "SPN" SG_ 2432593918 AdptveCruiseCtrlSetDistanceMode 1589;
BA_ "SigType" SG_ 2432593918 AdaptiveCruiseCtrlMode "DISCRETE";
BA_ "SPN" SG_ 2432593918 AdaptiveCruiseCtrlMode 1590;
BA_ "SigType" SG_ 2432593918 AdaptiveCruiseCtrlSetSpeed "RANGE";
BA_ "SPN" SG_ 2432593918 AdaptiveCruiseCtrlSetSpeed 1588;
BA_ "SigType" SG_ 2432593918 DistanceToForwardVehicle "RANGE";
BA_ "SPN" SG_ 2432593918 DistanceToForwardVehicle 1587;
BA_ "SigType" SG_ 2432593918 SpeedOfForwardVehicle "RANGE";
BA_ "SPN" SG_ 2432593918 SpeedOfForwardVehicle 1586;
BA_ "SigType" SG_ 2633935102 ArticulationAngle "RANGE";
BA_ "SPN" SG_ 2633935102 ArticulationAngle 1120;
BA_ "SigType" SG_ 2633927934 AuxLevel "RANGE";
BA_ "SPN" SG_ 2633927934 AuxLevel 3087;
BA_ "SigType" SG_ 2633927934 AuxPress2 "RANGE";
BA_ "SPN" SG_ 2633927934 AuxPress2 1388;
BA_ "SigType" SG_ 2633927934 AuxPress1 "RANGE";
BA_ "SPN" SG_ 2633927934 AuxPress1 1387;
BA_ "SigType" SG_ 2633927934 AuxTemp2 "RANGE";
BA_ "SPN" SG_ 2633927934 AuxTemp2 442;
BA_ "SigType" SG_ 2633927934 AuxTemp1 "RANGE";
BA_ "SPN" SG_ 2633927934 AuxTemp1 441;
BA_ "SigType" SG_ 2566847998 EngBlowerBypassValvePos "RANGE";
BA_ "SPN" SG_ 2566847998 EngBlowerBypassValvePos 72;
BA_ "SigType" SG_ 2566847998 EngGasSupplyPress "RANGE";
BA_ "SPN" SG_ 2566847998 EngGasSupplyPress 159;
BA_ "SigType" SG_ 2565406462 ParameterGroupNumber "RANGE";
BA_ "SPN" SG_ 2565406462 ParameterGroupNumber 2574;
BA_ "SigType" SG_ 2565406462 GroupFunctionValue "RANGE";
BA_ "SPN" SG_ 2565406462 GroupFunctionValue 2542;
BA_ "SPN" SG_ 2565406462 ControlByte 2556;
BA_ "SigType" SG_ 2565869310 AftrTrtmntIntkOxygnSnsrPrlmnryFM "RANGE";
BA_ "SPN" SG_ 2565869310 AftrTrtmntIntkOxygnSnsrPrlmnryFM 3225;
BA_ "SigType" SG_ 2565869310 AftrTrtmntIntkNOxSnsrPrlmnryFMI "RANGE";
BA_ "SPN" SG_ 2565869310 AftrTrtmntIntkNOxSnsrPrlmnryFMI 3224;
BA_ "SigType" SG_ 2565869310 AftrTrtmntIntkGsSnsorHeaterCtrl "DISCRETE";
BA_ "SPN" SG_ 2565869310 AftrTrtmntIntkGsSnsorHeaterCtrl 3223;
BA_ "SigType" SG_ 2565869310 AftrTrtmntIntkGsSnsrHtrPrlmnryFM "RANGE";
BA_ "SPN" SG_ 2565869310 AftrTrtmntIntkGsSnsrHtrPrlmnryFM 3222;
BA_ "SigType" SG_ 2565869310 AftrTrtmntIntkWdRngO2RdngStable "DISCRETE";
BA_ "SPN" SG_ 2565869310 AftrTrtmntIntkWdRngO2RdngStable 3221;
BA_ "SigType" SG_ 2565869310 AftrTrtmntIntkeNOxReadingStable "DISCRETE";
BA_ "SPN" SG_ 2565869310 AftrTrtmntIntkeNOxReadingStable 3220;
BA_ "SigType" SG_ 2565869310 AftrTrtmntIntakeGasSensorAtTemp "DISCRETE";
BA_ "SPN" SG_ 2565869310 AftrTrtmntIntakeGasSensorAtTemp 3219;
BA_ "SigType" SG_ 2565869310 AftrTrtmntIntkGsSnsrPwerInRange "DISCRETE";
BA_ "SPN" SG_ 2565869310 AftrTrtmntIntkGsSnsrPwerInRange 3218;
BA_ "SigType" SG_ 2565869310 AfterTreatmentIntakeO2 "RANGE";
BA_ "SPN" SG_ 2565869310 AfterTreatmentIntakeO2 3217;
BA_ "SigType" SG_ 2565869310 AfterTreatmentIntakeNOx "RANGE";
BA_ "SPN" SG_ 2565869310 AfterTreatmentIntakeNOx 3216;
BA_ "SigType" SG_ 2565869822 AftrTrtmntIntkOxygnSnsrPrlmnryFM "RANGE";
BA_ "SPN" SG_ 2565869822 AftrTrtmntIntkOxygnSnsrPrlmnryFM 3225;
BA_ "SigType" SG_ 2565869822 AftrTrtmntIntkNOxSnsrPrlmnryFMI "RANGE";
BA_ "SPN" SG_ 2565869822 AftrTrtmntIntkNOxSnsrPrlmnryFMI 3224;
BA_ "SigType" SG_ 2565869822 AftrTrtmntIntkGsSnsorHeaterCtrl "DISCRETE";
BA_ "SPN" SG_ 2565869822 AftrTrtmntIntkGsSnsorHeaterCtrl 3223;
BA_ "SigType" SG_ 2565869822 AftrTrtmntIntkGsSnsrHtrPrlmnryFM "RANGE";
BA_ "SPN" SG_ 2565869822 AftrTrtmntIntkGsSnsrHtrPrlmnryFM 3222;
BA_ "SigType" SG_ 2565869822 AftrTrtmntIntkWdRngO2RdngStable "DISCRETE";
BA_ "SPN" SG_ 2565869822 AftrTrtmntIntkWdRngO2RdngStable 3221;
BA_ "SigType" SG_ 2565869822 AftrTrtmntIntkeNOxReadingStable "DISCRETE";
BA_ "SPN" SG_ 2565869822 AftrTrtmntIntkeNOxReadingStable 3220;
BA_ "SigType" SG_ 2565869822 AftrTrtmntIntakeGasSensorAtTemp "DISCRETE";
BA_ "SPN" SG_ 2565869822 AftrTrtmntIntakeGasSensorAtTemp 3219;
BA_ "SigType" SG_ 2565869822 AftrTrtmntIntkGsSnsrPwerInRange "DISCRETE";
BA_ "SPN" SG_ 2565869822 AftrTrtmntIntkGsSnsrPwerInRange 3218;
BA_ "SigType" SG_ 2565869822 AfterTreatmentIntakeO2 "RANGE";
BA_ "SPN" SG_ 2565869822 AfterTreatmentIntakeO2 3217;
BA_ "SigType" SG_ 2565869822 AfterTreatmentIntakeNOx "RANGE";
BA_ "SPN" SG_ 2565869822 AfterTreatmentIntakeNOx 3216;
BA_ "SigType" SG_ 2566763774 PrtcltTrpIntkGsTmpPrliminaryFMI "RANGE";
BA_ "SPN" SG_ 2566763774 PrtcltTrpIntkGsTmpPrliminaryFMI 3244;
BA_ "SigType" SG_ 2566763774 ExhaustGasTemp1PreliminaryFMI "RANGE";
BA_ "SPN" SG_ 2566763774 ExhaustGasTemp1PreliminaryFMI 3243;
BA_ "SigType" SG_ 2566763774 ParticulateTrapIntakeGasTemp "RANGE";
BA_ "SPN" SG_ 2566763774 ParticulateTrapIntakeGasTemp 3242;
BA_ "SigType" SG_ 2566763774 ExhaustGasTemp1 "RANGE";
BA_ "SPN" SG_ 2566763774 ExhaustGasTemp1 3241;
BA_ "SigType" SG_ 2566763262 PrtcltTrpIntrmdtGsTmpPrlmnryFMI "RANGE";
BA_ "SPN" SG_ 2566763262 PrtcltTrpIntrmdtGsTmpPrlmnryFMI 3254;
BA_ "SigType" SG_ 2566763262 PrtcltTrpDltPressPreliminaryFMI "RANGE";
BA_ "SPN" SG_ 2566763262 PrtcltTrpDltPressPreliminaryFMI 3253;
BA_ "SigType" SG_ 2566763262 ExhaustGasTemp2PreliminaryFMI "RANGE";
BA_ "SPN" SG_ 2566763262 ExhaustGasTemp2PreliminaryFMI 3252;
BA_ "SigType" SG_ 2566763262 ParticulateTrapDiffPress "RANGE";
BA_ "SPN" SG_ 2566763262 ParticulateTrapDiffPress 3251;
BA_ "SigType" SG_ 2566763262 PrtclateTrapIntermediateGasTemp "RANGE";
BA_ "SPN" SG_ 2566763262 PrtclateTrapIntermediateGasTemp 3250;
BA_ "SigType" SG_ 2566763262 ExhaustGasTemp2 "RANGE";
BA_ "SPN" SG_ 2566763262 ExhaustGasTemp2 3249;
BA_ "SigType" SG_ 2566762494 PrtcltTrpIntrmdtGsTmpPrlmnryFMI "RANGE";
BA_ "SPN" SG_ 2566762494 PrtcltTrpIntrmdtGsTmpPrlmnryFMI 3254;
BA_ "SigType" SG_ 2566762494 PrtcltTrpDltPressPreliminaryFMI "RANGE";
BA_ "SPN" SG_ 2566762494 PrtcltTrpDltPressPreliminaryFMI 3253;
BA_ "SigType" SG_ 2566762494 ExhaustGasTemp2PreliminaryFMI "RANGE";
BA_ "SPN" SG_ 2566762494 ExhaustGasTemp2PreliminaryFMI 3252;
BA_ "SigType" SG_ 2566762494 ParticulateTrapDiffPress "RANGE";
BA_ "SPN" SG_ 2566762494 ParticulateTrapDiffPress 3251;
BA_ "SigType" SG_ 2566762494 PrtclateTrapIntermediateGasTemp "RANGE";
BA_ "SPN" SG_ 2566762494 PrtclateTrapIntermediateGasTemp 3250;
BA_ "SigType" SG_ 2566762494 ExhaustGasTemp2 "RANGE";
BA_ "SPN" SG_ 2566762494 ExhaustGasTemp2 3249;
BA_ "SigType" SG_ 2565869566 AftrTrtmntOtltOxygnSnsrPrlmnryFM "RANGE";
BA_ "SPN" SG_ 2565869566 AftrTrtmntOtltOxygnSnsrPrlmnryFM 3235;
BA_ "SigType" SG_ 2565869566 AftrTrtmntOtltNOxSnsrPrlmnryFMI "RANGE";
BA_ "SPN" SG_ 2565869566 AftrTrtmntOtltNOxSnsrPrlmnryFMI 3234;
BA_ "SigType" SG_ 2565869566 AftrTrtmntOtltGsSnsorHeaterCtrl "DISCRETE";
BA_ "SPN" SG_ 2565869566 AftrTrtmntOtltGsSnsorHeaterCtrl 3233;
BA_ "SigType" SG_ 2565869566 AftrTrtmntOtltGsSnsrHtrPrlmnryFM "RANGE";
BA_ "SPN" SG_ 2565869566 AftrTrtmntOtltGsSnsrHtrPrlmnryFM 3232;
BA_ "SigType" SG_ 2565869566 AftrTrtmntOtltWdRngO2RdngStable "DISCRETE";
BA_ "SPN" SG_ 2565869566 AftrTrtmntOtltWdRngO2RdngStable 3231;
BA_ "SigType" SG_ 2565869566 AftrTrtmntOtletNOxReadingStable "DISCRETE";
BA_ "SPN" SG_ 2565869566 AftrTrtmntOtletNOxReadingStable 3230;
BA_ "SigType" SG_ 2565869566 AftrTrtmntOutletGasSensorAtTemp "DISCRETE";
BA_ "SPN" SG_ 2565869566 AftrTrtmntOutletGasSensorAtTemp 3229;
BA_ "SigType" SG_ 2565869566 AftrTrtmntOtltGsSnsrPwerInRange "DISCRETE";
BA_ "SPN" SG_ 2565869566 AftrTrtmntOtltGsSnsrPwerInRange 3228;
BA_ "SigType" SG_ 2565869566 AfterTreatmentOutletO2 "RANGE";
BA_ "SPN" SG_ 2565869566 AfterTreatmentOutletO2 3227;
BA_ "SigType" SG_ 2565869566 AfterTreatmentOutletNOx "RANGE";
BA_ "SPN" SG_ 2565869566 AfterTreatmentOutletNOx 3226;
BA_ "SigType" SG_ 2565870078 AftrTrtmntOtltOxygnSnsrPrlmnryFM "RANGE";
BA_ "SPN" SG_ 2565870078 AftrTrtmntOtltOxygnSnsrPrlmnryFM 3235;
BA_ "SigType" SG_ 2565870078 AftrTrtmntOtltNOxSnsrPrlmnryFMI "RANGE";
BA_ "SPN" SG_ 2565870078 AftrTrtmntOtltNOxSnsrPrlmnryFMI 3234;
BA_ "SigType" SG_ 2565870078 AftrTrtmntOtltGsSnsorHeaterCtrl "DISCRETE";
BA_ "SPN" SG_ 2565870078 AftrTrtmntOtltGsSnsorHeaterCtrl 3233;
BA_ "SigType" SG_ 2565870078 AftrTrtmntOtltGsSnsrHtrPrlmnryFM "RANGE";
BA_ "SPN" SG_ 2565870078 AftrTrtmntOtltGsSnsrHtrPrlmnryFM 3232;
BA_ "SigType" SG_ 2565870078 AftrTrtmntOtltWdRngO2RdngStable "DISCRETE";
BA_ "SPN" SG_ 2565870078 AftrTrtmntOtltWdRngO2RdngStable 3231;
BA_ "SigType" SG_ 2565870078 AftrTrtmntOtletNOxReadingStable "DISCRETE";
BA_ "SPN" SG_ 2565870078 AftrTrtmntOtletNOxReadingStable 3230;
BA_ "SigType" SG_ 2565870078 AftrTrtmntOutletGasSensorAtTemp "DISCRETE";
BA_ "SPN" SG_ 2565870078 AftrTrtmntOutletGasSensorAtTemp 3229;
BA_ "SigType" SG_ 2565870078 AftrTrtmntOtltGsSnsrPwerInRange "DISCRETE";
BA_ "SPN" SG_ 2565870078 AftrTrtmntOtltGsSnsrPwerInRange 3228;
BA_ "SigType" SG_ 2565870078 AfterTreatmentOutletO2 "RANGE";
BA_ "SPN" SG_ 2565870078 AfterTreatmentOutletO2 3227;
BA_ "SigType" SG_ 2565870078 AfterTreatmentOutletNOx "RANGE";
BA_ "SPN" SG_ 2565870078 AfterTreatmentOutletNOx 3226;
BA_ "SigType" SG_ 2566763518 PrtcltTrpOtltExhstGsTmpPrlmnryFM "RANGE";
BA_ "SPN" SG_ 2566763518 PrtcltTrpOtltExhstGsTmpPrlmnryFM 3248;
BA_ "SigType" SG_ 2566763518 ExhaustGasTemp3PreliminaryFMI "RANGE";
BA_ "SPN" SG_ 2566763518 ExhaustGasTemp3PreliminaryFMI 3247;
BA_ "SigType" SG_ 2566763518 ParticulateTrapOutletGasTemp "RANGE";
BA_ "SPN" SG_ 2566763518 ParticulateTrapOutletGasTemp 3246;
BA_ "SigType" SG_ 2566763518 ExhaustGasTemp3 "RANGE";
BA_ "SPN" SG_ 2566763518 ExhaustGasTemp3 3245;
BA_ "SigType" SG_ 2566762750 PrtcltTrpExhstGsTmpPrlminaryFMI "RANGE";
BA_ "SPN" SG_ 2566762750 PrtcltTrpExhstGsTmpPrlminaryFMI 3282;
BA_ "SigType" SG_ 2566762750 ExhaustGasTemp3PreliminaryFMI "RANGE";
BA_ "SPN" SG_ 2566762750 ExhaustGasTemp3PreliminaryFMI 3247;
BA_ "SigType" SG_ 2566762750 ParticulateTrapOutletGasTemp "RANGE";
BA_ "SPN" SG_ 2566762750 ParticulateTrapOutletGasTemp 3246;
BA_ "SigType" SG_ 2566762750 ExhaustGasTemp3 "RANGE";
BA_ "SPN" SG_ 2566762750 ExhaustGasTemp3 3245;
BA_ "SigType" SG_ 2566803198 Status2OfDoors "DISCRETE";
BA_ "SPN" SG_ 2566803198 Status2OfDoors 3411;
BA_ "SigType" SG_ 2566803198 Ramp_WheelChairLiftPos "DISCRETE";
BA_ "SPN" SG_ 2566803198 Ramp_WheelChairLiftPos 1820;
BA_ "SigType" SG_ 2566803198 PosOfDoors "DISCRETE";
BA_ "SPN" SG_ 2566803198 PosOfDoors 1821;
BA_ "SigType" SG_ 2565870334 FifthWheelRollWarningIndicator "DISCRETE";
BA_ "SPN" SG_ 2565870334 FifthWheelRollWarningIndicator 3317;
BA_ "SigType" SG_ 2565870334 FifthWheelRollMoment "RANGE";
BA_ "SPN" SG_ 2565870334 FifthWheelRollMoment 3310;
BA_ "SigType" SG_ 2565870334 FifthWheelDrawbarForce "RANGE";
BA_ "SPN" SG_ 2565870334 FifthWheelDrawbarForce 3309;
BA_ "SigType" SG_ 2565870334 FifthWheelVerticalForce "RANGE";
BA_ "SPN" SG_ 2565870334 FifthWheelVerticalForce 3308;
BA_ "SigType" SG_ 2566762238 FifthWheelSliderLockIndicator "DISCRETE";
BA_ "SPN" SG_ 2566762238 FifthWheelSliderLockIndicator 3316;
BA_ "SigType" SG_ 2566762238 FifthWheelSliderPos "RANGE";
BA_ "SPN" SG_ 2566762238 FifthWheelSliderPos 3311;
BA_ "SigType" SG_ 2566762238 FfthWhlLckCoupleStatusIndicator "DISCRETE";
BA_ "SPN" SG_ 2566762238 FfthWhlLckCoupleStatusIndicator 3313;
BA_ "SigType" SG_ 2566762238 FfthWhlLckRadyToCoupleIndicator "DISCRETE";
BA_ "SPN" SG_ 2566762238 FfthWhlLckRadyToCoupleIndicator 3312;
BA_ "SigType" SG_ 2566762238 FifthWheelErrorStatus "DISCRETE";
BA_ "SPN" SG_ 2566762238 FifthWheelErrorStatus 3307;
BA_ "SigType" SG_ 2364543998 RollAndPitchMeasurementLatency "RANGE";
BA_ "SPN" SG_ 2364543998 RollAndPitchMeasurementLatency 3327;
BA_ "SigType" SG_ 2364543998 PitchAndRollCompensated "DISCRETE";
BA_ "SPN" SG_ 2364543998 PitchAndRollCompensated 3326;
BA_ "SigType" SG_ 2364543998 PitchRateFigureOfMerit "DISCRETE";
BA_ "SPN" SG_ 2364543998 PitchRateFigureOfMerit 3325;
BA_ "SigType" SG_ 2364543998 RollAngleFigureOfMerit "DISCRETE";
BA_ "SPN" SG_ 2364543998 RollAngleFigureOfMerit 3324;
BA_ "SigType" SG_ 2364543998 PitchAngleFigureOfMerit "DISCRETE";
BA_ "SPN" SG_ 2364543998 PitchAngleFigureOfMerit 3323;
BA_ "SigType" SG_ 2364543998 PitchRate "RANGE";
BA_ "SPN" SG_ 2364543998 PitchRate 3322;
BA_ "SigType" SG_ 2364543998 RollAngle "RANGE";
BA_ "SPN" SG_ 2364543998 RollAngle 3319;
BA_ "SigType" SG_ 2364543998 PitchAngle "RANGE";
BA_ "SPN" SG_ 2364543998 PitchAngle 3318;
BA_ "SigType" SG_ 2566846718 TransOilLevelMeasurementStatus "DISCRETE";
BA_ "SPN" SG_ 2566846718 TransOilLevelMeasurementStatus 3026;
BA_ "SigType" SG_ 2566846718 TransOilLevelCountdownTimer "DISCRETE";
BA_ "SPN" SG_ 2566846718 TransOilLevelCountdownTimer 3028;
BA_ "SigType" SG_ 2566846718 TransOilLevelHigh_Low "RANGE";
BA_ "SPN" SG_ 2566846718 TransOilLevelHigh_Low 3027;
BA_ "SigType" SG_ 2566846718 TransOilTemp "RANGE";
BA_ "SPN" SG_ 2566846718 TransOilTemp 177;
BA_ "SigType" SG_ 2566846718 TransOilPress "RANGE";
BA_ "SPN" SG_ 2566846718 TransOilPress 127;
BA_ "SigType" SG_ 2566846718 TransFilterDiffPress "RANGE";
BA_ "SPN" SG_ 2566846718 TransFilterDiffPress 126;
BA_ "SigType" SG_ 2566846718 TransOilLevel "RANGE";
BA_ "SPN" SG_ 2566846718 TransOilLevel 124;
BA_ "SigType" SG_ 2566846718 ClutchPress "RANGE";
BA_ "SPN" SG_ 2566846718 ClutchPress 123;
BA_ "SigType" SG_ 2566846462 BatteryPotentialSwitched "RANGE";
BA_ "SPN" SG_ 2566846462 BatteryPotentialSwitched 158;
BA_ "SigType" SG_ 2566846462 ElectricalPotential "RANGE";
BA_ "SPN" SG_ 2566846462 ElectricalPotential 168;
BA_ "SigType" SG_ 2566846462 ChargingSystemPotential "RANGE";
BA_ "SPN" SG_ 2566846462 ChargingSystemPotential 167;
BA_ "SigType" SG_ 2566846462 AltCurrent "RANGE";
BA_ "SPN" SG_ 2566846462 AltCurrent 115;
BA_ "SigType" SG_ 2566846462 NetBatteryCurrent "RANGE";
BA_ "SPN" SG_ 2566846462 NetBatteryCurrent 114;
BA_ "SigType" SG_ 2566760702 WrlessCommunicationNetworkType2 "RANGE";
BA_ "SPN" SG_ 2566760702 WrlessCommunicationNetworkType2 3446;
BA_ "SigType" SG_ 2566760702 NetworkSignalStrength2 "RANGE";
BA_ "SPN" SG_ 2566760702 NetworkSignalStrength2 3445;
BA_ "SigType" SG_ 2566760702 NetworkAntennaStatus2 "RANGE";
BA_ "SPN" SG_ 2566760702 NetworkAntennaStatus2 3444;
BA_ "SigType" SG_ 2566760702 NetworkServiceStatus2 "RANGE";
BA_ "SPN" SG_ 2566760702 NetworkServiceStatus2 3443;
BA_ "SigType" SG_ 2566760702 NetworkTransceiverStatus2 "RANGE";
BA_ "SPN" SG_ 2566760702 NetworkTransceiverStatus2 3442;
BA_ "SigType" SG_ 2566760958 WrlessCommunicationNetworkType1 "RANGE";
BA_ "SPN" SG_ 2566760958 WrlessCommunicationNetworkType1 3372;
BA_ "SigType" SG_ 2566760958 NetworkSignalStrength1 "RANGE";
BA_ "SPN" SG_ 2566760958 NetworkSignalStrength1 3371;
BA_ "SigType" SG_ 2566760958 NetworkAntennaStatus1 "RANGE";
BA_ "SPN" SG_ 2566760958 NetworkAntennaStatus1 3370;
BA_ "SigType" SG_ 2566760958 NetworkServiceStatus1 "RANGE";
BA_ "SPN" SG_ 2566760958 NetworkServiceStatus1 3369;
BA_ "SigType" SG_ 2566760958 NetworkTransceiverStatus1 "RANGE";
BA_ "SPN" SG_ 2566760958 NetworkTransceiverStatus1 3368;
BA_ "SigType" SG_ 2633869310 VoltageRegulatorEnabled "DISCRETE";
BA_ "SPN" SG_ 2633869310 VoltageRegulatorEnabled 3379;
BA_ "SigType" SG_ 2633869310 VoltageRegulatorSoftStartState "DISCRETE";
BA_ "SPN" SG_ 2633869310 VoltageRegulatorSoftStartState 3378;
BA_ "SigType" SG_ 2633869310 VltgRgltrUndrfrqncyCmpnstnEnbld "DISCRETE";
BA_ "SPN" SG_ 2633869310 VltgRgltrUndrfrqncyCmpnstnEnbld 3377;
BA_ "SigType" SG_ 2633869310 VltgRgltrVAr_PwrFctrOprtingMode "DISCRETE";
BA_ "SPN" SG_ 2633869310 VltgRgltrVAr_PwrFctrOprtingMode 3376;
BA_ "SigType" SG_ 2633869310 VltgRglatorLoadCompensationMode "DISCRETE";
BA_ "SPN" SG_ 2633869310 VltgRglatorLoadCompensationMode 3375;
BA_ "SigType" SG_ 2365433598 GnrtrOtputVoltageBiasPercentage "RANGE";
BA_ "SPN" SG_ 2365433598 GnrtrOtputVoltageBiasPercentage 3382;
BA_ "SigType" SG_ 2365433598 GeneratorExcitationFieldCurrent "RANGE";
BA_ "SPN" SG_ 2365433598 GeneratorExcitationFieldCurrent 3381;
BA_ "SigType" SG_ 2365433598 GeneratorExcitationFieldVoltage "RANGE";
BA_ "SPN" SG_ 2365433598 GeneratorExcitationFieldVoltage 3380;
VAL_ 2566764542 FailureModeIdentifier1 31 "Not available" 19 "Received network data in error" 18 "Below normal (moderately severe)" 17 "Below normal (least severe)" 16 "Above normal (moderately severe)" 15 "Above normal (least severe)" 14 "Special intstructions" 13 "Out of calibration" 12 "Bad intelligent device" 11 "Root cause not known" 10 "Abnormal rate of change" 9 "Abnormal update rate" 8 "Abnormal frequency" 7 "Mechanical system not responding" 6 "Current above normal" 5 "Current below normal" 4 "Voltage below normal" 3 "Voltage above normal" 2 "Data erratic" 1 "Below normal (most severe)" 0 "Above normal (most severe)" ;
VAL_ 2566764286 SPNSupportTypeSTR3 1 "NotSupportedInScaledTestResults" 0 "SupportedInScaledTestResults" ;
VAL_ 2566764286 SPNSupportTypeSTR2 1 "NotSupportedInScaledTestResults" 0 "SupportedInScaledTestResults" ;
VAL_ 2566764286 SPNSupportTypeEFF3 1 "NotSupportedInExFreezeFrame" 0 "SupportedInExFreezeFrame" ;
VAL_ 2566764286 SPNSupportTypeEFF2 1 "NotSupportedInExFreezeFrame" 0 "SupportedInExFreezeFrame" ;
VAL_ 2566764286 SPNSupportTypeDS3 1 "NotSupportedInDataStream" 0 "SupportedInDataStream" ;
VAL_ 2566764286 SPNSupportTypeDS2 1 "NotSupportedInDataStream" 0 "SupportedInDataStream" ;
VAL_ 2566764286 SPNSupportTypeSTR1 1 "NotSupportedInScaledTestResults" 0 "SupportedInScaledTestResults" ;
VAL_ 2566764286 SPNSupportTypeDS1 1 "NotSupportedInDataStream" 0 "SupportedInDataStream" ;
VAL_ 2566764286 SPNSupportTypeEFF1 1 "NotSupportedInExFreezeFrame" 0 "SupportedInExFreezeFrame" ;
VAL_ 2555576062 FlashRedStopLamp 3 "Unavailable / Do Not Flash" 2 "Reserved" 1 "Fast Flash" 0 "Slow Flash" ;
VAL_ 2555576062 FlashProtectLamp 3 "Unavailable / Do Not Flash" 2 "Reserved" 1 "Fast Flash" 0 "Slow Flash" ;
VAL_ 2555576062 FlashMalfuncIndicatorLamp 3 "Unavailable / Do Not Flash" 2 "Reserved" 1 "Fast Flash" 0 "Slow Flash" ;
VAL_ 2555576062 FlashAmberWarningLamp 3 "Unavailable / Do Not Flash" 2 "Reserved" 1 "Fast Flash" 0 "Slow Flash" ;
VAL_ 2555576062 FailureModeIdentifier5 31 "Not available" 19 "Received network data in error" 18 "Below normal (moderately severe)" 17 "Below normal (least severe)" 16 "Above normal (moderately severe)" 15 "Above normal (least severe)" 14 "Special intstructions" 13 "Out of calibration" 12 "Bad intelligent device" 11 "Root cause not known" 10 "Abnormal rate of change" 9 "Abnormal update rate" 8 "Abnormal frequency" 7 "Mechanical system not responding" 6 "Current above normal" 5 "Current below normal" 4 "Voltage below normal" 3 "Voltage above normal" 2 "Data erratic" 1 "Below normal (most severe)" 0 "Above normal (most severe)" ;
VAL_ 2555576062 FailureModeIdentifier4 31 "Not available" 19 "Received network data in error" 18 "Below normal (moderately severe)" 17 "Below normal (least severe)" 16 "Above normal (moderately severe)" 15 "Above normal (least severe)" 14 "Special intstructions" 13 "Out of calibration" 12 "Bad intelligent device" 11 "Root cause not known" 10 "Abnormal rate of change" 9 "Abnormal update rate" 8 "Abnormal frequency" 7 "Mechanical system not responding" 6 "Current above normal" 5 "Current below normal" 4 "Voltage below normal" 3 "Voltage above normal" 2 "Data erratic" 1 "Below normal (most severe)" 0 "Above normal (most severe)" ;
VAL_ 2555576062 FailureModeIdentifier1 31 "Not available" 19 "Received network data in error" 18 "Below normal (moderately severe)" 17 "Below normal (least severe)" 16 "Above normal (moderately severe)" 15 "Above normal (least severe)" 14 "Special intstructions" 13 "Out of calibration" 12 "Bad intelligent device" 11 "Root cause not known" 10 "Abnormal rate of change" 9 "Abnormal update rate" 8 "Abnormal frequency" 7 "Mechanical system not responding" 6 "Current above normal" 5 "Current below normal" 4 "Voltage below normal" 3 "Voltage above normal" 2 "Data erratic" 1 "Below normal (most severe)" 0 "Above normal (most severe)" ;
VAL_ 2555576062 MalfunctionIndicatorLampStatus 3 "Not available" 2 "Reserved" 1 "Lamp on" 0 "Lamp off" ;
VAL_ 2555576062 RedStopLampState 3 "Not available" 2 "Reserved" 1 "Lamp on" 0 "Lamp off" ;
VAL_ 2555576062 AmberWarningLampStatus 3 "Not available" 2 "Reserved" 1 "Lamp on" 0 "Lamp off" ;
VAL_ 2555576062 ProtectLampStatus 3 "Not available" 2 "Reserved" 1 "Lamp on" 0 "Lamp off" ;
VAL_ 2555576062 FailureModeIdentifier3 31 "Not available" 19 "Received network data in error" 18 "Below normal (moderately severe)" 17 "Below normal (least severe)" 16 "Above normal (moderately severe)" 15 "Above normal (least severe)" 14 "Special intstructions" 13 "Out of calibration" 12 "Bad intelligent device" 11 "Root cause not known" 10 "Abnormal rate of change" 9 "Abnormal update rate" 8 "Abnormal frequency" 7 "Mechanical system not responding" 6 "Current above normal" 5 "Current below normal" 4 "Voltage below normal" 3 "Voltage above normal" 2 "Data erratic" 1 "Below normal (most severe)" 0 "Above normal (most severe)" ;
VAL_ 2555576062 FailureModeIdentifier2 31 "Not available" 19 "Received network data in error" 18 "Below normal (moderately severe)" 17 "Below normal (least severe)" 16 "Above normal (moderately severe)" 15 "Above normal (least severe)" 14 "Special intstructions" 13 "Out of calibration" 12 "Bad intelligent device" 11 "Root cause not known" 10 "Abnormal rate of change" 9 "Abnormal update rate" 8 "Abnormal frequency" 7 "Mechanical system not responding" 6 "Current above normal" 5 "Current below normal" 4 "Voltage below normal" 3 "Voltage above normal" 2 "Data erratic" 1 "Below normal (most severe)" 0 "Above normal (most severe)" ;
VAL_ 2562981630 FailureModeIdentifier1 31 "Not available" 19 "Received network data in error" 18 "Below normal (moderately severe)" 17 "Below normal (least severe)" 16 "Above normal (moderately severe)" 15 "Above normal (least severe)" 14 "Special intstructions" 13 "Out of calibration" 12 "Bad intelligent device" 11 "Root cause not known" 10 "Abnormal rate of change" 9 "Abnormal update rate" 8 "Abnormal frequency" 7 "Mechanical system not responding" 6 "Current above normal" 5 "Current below normal" 4 "Voltage below normal" 3 "Voltage above normal" 2 "Data erratic" 1 "Below normal (most severe)" 0 "Above normal (most severe)" ;
VAL_ 2566835198 FailureModeIdentifier5 31 "Not available" 19 "Received network data in error" 18 "Below normal (moderately severe)" 17 "Below normal (least severe)" 16 "Above normal (moderately severe)" 15 "Above normal (least severe)" 14 "Special intstructions" 13 "Out of calibration" 12 "Bad intelligent device" 11 "Root cause not known" 10 "Abnormal rate of change" 9 "Abnormal update rate" 8 "Abnormal frequency" 7 "Mechanical system not responding" 6 "Current above normal" 5 "Current below normal" 4 "Voltage below normal" 3 "Voltage above normal" 2 "Data erratic" 1 "Below normal (most severe)" 0 "Above normal (most severe)" ;
VAL_ 2566835198 FailureModeIdentifier4 31 "Not available" 19 "Received network data in error" 18 "Below normal (moderately severe)" 17 "Below normal (least severe)" 16 "Above normal (moderately severe)" 15 "Above normal (least severe)" 14 "Special intstructions" 13 "Out of calibration" 12 "Bad intelligent device" 11 "Root cause not known" 10 "Abnormal rate of change" 9 "Abnormal update rate" 8 "Abnormal frequency" 7 "Mechanical system not responding" 6 "Current above normal" 5 "Current below normal" 4 "Voltage below normal" 3 "Voltage above normal" 2 "Data erratic" 1 "Below normal (most severe)" 0 "Above normal (most severe)" ;
VAL_ 2566835198 FailureModeIdentifier1 31 "Not available" 19 "Received network data in error" 18 "Below normal (moderately severe)" 17 "Below normal (least severe)" 16 "Above normal (moderately severe)" 15 "Above normal (least severe)" 14 "Special intstructions" 13 "Out of calibration" 12 "Bad intelligent device" 11 "Root cause not known" 10 "Abnormal rate of change" 9 "Abnormal update rate" 8 "Abnormal frequency" 7 "Mechanical system not responding" 6 "Current above normal" 5 "Current below normal" 4 "Voltage below normal" 3 "Voltage above normal" 2 "Data erratic" 1 "Below normal (most severe)" 0 "Above normal (most severe)" ;
VAL_ 2566835198 MalfunctionIndicatorLampStatus 3 "Not available" 2 "Reserved" 1 "Lamp on" 0 "Lamp off" ;
VAL_ 2566835198 RedStopLampState 3 "Not available" 2 "Reserved" 1 "Lamp on" 0 "Lamp off" ;
VAL_ 2566835198 AmberWarningLampStatus 3 "Not available" 2 "Reserved" 1 "Lamp on" 0 "Lamp off" ;
VAL_ 2566835198 ProtectLampStatus 3 "Not available" 2 "Reserved" 1 "Lamp on" 0 "Lamp off" ;
VAL_ 2566835198 FailureModeIdentifier3 31 "Not available" 19 "Received network data in error" 18 "Below normal (moderately severe)" 17 "Below normal (least severe)" 16 "Above normal (moderately severe)" 15 "Above normal (least severe)" 14 "Special intstructions" 13 "Out of calibration" 12 "Bad intelligent device" 11 "Root cause not known" 10 "Abnormal rate of change" 9 "Abnormal update rate" 8 "Abnormal frequency" 7 "Mechanical system not responding" 6 "Current above normal" 5 "Current below normal" 4 "Voltage below normal" 3 "Voltage above normal" 2 "Data erratic" 1 "Below normal (most severe)" 0 "Above normal (most severe)" ;
VAL_ 2566835198 FlashRedStopLamp 3 "Unavailable / Do Not Flash" 2 "Reserved" 1 "Fast Flash" 0 "Slow Flash" ;
VAL_ 2566835198 FlashProtectLamp 3 "Unavailable / Do Not Flash" 2 "Reserved" 1 "Fast Flash" 0 "Slow Flash" ;
VAL_ 2566835198 FlashMalfuncIndicatorLamp 3 "Unavailable / Do Not Flash" 2 "Reserved" 1 "Fast Flash" 0 "Slow Flash" ;
VAL_ 2566835198 FlashAmberWarningLamp 3 "Unavailable / Do Not Flash" 2 "Reserved" 1 "Fast Flash" 0 "Slow Flash" ;
VAL_ 2566835198 FailureModeIdentifier2 31 "Not available" 19 "Received network data in error" 18 "Below normal (moderately severe)" 17 "Below normal (least severe)" 16 "Above normal (moderately severe)" 15 "Above normal (least severe)" 14 "Special intstructions" 13 "Out of calibration" 12 "Bad intelligent device" 11 "Root cause not known" 10 "Abnormal rate of change" 9 "Abnormal update rate" 8 "Abnormal frequency" 7 "Mechanical system not responding" 6 "Current above normal" 5 "Current below normal" 4 "Voltage below normal" 3 "Voltage above normal" 2 "Data erratic" 1 "Below normal (most severe)" 0 "Above normal (most severe)" ;
VAL_ 2564357886 Seed 255 "NoFurtherKeyRequiredOfTool" 1 "UseLongSeedOrKeyFromDataSecMsg" 0 "SeedCompleted_BeginSendingKey" ;
VAL_ 2564357886 EDCP_Extension 9 "DataInErrIndAndDataInSeedIsTime" 6 "DataInErrorIndicator" 3 "ConcatenateDataAsLowerEDCParam" 2 "ConcatenateDataAsHigherEDCParam" 0 "Completed" 255 "NoErrIndicator/EDCParamAvailable" ;
VAL_ 2564357886 ErrorIndicator 16777215 "NoErrorIndicatorAvailable" 65540 "TransprtNotComplWithinTimeAllowd" 65539 "TransportNotInitWithinTimeAllowd" 65538 "NoResponseInTheTimeAllowed" 65537 "ModuleExceedingNumberOfRetries" 65536 "AbortFromExtToNormalSoftwareProc" 4103 "VehicleNotInParkOrNotStationary" 4102 "EngineRunning" 4101 "NotInEngineeringOrDevelopmentMode" 4100 "NotInDiagnosticMode" 4099 "InvalidKey" 4098 "InvalidUserLevel" 4097 "InvalidPassword" 4096 "SecurityErrorGeneral" 266 "NameDoesNotConformToExpectdValue" 265 "DataDoesNotConformToValueRanges" 264 "AddrForBootLoadExeInvalidBoundary" 263 "AddrForBootLoadExeOutsideExeMem" 262 "OpReqExeTransfAndEraseOfProgMem" 261 "OpRequiresPriorEraseOfProgramMem" 260 "OpRequiresPriorEraseOfDataMem" 259 "ReqMemoryExceededAvailableMemory" 258 "LengthNotValidForMemStructAndOp" 257 "AddressNotOnValidBoundary" 256 "AddressingOrDataGeneralError" 36 "InternalFailurePreventingReq" 35 "PROMDidNotVerifyOnWrite" 34 "FLASHDidNotVerifyOnWrite" 33 "RAMDidNotVerifyOnWrite" 32 "EDCParaNotCorrectForDataStream" 31 "ProcessUnspecReqFromThisAddress" 23 "ProcessingEDCPGenerationReq" 22 "ProcessingBootLoadReq" 19 "ProcessingStatusReq" 18 "ProcessingWriteReq" 17 "ProcessingReadReq" 16 "ProcessingEraseReq" 2 "ProcessingForSomeoneElse" 1 "ErrorNotIdentified" 0 "NoError" ;
VAL_ 2564357886 Status 7 "Reserved" 6 "Reserved" 5 "OperationFailed" 4 "OperationCompleted" 3 "Reserved" 2 "Reserved" 1 "Busy" 0 "Proceed" ;
VAL_ 2564423422 KeyOrUserLevel 65535 "NoKeyAvailable" 0 "UseLongSeedOrKey" ;
VAL_ 2564423422 PointerExtension 0 "SPN_SPACE" ;
VAL_ 2564423422 Command 7 "EDCP_Generation" 6 "BootLoad" 5 "OperationFailed" 4 "OperationCompleted" 3 "StatusRequest" 2 "Write" 1 "Read" 0 "Erase" ;
VAL_ 2564423422 PointerType 1 "DirectedSpatialAddressing" 0 "DirectMemoryAddressing" ;
VAL_ 2564816638 HoldSignal 15 "Not available" 1 "Devices whose broadcast state ha" 0 "All devices" ;
VAL_ 2564816638 J1939Network3 3 "Don't care" 2 "Reserved" 1 "Start broadcast" 0 "Stop broadcast" ;
VAL_ 2564816638 J1939Network2 3 "Don't care" 2 "Reserved" 1 "Start broadcast" 0 "Stop broadcast" ;
VAL_ 2564816638 ISO9141 3 "Don't care" 2 "Reserved" 1 "Start broadcast" 0 "Stop broadcast" ;
VAL_ 2564816638 SAE_J1850 3 "Don't care" 2 "Reserved" 1 "Start broadcast" 0 "Stop broadcast" ;
VAL_ 2564816638 ManufacturerSpecificPort 3 "Don't care" 2 "Reserved" 1 "Start broadcast" 0 "Stop broadcast" ;
VAL_ 2564816638 CurrentDataLink 3 "Don't care" 2 "Reserved" 1 "Start broadcast" 0 "Stop broadcast" ;
VAL_ 2564816638 SAE_J1587 3 "Don't care" 2 "Reserved" 1 "Start broadcast" 0 "Stop broadcast" ;
VAL_ 2564816638 SAE_J1922 3 "Don't care" 2 "Reserved" 1 "Start broadcast" 0 "Stop broadcast" ;
VAL_ 2564816638 J1939Network1 3 "Don't care" 2 "Reserved" 1 "Start broadcast" 0 "Stop broadcast" ;
VAL_ 2564816638 SuspendSignal 15 "NotAvailable" 14 "ResumingNormalBroadcastPattern" 3 "TemporarySuspensionOfSomeMessages" 2 "TemporarySuspensionOfAllBroadcasts" 1 "IndefiniteSuspensionOfSomeMessages" 0 "IndefiniteSuspensionOfAllBroadcasts" ;
VAL_ 2566837502 FlashRedStopLamp 3 "Unavailable / Do Not Flash" 2 "Reserved" 1 "Fast Flash" 0 "Slow Flash" ;
VAL_ 2566837502 FlashProtectLamp 3 "Unavailable / Do Not Flash" 2 "Reserved" 1 "Fast Flash" 0 "Slow Flash" ;
VAL_ 2566837502 FailureModeIdentifier5 31 "Not available" 19 "Received network data in error" 18 "Below normal (moderately severe)" 17 "Below normal (least severe)" 16 "Above normal (moderately severe)" 15 "Above normal (least severe)" 14 "Special intstructions" 13 "Out of calibration" 12 "Bad intelligent device" 11 "Root cause not known" 10 "Abnormal rate of change" 9 "Abnormal update rate" 8 "Abnormal frequency" 7 "Mechanical system not responding" 6 "Current above normal" 5 "Current below normal" 4 "Voltage below normal" 3 "Voltage above normal" 2 "Data erratic" 1 "Below normal (most severe)" 0 "Above normal (most severe)" ;
VAL_ 2566837502 FailureModeIdentifier4 31 "Not available" 19 "Received network data in error" 18 "Below normal (moderately severe)" 17 "Below normal (least severe)" 16 "Above normal (moderately severe)" 15 "Above normal (least severe)" 14 "Special intstructions" 13 "Out of calibration" 12 "Bad intelligent device" 11 "Root cause not known" 10 "Abnormal rate of change" 9 "Abnormal update rate" 8 "Abnormal frequency" 7 "Mechanical system not responding" 6 "Current above normal" 5 "Current below normal" 4 "Voltage below normal" 3 "Voltage above normal" 2 "Data erratic" 1 "Below normal (most severe)" 0 "Above normal (most severe)" ;
VAL_ 2566837502 FailureModeIdentifier3 31 "Not available" 19 "Received network data in error" 18 "Below normal (moderately severe)" 17 "Below normal (least severe)" 16 "Above normal (moderately severe)" 15 "Above normal (least severe)" 14 "Special intstructions" 13 "Out of calibration" 12 "Bad intelligent device" 11 "Root cause not known" 10 "Abnormal rate of change" 9 "Abnormal update rate" 8 "Abnormal frequency" 7 "Mechanical system not responding" 6 "Current above normal" 5 "Current below normal" 4 "Voltage below normal" 3 "Voltage above normal" 2 "Data erratic" 1 "Below normal (most severe)" 0 "Above normal (most severe)" ;
VAL_ 2566837502 FailureModeIdentifier1 31 "Not available" 19 "Received network data in error" 18 "Below normal (moderately severe)" 17 "Below normal (least severe)" 16 "Above normal (moderately severe)" 15 "Above normal (least severe)" 14 "Special intstructions" 13 "Out of calibration" 12 "Bad intelligent device" 11 "Root cause not known" 10 "Abnormal rate of change" 9 "Abnormal update rate" 8 "Abnormal frequency" 7 "Mechanical system not responding" 6 "Current above normal" 5 "Current below normal" 4 "Voltage below normal" 3 "Voltage above normal" 2 "Data erratic" 1 "Below normal (most severe)" 0 "Above normal (most severe)" ;
VAL_ 2566837502 MalfunctionIndicatorLampStatus 3 "Not available" 2 "Reserved" 1 "Lamp on" 0 "Lamp off" ;
VAL_ 2566837502 RedStopLampState 3 "Not available" 2 "Reserved" 1 "Lamp on" 0 "Lamp off" ;
VAL_ 2566837502 AmberWarningLampStatus 3 "Not available" 2 "Reserved" 1 "Lamp on" 0 "Lamp off" ;
VAL_ 2566837502 ProtectLampStatus 3 "Not available" 2 "Reserved" 1 "Lamp on" 0 "Lamp off" ;
VAL_ 2566837502 FlashMalfuncIndicatorLamp 3 "Unavailable / Do Not Flash" 2 "Reserved" 1 "Fast Flash" 0 "Slow Flash" ;
VAL_ 2566837502 FlashAmberWarningLamp 3 "Unavailable / Do Not Flash" 2 "Reserved" 1 "Fast Flash" 0 "Slow Flash" ;
VAL_ 2566837502 FailureModeIdentifier2 31 "Not available" 19 "Received network data in error" 18 "Below normal (moderately severe)" 17 "Below normal (least severe)" 16 "Above normal (moderately severe)" 15 "Above normal (least severe)" 14 "Special intstructions" 13 "Out of calibration" 12 "Bad intelligent device" 11 "Root cause not known" 10 "Abnormal rate of change" 9 "Abnormal update rate" 8 "Abnormal frequency" 7 "Mechanical system not responding" 6 "Current above normal" 5 "Current below normal" 4 "Voltage below normal" 3 "Voltage above normal" 2 "Data erratic" 1 "Below normal (most severe)" 0 "Above normal (most severe)" ;
VAL_ 2566834942 FailureModeIdentifier5 31 "Not available" 19 "Received network data in error" 18 "Below normal (moderately severe)" 17 "Below normal (least severe)" 16 "Above normal (moderately severe)" 15 "Above normal (least severe)" 14 "Special intstructions" 13 "Out of calibration" 12 "Bad intelligent device" 11 "Root cause not known" 10 "Abnormal rate of change" 9 "Abnormal update rate" 8 "Abnormal frequency" 7 "Mechanical system not responding" 6 "Current above normal" 5 "Current below normal" 4 "Voltage below normal" 3 "Voltage above normal" 2 "Data erratic" 1 "Below normal (most severe)" 0 "Above normal (most severe)" ;
VAL_ 2566834942 FailureModeIdentifier4 31 "Not available" 19 "Received network data in error" 18 "Below normal (moderately severe)" 17 "Below normal (least severe)" 16 "Above normal (moderately severe)" 15 "Above normal (least severe)" 14 "Special intstructions" 13 "Out of calibration" 12 "Bad intelligent device" 11 "Root cause not known" 10 "Abnormal rate of change" 9 "Abnormal update rate" 8 "Abnormal frequency" 7 "Mechanical system not responding" 6 "Current above normal" 5 "Current below normal" 4 "Voltage below normal" 3 "Voltage above normal" 2 "Data erratic" 1 "Below normal (most severe)" 0 "Above normal (most severe)" ;
VAL_ 2566834942 FailureModeIdentifier3 31 "Not available" 19 "Received network data in error" 18 "Below normal (moderately severe)" 17 "Below normal (least severe)" 16 "Above normal (moderately severe)" 15 "Above normal (least severe)" 14 "Special intstructions" 13 "Out of calibration" 12 "Bad intelligent device" 11 "Root cause not known" 10 "Abnormal rate of change" 9 "Abnormal update rate" 8 "Abnormal frequency" 7 "Mechanical system not responding" 6 "Current above normal" 5 "Current below normal" 4 "Voltage below normal" 3 "Voltage above normal" 2 "Data erratic" 1 "Below normal (most severe)" 0 "Above normal (most severe)" ;
VAL_ 2566834942 FlashRedStopLamp 3 "Unavailable / Do Not Flash" 2 "Reserved" 1 "Fast Flash" 0 "Slow Flash" ;
VAL_ 2566834942 FlashProtectLamp 3 "Unavailable / Do Not Flash" 2 "Reserved" 1 "Fast Flash" 0 "Slow Flash" ;
VAL_ 2566834942 FlashMalfuncIndicatorLamp 3 "Unavailable / Do Not Flash" 2 "Reserved" 1 "Fast Flash" 0 "Slow Flash" ;
VAL_ 2566834942 FlashAmberWarningLamp 3 "Unavailable / Do Not Flash" 2 "Reserved" 1 "Fast Flash" 0 "Slow Flash" ;
VAL_ 2566834942 MalfunctionIndicatorLampStatus 3 "Not available" 2 "Reserved" 1 "Lamp on" 0 "Lamp off" ;
VAL_ 2566834942 AmberWarningLampStatus 3 "Not available" 2 "Reserved" 1 "Lamp on" 0 "Lamp off" ;
VAL_ 2566834942 FailureModeIdentifier1 31 "Not available" 19 "Received network data in error" 18 "Below normal (moderately severe)" 17 "Below normal (least severe)" 16 "Above normal (moderately severe)" 15 "Above normal (least severe)" 14 "Special intstructions" 13 "Out of calibration" 12 "Bad intelligent device" 11 "Root cause not known" 10 "Abnormal rate of change" 9 "Abnormal update rate" 8 "Abnormal frequency" 7 "Mechanical system not responding" 6 "Current above normal" 5 "Current below normal" 4 "Voltage below normal" 3 "Voltage above normal" 2 "Data erratic" 1 "Below normal (most severe)" 0 "Above normal (most severe)" ;
VAL_ 2566834942 RedStopLampState 3 "Not available" 2 "Reserved" 1 "Lamp on" 0 "Lamp off" ;
VAL_ 2566834942 ProtectLampStatus 3 "Not available" 2 "Reserved" 1 "Lamp on" 0 "Lamp off" ;
VAL_ 2566834942 FailureModeIdentifier2 31 "Not available" 19 "Received network data in error" 18 "Below normal (moderately severe)" 17 "Below normal (least severe)" 16 "Above normal (moderately severe)" 15 "Above normal (least severe)" 14 "Special intstructions" 13 "Out of calibration" 12 "Bad intelligent device" 11 "Root cause not known" 10 "Abnormal rate of change" 9 "Abnormal update rate" 8 "Abnormal frequency" 7 "Mechanical system not responding" 6 "Current above normal" 5 "Current below normal" 4 "Voltage below normal" 3 "Voltage above normal" 2 "Data erratic" 1 "Below normal (most severe)" 0 "Above normal (most severe)" ;
VAL_ 2565668606 PGNumber 255 "NotAvailable" ;
VAL_ 2565668606 ControlByte 24 "EAbort" 23 "EEoMACK" 22 "EDPO" 21 "ECTS" 20 "ERTS" 3 "CannotRespond" 2 "AccessDenied" 1 "NACK" 0 "ACK" 255 "Abort" 32 "BAM" 19 "EoMA" 17 "CTS" 16 "RTS" ;
VAL_ 2563374846 UseTransferMode 3 "NA" 2 "Undefined" 1 "Yes" 0 "No" ;
VAL_ 2566827774 AirCompressorStatus 3 "NotAvailable" 2 "ErrorIndicator" 1 "CompressorActive" 0 "CompressorNotActive" ;
VAL_ 2566803966 RqedACCDistanceMode 7 "notAvailable" 6 "errorCondition" 5 "notDefined" 4 "RqedACCDistanceMode5" 3 "RqedACCDistanceMode4" 2 "RqedACCDistanceMode3" 1 "RqedACCDistanceMode2" 0 "RqedACCDistanceMode1" ;
VAL_ 2432593918 ACCDistanceAlertSignal 3 "TakeNoAction" 2 "Reserved" 1 "ACCDASActive" 0 "ACCDASNotActive" ;
VAL_ 2432593918 ACCSystemShutoffWarning 3 "TakeNoAction" 2 "Reserved" 1 "ACCSSOWActive" 0 "ACCSSOWNotActive" ;
VAL_ 2432593918 ACCTargetDetected 3 "TakeNoAction" 2 "Reserved" 1 "TargetDetected" 0 "NoTargetsDetected" ;
VAL_ 2432593918 AdptveCruiseCtrlSetDistanceMode 7 "NotAvailable_NotValid" 6 "ErrorCondition" 5 "ConventionalCruiseCtrlMode" 4 "ACCDistanceMode5" 3 "ACCDistanceMode4" 2 "ACCDistanceMode3" 1 "ACCDistanceMode2" 0 "ACCDistanceMode1" ;
VAL_ 2432593918 AdaptiveCruiseCtrlMode 7 "NotAvailable_NotValid" 6 "DsbldErrrCndtnUsdTIndctThtACCIs" 5 "FinishMode" 4 "HldMdUsdTIndctThtACCHsLstThPrvs" 3 "OvertakeMode" 2 "DstncCtrlActvUsdTIndctThtACCIsO" 1 "SpeedCtrlActive" 0 "OffUsdTIndctACCIsEnbldInClbCnfg" ;
VAL_ 2565406462 ControlByte 24 "EAbort" 23 "EEoMACK" 22 "EDPO" 21 "ECTS" 20 "ERTS" 3 "CannotRespond" 2 "AccessDenied" 1 "NACK" 0 "ACK" 255 "Abort" 32 "BAM" 19 "EoMA" 17 "CTS" 16 "RTS" ;
VAL_ 2566803198 Status2OfDoors 3 "notAvailable" 2 "error" 1 "atLeast1BusDoorEnabled" 0 "allBusDoorsAreDisabled" ;
VAL_ 2566803198 Ramp_WheelChairLiftPos 3 "NotAvailable" 2 "Error" 1 "OutsideBus" 0 "InsideBus" ;
VAL_ 2566803198 PosOfDoors 15 "NotAvailable" 14 "Error" 3 "1101NotDefined" 2 "AllDoorsClosed" 1 "ClosingLastDoor" 0 "AtLeast1DoorIsOpen" ;
VAL_ 2565870334 FifthWheelRollWarningIndicator 3 "NotAvailable" 2 "error" 1 "LimitExceeded" 0 "LimitNotExceeded" ;
VAL_ 2566762238 FifthWheelSliderLockIndicator 3 "NotAvailable" 2 "Error" 1 "Locked" 0 "NotLocked" ;
VAL_ 2566762238 FfthWhlLckCoupleStatusIndicator 3 "NotAvailable" 2 "Error" 1 "SuccessfulCoupleDetected" 0 "IncmpltBdCplTrckShuldNotBeMoved" ;
VAL_ 2566762238 FfthWhlLckRadyToCoupleIndicator 3 "NotAvailable" 2 "Error" 1 "LockOpenReadyToCouple" 0 "LockNotOpenNotReadyToCouple" ;
VAL_ 2566762238 FifthWheelErrorStatus 15 "NotAvailable" 9 "Kingpin_LockOpen" 8 "KingpinMissingMoreThan5Seconds" 7 "CouplingTimingError" 6 "CouplingSequenceError_Kingpin" 5 "CouplingSequenceError" 14 "NotUsed" 2 "Kingpin_LocksOpenAtStartup" 1 "LocksClosed_NoKingpinAtStartup" 0 "ImproperCouple" ;
VAL_ 2364543998 PitchAndRollCompensated 1 "NotAvailable" 0 "CompensationOn" ;
VAL_ 2364543998 PitchRateFigureOfMerit 1 "NotAvailable" 0 "PtchRtDgrddDtIsSspctDTEnvrnmntl" ;
VAL_ 2364543998 RollAngleFigureOfMerit 1 "NotAvailable" 0 "RllAnglDgrddDtIsSspctDTEnvrnmnt" ;
VAL_ 2364543998 PitchAngleFigureOfMerit 1 "NotAvailable" 0 "PtchAnglDgrddDtIsSspctDTEnvrnmn" ;
VAL_ 2566846718 TransOilLevelMeasurementStatus 15 "NotAvailable" 14 "Error" 13 "ConditionsNotValidOther" 12 "NotDefined" 8 "CndtionsNotValidEngSpeedTooHigh" 7 "CnditionsNotValidEngSpeedTooLow" 6 "CndtionsNotValidVehicleNotLevel" 5 "CndtnsNtVldVhclMvngOtptShftSpdT" 4 "CndtnsNtVldTrnsFluidTempTooHigh" 3 "CndtnsNtVldTransFluidTempTooLow" 2 "ConditionsNotValidTransInGear" 1 "CndtnsNtVldSttlngTmrStllCntngDw" 0 "CndtnsVldFrTrnsOlLvlMeasurement" ;
VAL_ 2566846718 TransOilLevelCountdownTimer 15 "NotAvailable" 14 "Error" 13 "ThirteenMinutes" 12 "TwelveMinutes" 11 "ElevenMinutes" 10 "TenMinutes" 9 "NineMinutes" 8 "EightMinutes" 7 "SevenMinutes" 6 "SixMinutes" 5 "FiveMinutes" 4 "FourMinutes" 3 "ThreeMinutes" 2 "TwoMinutes" 1 "OneMinute" 0 "lessThan1Minute" ;
VAL_ 2566760702 WrlessCommunicationNetworkType2 4 "Satellite network" 3 "Wireless LAN #2" 2 "Wireless LAN #1" 1 "CellularNetwork2" 0 "CellularNetwork1" ;
VAL_ 2566760702 NetworkAntennaStatus2 1 "On" 0 "Off" ;
VAL_ 2566760702 NetworkServiceStatus2 1 "RoamingService" 0 "LocalService" ;
VAL_ 2566760702 NetworkTransceiverStatus2 1 "On" 0 "Off" ;
VAL_ 2566760958 WrlessCommunicationNetworkType1 4 "Satellite network" 1 "CellularNetwork2" 0 "CellularNetwork1" 3 "Wireless LAN #2" 2 "Wireless LAN #1" ;
VAL_ 2566760958 NetworkAntennaStatus1 1 "On" 0 "Off" ;
VAL_ 2566760958 NetworkServiceStatus1 1 "RoamingService" 0 "LocalService" ;
VAL_ 2566760958 NetworkTransceiverStatus1 1 "On" 0 "Off" ;
VAL_ 2633869310 VoltageRegulatorEnabled 3 "NotAvailable" 2 "Error" 1 "RegulatingVoltage" 0 "NtRegulatingVoltageUnitDisabled" ;
VAL_ 2633869310 VoltageRegulatorSoftStartState 3 "NotAvailable" 2 "Error" 1 "SoftStartIsActive" 0 "SoftStartIsInactive" ;
VAL_ 2633869310 VltgRgltrUndrfrqncyCmpnstnEnbld 3 "NotAvailable" 2 "Error" 1 "UndrfrquencyCompensationEnabled" 0 "UndrfrqencyCompensationDisabled" ;
VAL_ 2633869310 VltgRgltrVAr_PwrFctrOprtingMode 7 "NotAvailable" 6 "Error" 5 "Reserved" 2 "VArRegulationEnabled" 1 "PowerFactorRegulationEnabled" 0 "VAr_PwrFactorRegulationDisabled" ;
VAL_ 2633869310 VltgRglatorLoadCompensationMode 7 "NotAvailable" 6 "Error" 5 "Reserved" 2 "IRLineDropCompensationEnabled" 1 "VoltageDroopCompensationEnabled" 0 "LoadCompensationDisabled" ;
